VERSION ""

NS_ :

BS_:

BU_: BATSYS XRCC BMC

BO_ 3221225472 VECTOR__INDEPENDENT_SIG_MSG: 0 Vector__XXX
 SG_ VRLACFG_AvgPowerPerWHr m1 : 39|12@1+ (1,0) [0|0] "" Vector__XXX
 SG_ VRLAM_fileTransferCommand m7 : 48|16@1+ (1,0) [0|0] "" Vector__XXX
 SG_ FWSend_BlockStart_Command : 0|8@1+ (1,0) [0|0] ""  XRCC,BMC
 SG_ FWSend_BlockFragment_Command : 0|4@1+ (1,0) [0|0] ""  XRCC,BMC
 SG_ FWSend_BlockFragment_FragmentCou : 4|4@1+ (1,0) [0|15] ""  XRCC,BMC
 SG_ FWSend_BlockStart_BlockCounter : 8|16@1+ (1,0) [0|0] ""  XRCC,BMC
 SG_ FWSend_FileStart_FileSize : 4|20@1+ (1,0) [0|0] ""  XRCC,BMC
 SG_ FWSend_FileStart_BlockSize : 24|16@1+ (1,0) [0|0] ""  XRCC,BMC
 SG_ FWSend_BlockFragment_FragmentDat : 8|56@1+ (1,0) [0|0] ""  XRCC,BMC
 SG_ AUXREG_ChallengeTimeOut m0 : 24|8@1+ (1,0) [0|0] ""  XRCC,BMC
 SG_ CFGCMD_SN_3TO7BYTES m2 : 24|40@1+ (1,0) [0|0] ""  BMC
 SG_ CFGCMD_SN_8TO12BYTES m3 : 24|40@1+ (1,0) [0|0] ""  BMC
 SG_ CFGCMD_SN_LST4BYTES m4 : 24|32@1+ (1,0) [0|0] ""  BMC

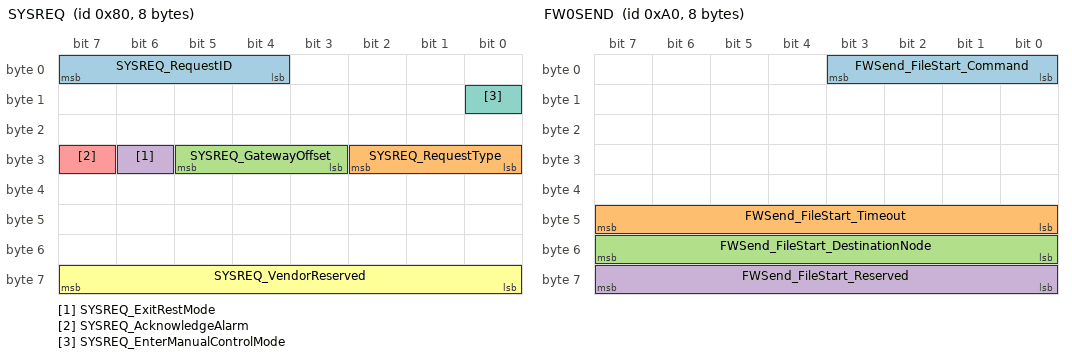
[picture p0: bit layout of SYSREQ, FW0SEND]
BO_ 128 SYSREQ: 8 BATSYS
 SG_ SYSREQ_RequestID : 4|4@1+ (1,0) [0|15] ""  BMC,XRCC
 SG_ SYSREQ_RequestType : 24|3@1+ (1,0) [0|0] ""  BMC,XRCC
 SG_ SYSREQ_GatewayOffset : 27|3@1+ (1,0) [0|0] ""  XRCC
 SG_ SYSREQ_ExitRestMode : 30|1@1+ (1,0) [0|1] ""  BMC
 SG_ SYSREQ_AcknowledgeAlarm : 31|1@1+ (1,0) [0|1] ""  BMC
 SG_ SYSREQ_VendorReserved : 56|8@1+ (1,0) [0|0] ""  BMC
 SG_ SYSREQ_EnterManualControlMode : 8|1@1+ (1,0) [0|1] ""  BMC

BO_ 256 VER: 8 BMC
 SG_ VER_Mux M : 0|4@1+ (1,0) [0|0] ""  BATSYS
 SG_ VER_ResponseID : 4|4@1+ (1,0) [0|15] ""  BATSYS
 SG_ VER_ProtocolVersion m1 : 8|8@1+ (1,0) [0|0] ""  BATSYS
 SG_ VER_SoftwareVersionMajor m1 : 16|8@1+ (1,0) [0|0] ""  BATSYS
 SG_ VER_SoftwareVersionMinor m1 : 24|8@1+ (1,0) [0|0] ""  BATSYS
 SG_ VER_SoftwareVersionBuild m1 : 32|8@1+ (1,0) [0|0] ""  BATSYS
 SG_ VER_InServiceDate m1 : 40|16@1+ (1,0) [0|0] ""  BATSYS
 SG_ VER_AttachedUPSSKU m1 : 56|8@1+ (1,0) [0|0] ""  BATSYS
 SG_ VER_ManufactureYear m2 : 8|7@1+ (1,2000) [0|0] ""  BATSYS
 SG_ VER_ManufactureDay m2 : 15|9@1+ (1,0) [0|366] "days"  BATSYS
 SG_ VER_ManufactureSerial m2 : 24|16@1+ (1,0) [0|0] ""  BATSYS
 SG_ VER_ManufactureDate m2 : 40|16@1+ (1,0) [0|65535] "days"  BATSYS
 SG_ VER_SerialNumber1 m3 : 16|48@1+ (1,0) [0|0] ""  BATSYS
 SG_ VER_SerialNumber2 m4 : 16|48@1+ (1,0) [0|0] ""  BATSYS
 SG_ VER_SerialNumber3 m5 : 16|32@1+ (1,0) [0|0] ""  BATSYS
 SG_ VER_PartNumber1 m6 : 16|48@1+ (1,0) [0|0] ""  BATSYS
 SG_ VER_PartNumber2 m7 : 16|48@1+ (1,0) [0|0] ""  BATSYS
 SG_ VER_PartNumber3 m8 : 16|32@1+ (1,0) [0|0] ""  BATSYS
 SG_ VER_SeriesConfiguration m9 : 8|8@1+ (1,0) [0|0] ""  BATSYS
 SG_ VER_ParallelConfiguration m9 : 16|8@1+ (1,0) [0|0] ""  BATSYS
 SG_ VER_DesignCapacity m9 : 24|12@1+ (1,0) [0|4094] "Whr"  BATSYS
 SG_ VER_DesignVoltage m9 : 36|9@1+ (1,0) [0|510] "volts"  BATSYS
 SG_ VER_DesignPower m9 : 48|16@1+ (1,0) [0|65534] "watts"  BATSYS
 SG_ VER_SoftwareAvailableMajor m10 : 8|8@1+ (1,0) [0|0] ""  BATSYS
 SG_ VER_SoftwareAvailableMinor m10 : 16|8@1+ (1,0) [0|0] ""  BATSYS
 SG_ VER_SoftwareAvailableBuild m10 : 24|8@1+ (1,0) [0|0] ""  BATSYS
 SG_ VER_BmFileTransferInIdle m10 : 32|1@1+ (1,0) [0|1] "flag"  BATSYS
 SG_ VER_BmFileTrsfrInPrgs m10 : 33|1@1+ (1,0) [0|1] "flag"  BATSYS
 SG_ VER_BmFileTransferInVerify m10 : 34|1@1+ (1,0) [0|1] "flag"  BATSYS
 SG_ VER_BmFileTrsfrReadyInstal m10 : 35|1@1+ (1,0) [0|1] "flag"  BATSYS
 SG_ VER_VendorCode m10 : 40|8@1+ (1,0) [0|0] ""  BATSYS
 SG_ VER_XrccFwVerString1 m11 : 8|56@1+ (1,0) [0|0] ""  BATSYS
 SG_ VER_XrccFwVerString2 m12 : 8|8@1+ (1,0) [0|0] ""  BATSYS
 SG_ VER_XrccAvlblFwVerString1 m12 : 16|48@1+ (1,0) [0|0] ""  BATSYS
 SG_ VER_XrccAvlblFwVerString2 m13 : 8|16@1+ (1,0) [0|0] ""  BATSYS

BO_ 512 MDAT: 8 BMC
 SG_ MDAT_Mux M : 0|4@1+ (1,0) [0|15] ""  BATSYS
 SG_ MDAT_ResponseID : 4|4@1+ (1,0) [0|15] ""  BATSYS
 SG_ MDAT_Reserved_01 m1 : 8|1@1+ (1,0) [0|1] "flag"  BATSYS
 SG_ MDAT_Reserved_02 m1 : 9|1@1+ (1,0) [0|1] "flag"  BATSYS
 SG_ MDAT_ShutdownImminent m1 : 10|1@1+ (1,0) [0|1] "flag"  BATSYS
 SG_ MDAT_NewFirmwareAvailable m1 : 11|1@1+ (1,0) [0|1] "flag"  BATSYS
 SG_ MDAT_RemainingCapacity m1 : 12|12@1+ (1,0) [0|4094] "Whr"  BATSYS
 SG_ MDAT_FullChargeCapacity m1 : 24|12@1+ (1,0) [0|4094] "Whr"  BATSYS
 SG_ MDAT_Voltage m1 : 36|12@1+ (0.1,0) [0|300] "volts"  BATSYS
 SG_ MDAT_Current m1 : 48|16@1+ (0.01,-325) [-325|325] "amps"  BATSYS
 SG_ MDAT_BatteryStatus m2 : 12|12@1+ (1,0) [0|1] ""  BATSYS
 SG_ MDAT_VCellMax m2 : 24|12@1+ (1,500) [500|4500] "mv"  BATSYS
 SG_ MDAT_VCellMin m2 : 36|12@1+ (1,500) [500|4500] "mv"  BATSYS
 SG_ MDAT_VCellAvg m2 : 48|12@1+ (1,500) [500|4500] "mv"  BATSYS
 SG_ MDAT_BatterySwitchOpen m2 : 60|1@1+ (1,0) [0|1] ""  BATSYS
 SG_ MDAT_TemperatureMax m3 : 16|8@1+ (1,-40) [-40|210] "deg C"  BATSYS
 SG_ MDAT_TemperatureMin m3 : 24|8@1+ (1,-40) [-40|210] "deg C"  BATSYS
 SG_ MDAT_TimeNow m3 : 32|32@1+ (0.5,0) [0|2147480000] "seconds"  BATSYS
 SG_ MDAT_VoltageBus m4 : 12|12@1+ (0.1,0) [0|300] "volts"  BATSYS
 SG_ MDAT_ChargeVoltageRequest m4 : 24|12@1+ (0.1,0) [0|300] "volts"  BATSYS
 SG_ MDAT_RunTimeCalRequired m4 : 36|1@1+ (1,0) [0|1] "flag"  BATSYS
 SG_ MDAT_RunTimeCalConditionMet m4 : 37|1@1+ (1,0) [0|1] "flag"  BATSYS
 SG_ MDAT_RTCalDischargeToLowSOC m4 : 38|1@1+ (1,0) [0|1] "flag"  BATSYS
 SG_ MDAT_RunTimeCalStayAtEmpty m4 : 39|1@1+ (1,0) [0|1] "flag"  BATSYS
 SG_ MDAT_RunTimeCalChargeToFull m4 : 40|1@1+ (1,0) [0|1] "flag"  BATSYS
 SG_ MDAT_RunTimeCalStayAtFull m4 : 41|1@1+ (1,0) [0|1] "flag"  BATSYS
 SG_ MDAT_RunTimeCalSuccess m4 : 42|1@1+ (1,0) [0|1] "flag"  BATSYS
 SG_ MDAT_RunTimeCalProcessing m4 : 43|1@1+ (1,0) [0|1] "flag"  BATSYS
 SG_ MDAT_RunTimeCalTimeout m4 : 44|1@1+ (1,0) [0|1] "flag"  BATSYS
 SG_ MDAT_ChargeCurrentMax m4 : 48|16@1+ (0.01,-325) [-325|325] "amps"  BATSYS
 SG_ MDAT_VolProtectionCov m5 : 16|1@1+ (1,0) [0|1] "flag"  BATSYS
 SG_ MDAT_VolProtectionPov m5 : 17|1@1+ (1,0) [0|1] "flag"  BATSYS
 SG_ MDAT_VolProtectionEocv m5 : 18|1@1+ (1,0) [0|1] "flag"  BATSYS
 SG_ MDAT_VolProtectionCuv m5 : 19|1@1+ (1,0) [0|1] "flag"  BATSYS
 SG_ MDAT_VolProtectionPuv m5 : 20|1@1+ (1,0) [0|1] "flag"  BATSYS
 SG_ MDAT_VolProtectionOimbv m5 : 21|1@1+ (1,0) [0|1] "flag"  BATSYS
 SG_ MDAT_CurProtectionOci m5 : 22|1@1+ (1,0) [0|1] "flag"  BATSYS
 SG_ MDAT_CurProtectionOdi_1 m5 : 23|1@1+ (1,0) [0|1] "flag"  BATSYS
 SG_ MDAT_CurProtectionOdi_2 m5 : 24|1@1+ (1,0) [0|1] "flag"  BATSYS
 SG_ MDAT_CurProtectionOdi_3 m5 : 25|1@1+ (1,0) [0|1] "flag"  BATSYS
 SG_ MDAT_CurProtectionOdi_4 m5 : 26|1@1+ (1,0) [0|1] "flag"  BATSYS
 SG_ MDAT_CurProtectionH_Odi m5 : 27|1@1+ (1,0) [0|1] "flag"  BATSYS
 SG_ MDAT_CurProtectionH_Sci m5 : 28|1@1+ (1,0) [0|1] "flag"  BATSYS
 SG_ MDAT_TemProtectionCot m5 : 29|1@1+ (1,0) [0|1] "flag"  BATSYS
 SG_ MDAT_TemProtectionDot m5 : 30|1@1+ (1,0) [0|1] "flag"  BATSYS
 SG_ MDAT_TemProtectionCut m5 : 31|1@1+ (1,0) [0|1] "flag"  BATSYS
 SG_ MDAT_TemProtectionDut m5 : 32|1@1+ (1,0) [0|1] "flag"  BATSYS
 SG_ MDAT_TemProtectionMot m5 : 33|1@1+ (1,0) [0|1] "flag"  BATSYS
 SG_ MDAT_FaultIndicateUvpf m5 : 34|1@1+ (1,0) [0|1] "flag"  BATSYS
 SG_ MDAT_FaultIndicateOvpf m5 : 35|1@1+ (1,0) [0|1] "flag"  BATSYS
 SG_ MDAT_FaultIndicateOtpf m5 : 36|1@1+ (1,0) [0|1] "flag"  BATSYS
 SG_ MDAT_FaultIndicateFusepf m5 : 37|1@1+ (1,0) [0|1] "flag"  BATSYS
 SG_ MDAT_FaultIndicateCimpf m5 : 38|1@1+ (1,0) [0|1] "flag"  BATSYS
 SG_ MDAT_FaultIndicateThopf m5 : 39|1@1+ (1,0) [0|1] "flag"  BATSYS
 SG_ MDAT_FaultIndicateThspf m5 : 40|1@1+ (1,0) [0|1] "flag"  BATSYS
 SG_ MDAT_FaultIndicateCfetpf m5 : 41|1@1+ (1,0) [0|1] "flag"  BATSYS
 SG_ MDAT_FaultIndicateDfetpf m5 : 42|1@1+ (1,0) [0|1] "flag"  BATSYS
 SG_ MDAT_UL60730_BQF m5 : 43|1@1+ (1,0) [0|1] "flag"  BATSYS
 SG_ MDAT_UL60730_MCU_IO_F m5 : 44|1@1+ (1,0) [0|1] "flag"  BATSYS
 SG_ MDAT_UL60730_MCU_CLK_F m5 : 45|1@1+ (1,0) [0|1] "flag"  BATSYS
 SG_ MDAT_UL60730_MCU_PC_F m5 : 46|1@1+ (1,0) [0|1] "flag"  BATSYS
 SG_ MDAT_UL60730_MCU_REG_F m5 : 47|1@1+ (1,0) [0|1] "flag"  BATSYS
 SG_ MDAT_UL60730_MCU_WDT_F m5 : 48|1@1+ (1,0) [0|1] "flag"  BATSYS
 SG_ MDAT_UL60730_MCU_RAM_F m5 : 49|1@1+ (1,0) [0|1] "flag"  BATSYS
 SG_ MDAT_UL60730_MCU_FLASH_F m5 : 50|1@1+ (1,0) [0|1] "flag"  BATSYS
 SG_ MDAT_UL60730_MCU_EE_F m5 : 51|1@1+ (1,0) [0|1] "flag"  BATSYS
 SG_ MDAT_GaugeCode m5 : 52|4@1+ (1,0) [0|16] ""  BATSYS
 SG_ MDAT_BmsState m5 : 56|8@1+ (1,0) [0|255] ""  BATSYS
 SG_ MDAT_TimeToFullCharge m6 : 16|16@1+ (1,0) [0|65535] ""  BATSYS
 SG_ MDAT_RemainingRunTime m6 : 32|16@1+ (1,0) [0|65535] ""  BATSYS
 SG_ MDAT_FanFault m6 : 48|1@1+ (1,0) [0|1] "flag"  BATSYS
 SG_ MDAT_TSensorDisconnected m6 : 49|1@1+ (1,0) [0|1] "flag"  BATSYS
 SG_ MDAT_ReplaceBatteryNow m6 : 50|1@1+ (1,0) [0|1] "flag"  BATSYS
 SG_ MDAT_ReplaceBPInNearFuture m6 : 51|1@1+ (1,0) [0|1] "flag"  BATSYS
 SG_ MDAT_A100xChipIssue m6 : 52|1@1+ (1,0) [0|1] "flag"  BATSYS
 SG_ MDAT_HardwareFault m6 : 53|1@1+ (1,0) [0|1] "flag"  BATSYS
 SG_ MDAT_VBus_Sense_Fault m6 : 54|1@1+ (1,0) [0|1] "flag"  BATSYS
 SG_ MDAT_VBAT_Sense_Fault m6 : 55|1@1+ (1,0) [0|1] "flag"  BATSYS
 SG_ MDAT_AFE_Fault m6 : 56|1@1+ (1,0) [0|1] "flag"  BATSYS
 SG_ MDAT_AFE_I2C_Fault m6 : 57|1@1+ (1,0) [0|1] "flag"  BATSYS
 SG_ MDAT_Trickle_Voltage_Fault m6 : 58|1@1+ (1,0) [0|1] "flag"  BATSYS
 SG_ MDAT_XrccPresent m6 : 59|1@1+ (1,0) [0|1] "flag"  BATSYS
 SG_ MDAT_BatteryModulePresent1 m6 : 60|1@1+ (1,0) [0|1] "flag"  BATSYS
 SG_ MDAT_BatteryModulePresent2 m6 : 61|1@1+ (1,0) [0|1] "flag"  BATSYS
 SG_ MDAT_BatteryModulePresent3 m6 : 62|1@1+ (1,0) [0|1] "flag"  BATSYS
 SG_ MDAT_BatteryModulePresent4 m6 : 63|1@1+ (1,0) [0|1] "flag"  BATSYS
 SG_ MDAT_ProjectBmCurrent m7 : 16|16@1+ (1,0) [0|0] "10mA"  BATSYS
 SG_ MDAT_FanPwmDutyCycly m7 : 32|8@1+ (1,0) [0|100] ""  BATSYS
 SG_ MDAT_DCIRDeltaInPercentage m8 : 16|8@1+ (1,0) [0|100] ""  BATSYS
 SG_ MDAT_FanProportionalTime m9 : 16|32@1+ (1,0) [-1|0] "second"  BATSYS
 SG_ MDAT_xrccFaultActive m8 : 8|1@1+ (1,0) [0|0] "" Vector__XXX
 SG_ MDAT_xrccFaultActiveExtended m8 : 9|7@1+ (1,0) [0|0] "" Vector__XXX
 SG_ MDAT_xrccFaultInternalComm m8 : 32|1@1+ (1,0) [0|0] "" Vector__XXX
 SG_ MDAT_xrccFaultUpStreamComm m8 : 33|1@1+ (1,0) [0|0] "" Vector__XXX

BO_ 768 CDAT0: 8 BMC
 SG_ CDAT0_Mux M : 0|4@1+ (1,0) [0|0] ""  BATSYS
 SG_ CDAT0_ResponseID : 4|4@1+ (1,0) [0|15] ""  BATSYS
 SG_ CDAT0_Temperature_01 m1 : 8|8@1+ (1,-40) [-40|210] "deg C"  BATSYS
 SG_ CDAT0_Temperature_02 m1 : 16|8@1+ (1,-40) [-40|210] "deg C"  BATSYS
 SG_ CDAT0_Temperature_03 m1 : 24|8@1+ (1,-40) [-40|210] "deg C"  BATSYS
 SG_ CDAT0_Temperature_04 m1 : 32|8@1+ (1,-40) [-40|210] "deg C"  BATSYS
 SG_ CDAT0_Temperature_05 m1 : 40|8@1+ (1,-40) [-40|210] "deg C"  BATSYS
 SG_ CDAT0_Temperature_06 m1 : 48|8@1+ (1,-40) [-40|210] "deg C"  BATSYS
 SG_ CDAT0_Temperature_07 m1 : 56|8@1+ (1,-40) [-40|210] "deg C"  BATSYS
 SG_ CDAT0_Temperature_08 m2 : 8|8@1+ (1,-40) [-40|210] "deg C"  BATSYS
 SG_ CDAT0_Temperature_09 m2 : 16|8@1+ (1,-40) [-40|210] "deg C"  BATSYS

BO_ 896 CDAT1: 8 BMC
 SG_ CDAT1_Mux M : 0|4@1+ (1,0) [0|0] ""  BATSYS
 SG_ CDAT1_ResponseID : 4|4@1+ (1,0) [0|15] ""  BATSYS
 SG_ CDAT1_CBActiveForCell_01 m1 : 8|1@1+ (1,0) [0|1] "flag"  BATSYS
 SG_ CDAT1_CBActiveForCell_02 m1 : 9|1@1+ (1,0) [0|1] "flag"  BATSYS
 SG_ CDAT1_CBActiveForCell_03 m1 : 10|1@1+ (1,0) [0|1] "flag"  BATSYS
 SG_ CDAT1_CBActiveForCell_04 m1 : 11|1@1+ (1,0) [0|1] "flag"  BATSYS
 SG_ CDAT1_CBActiveForCell_05 m1 : 12|1@1+ (1,0) [0|1] "flag"  BATSYS
 SG_ CDAT1_CBActiveForCell_06 m1 : 13|1@1+ (1,0) [0|1] "flag"  BATSYS
 SG_ CDAT1_CBActiveForCell_07 m1 : 14|1@1+ (1,0) [0|1] "flag"  BATSYS
 SG_ CDAT1_CBActiveForCell_08 m1 : 15|1@1+ (1,0) [0|1] "flag"  BATSYS
 SG_ CDAT1_CBActiveForCell_09 m1 : 16|1@1+ (1,0) [0|1] "flag"  BATSYS
 SG_ CDAT1_CBActiveForCell_10 m1 : 17|1@1+ (1,0) [0|1] "flag"  BATSYS
 SG_ CDAT1_CBActiveForCell_11 m1 : 18|1@1+ (1,0) [0|1] "flag"  BATSYS
 SG_ CDAT1_CBActiveForCell_12 m1 : 19|1@1+ (1,0) [0|1] "flag"  BATSYS
 SG_ CDAT1_CBActiveForCell_13 m1 : 20|1@1+ (1,0) [0|1] "flag"  BATSYS
 SG_ CDAT1_CBActiveForCell_14 m1 : 21|1@1+ (1,0) [0|1] "flag"  BATSYS
 SG_ CDAT1_CBActiveForCell_15 m1 : 22|1@1+ (1,0) [0|1] "flag"  BATSYS
 SG_ CDAT1_CBActiveForCell_16 m1 : 23|1@1+ (1,0) [0|1] "flag"  BATSYS
 SG_ CDAT1_CBActiveForCell_17 m1 : 24|1@1+ (1,0) [0|1] "flag"  BATSYS
 SG_ CDAT1_CBActiveForCell_18 m1 : 25|1@1+ (1,0) [0|1] "flag"  BATSYS
 SG_ CDAT1_CBActiveForCell_19 m1 : 26|1@1+ (1,0) [0|1] "flag"  BATSYS
 SG_ CDAT1_CBActiveForCell_20 m1 : 27|1@1+ (1,0) [0|1] "flag"  BATSYS
 SG_ CDAT1_CBActiveForCell_21 m1 : 28|1@1+ (1,0) [0|1] "flag"  BATSYS
 SG_ CDAT1_CBActiveForCell_22 m1 : 29|1@1+ (1,0) [0|1] "flag"  BATSYS
 SG_ CDAT1_CBActiveForCell_23 m1 : 30|1@1+ (1,0) [0|1] "flag"  BATSYS
 SG_ CDAT1_CBActiveForCell_24 m1 : 31|1@1+ (1,0) [0|1] "flag"  BATSYS
 SG_ CDAT1_CBActiveForCell_25 m1 : 32|1@1+ (1,0) [0|1] "flag"  BATSYS
 SG_ CDAT1_CBActiveForCell_26 m1 : 33|1@1+ (1,0) [0|1] "flag"  BATSYS
 SG_ CDAT1_CBActiveForCell_27 m1 : 34|1@1+ (1,0) [0|1] "flag"  BATSYS
 SG_ CDAT1_CBActiveForCell_28 m1 : 35|1@1+ (1,0) [0|1] "flag"  BATSYS
 SG_ CDAT1_CBActiveForCell_29 m1 : 36|1@1+ (1,0) [0|1] "flag"  BATSYS
 SG_ CDAT1_CBActiveForCell_30 m1 : 37|1@1+ (1,0) [0|1] "flag"  BATSYS
 SG_ CDAT1_CBActiveForCell_31 m1 : 38|1@1+ (1,0) [0|1] "flag"  BATSYS
 SG_ CDAT1_CBActiveForCell_32 m1 : 39|1@1+ (1,0) [0|1] "flag"  BATSYS
 SG_ CDAT1_CBActiveForCell_33 m1 : 40|1@1+ (1,0) [0|1] "flag"  BATSYS
 SG_ CDAT1_CBActiveForCell_34 m1 : 41|1@1+ (1,0) [0|1] "flag"  BATSYS
 SG_ CDAT1_CBActiveForCell_35 m1 : 42|1@1+ (1,0) [0|1] "flag"  BATSYS
 SG_ CDAT1_CBActiveForCell_36 m1 : 43|1@1+ (1,0) [0|1] "flag"  BATSYS
 SG_ CDAT1_CBActiveForCell_37 m1 : 44|1@1+ (1,0) [0|1] "flag"  BATSYS
 SG_ CDAT1_CBActiveForCell_38 m1 : 45|1@1+ (1,0) [0|1] "flag"  BATSYS
 SG_ CDAT1_CBActiveForCell_39 m1 : 46|1@1+ (1,0) [0|1] "flag"  BATSYS
 SG_ CDAT1_CBActiveForCell_40 m1 : 47|1@1+ (1,0) [0|1] "flag"  BATSYS
 SG_ CDAT1_CBActiveForCell_41 m1 : 48|1@1+ (1,0) [0|1] "flag"  BATSYS
 SG_ CDAT1_CBActiveForCell_42 m1 : 49|1@1+ (1,0) [0|1] "flag"  BATSYS
 SG_ CDAT1_CBActiveForCell_43 m1 : 50|1@1+ (1,0) [0|1] "flag"  BATSYS
 SG_ CDAT1_CBActiveForCell_44 m1 : 51|1@1+ (1,0) [0|1] "flag"  BATSYS
 SG_ CDAT1_CBActiveForCell_45 m1 : 52|1@1+ (1,0) [0|1] "flag"  BATSYS
 SG_ CDAT1_CBActiveForCell_46 m1 : 53|1@1+ (1,0) [0|1] "flag"  BATSYS
 SG_ CDAT1_CBActiveForCell_47 m1 : 54|1@1+ (1,0) [0|1] "flag"  BATSYS
 SG_ CDAT1_CBActiveForCell_48 m1 : 55|1@1+ (1,0) [0|1] "flag"  BATSYS
 SG_ CDAT1_CBActiveForCell_49 m1 : 56|1@1+ (1,0) [0|1] "flag"  BATSYS
 SG_ CDAT1_CBActiveForCell_50 m1 : 57|3@1+ (1,0) [0|1] "flag"  BATSYS
 SG_ CDAT1_OverVoltageAtCell_01 m2 : 8|1@1+ (1,0) [0|1] "flag"  BATSYS
 SG_ CDAT1_OverVoltageAtCell_02 m2 : 9|1@1+ (1,0) [0|1] "flag"  BATSYS
 SG_ CDAT1_OverVoltageAtCell_03 m2 : 10|1@1+ (1,0) [0|1] "flag"  BATSYS
 SG_ CDAT1_OverVoltageAtCell_04 m2 : 11|1@1+ (1,0) [0|1] "flag"  BATSYS
 SG_ CDAT1_OverVoltageAtCell_05 m2 : 12|1@1+ (1,0) [0|1] "flag"  BATSYS
 SG_ CDAT1_OverVoltageAtCell_06 m2 : 13|1@1+ (1,0) [0|1] "flag"  BATSYS
 SG_ CDAT1_OverVoltageAtCell_07 m2 : 14|1@1+ (1,0) [0|1] "flag"  BATSYS
 SG_ CDAT1_OverVoltageAtCell_08 m2 : 15|1@1+ (1,0) [0|1] "flag"  BATSYS
 SG_ CDAT1_OverVoltageAtCell_09 m2 : 16|1@1+ (1,0) [0|1] "flag"  BATSYS
 SG_ CDAT1_OverVoltageAtCell_10 m2 : 17|1@1+ (1,0) [0|1] "flag"  BATSYS
 SG_ CDAT1_OverVoltageAtCell_11 m2 : 18|1@1+ (1,0) [0|1] "flag"  BATSYS
 SG_ CDAT1_OverVoltageAtCell_12 m2 : 19|1@1+ (1,0) [0|1] "flag"  BATSYS
 SG_ CDAT1_OverVoltageAtCell_13 m2 : 20|1@1+ (1,0) [0|1] "flag"  BATSYS
 SG_ CDAT1_OverVoltageAtCell_14 m2 : 21|1@1+ (1,0) [0|1] "flag"  BATSYS
 SG_ CDAT1_OverVoltageAtCell_15 m2 : 22|1@1+ (1,0) [0|1] "flag"  BATSYS
 SG_ CDAT1_OverVoltageAtCell_16 m2 : 23|1@1+ (1,0) [0|1] "flag"  BATSYS
 SG_ CDAT1_OverVoltageAtCell_17 m2 : 24|1@1+ (1,0) [0|1] "flag"  BATSYS
 SG_ CDAT1_OverVoltageAtCell_18 m2 : 25|1@1+ (1,0) [0|1] "flag"  BATSYS
 SG_ CDAT1_OverVoltageAtCell_19 m2 : 26|1@1+ (1,0) [0|1] "flag"  BATSYS
 SG_ CDAT1_OverVoltageAtCell_20 m2 : 27|1@1+ (1,0) [0|1] "flag"  BATSYS
 SG_ CDAT1_OverVoltageAtCell_21 m2 : 28|1@1+ (1,0) [0|1] "flag"  BATSYS
 SG_ CDAT1_OverVoltageAtCell_22 m2 : 29|1@1+ (1,0) [0|1] "flag"  BATSYS
 SG_ CDAT1_OverVoltageAtCell_23 m2 : 30|1@1+ (1,0) [0|1] "flag"  BATSYS
 SG_ CDAT1_OverVoltageAtCell_24 m2 : 31|1@1+ (1,0) [0|1] "flag"  BATSYS
 SG_ CDAT1_OverVoltageAtCell_25 m2 : 32|1@1+ (1,0) [0|1] "flag"  BATSYS
 SG_ CDAT1_OverVoltageAtCell_26 m2 : 33|1@1+ (1,0) [0|1] "flag"  BATSYS
 SG_ CDAT1_OverVoltageAtCell_27 m2 : 34|1@1+ (1,0) [0|1] "flag"  BATSYS
 SG_ CDAT1_OverVoltageAtCell_28 m2 : 35|1@1+ (1,0) [0|1] "flag"  BATSYS
 SG_ CDAT1_OverVoltageAtCell_29 m2 : 36|1@1+ (1,0) [0|1] "flag"  BATSYS
 SG_ CDAT1_OverVoltageAtCell_30 m2 : 37|1@1+ (1,0) [0|1] "flag"  BATSYS
 SG_ CDAT1_OverVoltageAtCell_31 m2 : 38|1@1+ (1,0) [0|1] "flag"  BATSYS
 SG_ CDAT1_OverVoltageAtCell_32 m2 : 39|1@1+ (1,0) [0|1] "flag"  BATSYS
 SG_ CDAT1_OverVoltageAtCell_33 m2 : 40|1@1+ (1,0) [0|1] "flag"  BATSYS
 SG_ CDAT1_OverVoltageAtCell_34 m2 : 41|1@1+ (1,0) [0|1] "flag"  BATSYS
 SG_ CDAT1_OverVoltageAtCell_35 m2 : 42|1@1+ (1,0) [0|1] "flag"  BATSYS
 SG_ CDAT1_OverVoltageAtCell_36 m2 : 43|1@1+ (1,0) [0|1] "flag"  BATSYS
 SG_ CDAT1_OverVoltageAtCell_37 m2 : 44|1@1+ (1,0) [0|1] "flag"  BATSYS
 SG_ CDAT1_OverVoltageAtCell_38 m2 : 45|1@1+ (1,0) [0|1] "flag"  BATSYS
 SG_ CDAT1_OverVoltageAtCell_39 m2 : 46|1@1+ (1,0) [0|1] "flag"  BATSYS
 SG_ CDAT1_OverVoltageAtCell_40 m2 : 47|1@1+ (1,0) [0|1] "flag"  BATSYS
 SG_ CDAT1_OverVoltageAtCell_41 m2 : 48|1@1+ (1,0) [0|1] "flag"  BATSYS
 SG_ CDAT1_OverVoltageAtCell_42 m2 : 49|1@1+ (1,0) [0|1] "flag"  BATSYS
 SG_ CDAT1_OverVoltageAtCell_43 m2 : 50|1@1+ (1,0) [0|1] "flag"  BATSYS
 SG_ CDAT1_OverVoltageAtCell_44 m2 : 51|1@1+ (1,0) [0|1] "flag"  BATSYS
 SG_ CDAT1_OverVoltageAtCell_45 m2 : 52|1@1+ (1,0) [0|1] "flag"  BATSYS
 SG_ CDAT1_OverVoltageAtCell_46 m2 : 53|1@1+ (1,0) [0|1] "flag"  BATSYS
 SG_ CDAT1_OverVoltageAtCell_47 m2 : 54|1@1+ (1,0) [0|1] "flag"  BATSYS
 SG_ CDAT1_OverVoltageAtCell_48 m2 : 55|1@1+ (1,0) [0|1] "flag"  BATSYS
 SG_ CDAT1_OverVoltageAtCell_49 m2 : 56|1@1+ (1,0) [0|1] "flag"  BATSYS
 SG_ CDAT1_OverVoltageAtCell_50 m2 : 57|1@1+ (1,0) [0|1] "flag"  BATSYS
 SG_ CDAT1_UnderVoltageAtCell_01 m3 : 8|1@1+ (1,0) [0|1] "flag"  BATSYS
 SG_ CDAT1_UnderVoltageAtCell_02 m3 : 9|1@1+ (1,0) [0|1] "flag"  BATSYS
 SG_ CDAT1_UnderVoltageAtCell_03 m3 : 10|1@1+ (1,0) [0|1] "flag"  BATSYS
 SG_ CDAT1_UnderVoltageAtCell_04 m3 : 11|1@1+ (1,0) [0|1] "flag"  BATSYS
 SG_ CDAT1_UnderVoltageAtCell_05 m3 : 12|1@1+ (1,0) [0|1] "flag"  BATSYS
 SG_ CDAT1_UnderVoltageAtCell_06 m3 : 13|1@1+ (1,0) [0|1] "flag"  BATSYS
 SG_ CDAT1_UnderVoltageAtCell_07 m3 : 14|1@1+ (1,0) [0|1] "flag"  BATSYS
 SG_ CDAT1_UnderVoltageAtCell_08 m3 : 15|1@1+ (1,0) [0|1] "flag"  BATSYS
 SG_ CDAT1_UnderVoltageAtCell_09 m3 : 16|1@1+ (1,0) [0|1] "flag"  BATSYS
 SG_ CDAT1_UnderVoltageAtCell_10 m3 : 17|1@1+ (1,0) [0|1] "flag"  BATSYS
 SG_ CDAT1_UnderVoltageAtCell_11 m3 : 18|1@1+ (1,0) [0|1] "flag"  BATSYS
 SG_ CDAT1_UnderVoltageAtCell_12 m3 : 19|1@1+ (1,0) [0|1] "flag"  BATSYS
 SG_ CDAT1_UnderVoltageAtCell_13 m3 : 20|1@1+ (1,0) [0|1] "flag"  BATSYS
 SG_ CDAT1_UnderVoltageAtCell_14 m3 : 21|1@1+ (1,0) [0|1] "flag"  BATSYS
 SG_ CDAT1_UnderVoltageAtCell_15 m3 : 22|1@1+ (1,0) [0|1] "flag"  BATSYS
 SG_ CDAT1_UnderVoltageAtCell_16 m3 : 23|1@1+ (1,0) [0|1] "flag"  BATSYS
 SG_ CDAT1_UnderVoltageAtCell_17 m3 : 24|1@1+ (1,0) [0|1] "flag"  BATSYS
 SG_ CDAT1_UnderVoltageAtCell_18 m3 : 25|1@1+ (1,0) [0|1] "flag"  BATSYS
 SG_ CDAT1_UnderVoltageAtCell_19 m3 : 26|1@1+ (1,0) [0|1] "flag"  BATSYS
 SG_ CDAT1_UnderVoltageAtCell_20 m3 : 27|1@1+ (1,0) [0|1] "flag"  BATSYS
 SG_ CDAT1_UnderVoltageAtCell_21 m3 : 28|1@1+ (1,0) [0|1] "flag"  BATSYS
 SG_ CDAT1_UnderVoltageAtCell_22 m3 : 29|1@1+ (1,0) [0|1] "flag"  BATSYS
 SG_ CDAT1_UnderVoltageAtCell_23 m3 : 30|1@1+ (1,0) [0|1] "flag"  BATSYS
 SG_ CDAT1_UnderVoltageAtCell_24 m3 : 31|1@1+ (1,0) [0|1] "flag"  BATSYS
 SG_ CDAT1_UnderVoltageAtCell_25 m3 : 32|1@1+ (1,0) [0|1] "flag"  BATSYS
 SG_ CDAT1_UnderVoltageAtCell_26 m3 : 33|1@1+ (1,0) [0|1] "flag"  BATSYS
 SG_ CDAT1_UnderVoltageAtCell_27 m3 : 34|1@1+ (1,0) [0|1] "flag"  BATSYS
 SG_ CDAT1_UnderVoltageAtCell_28 m3 : 35|1@1+ (1,0) [0|1] "flag"  BATSYS
 SG_ CDAT1_UnderVoltageAtCell_29 m3 : 36|1@1+ (1,0) [0|1] "flag"  BATSYS
 SG_ CDAT1_UnderVoltageAtCell_30 m3 : 37|1@1+ (1,0) [0|1] "flag"  BATSYS
 SG_ CDAT1_UnderVoltageAtCell_31 m3 : 38|1@1+ (1,0) [0|1] "flag"  BATSYS
 SG_ CDAT1_UnderVoltageAtCell_32 m3 : 39|1@1+ (1,0) [0|1] "flag"  BATSYS
 SG_ CDAT1_UnderVoltageAtCell_33 m3 : 40|1@1+ (1,0) [0|1] "flag"  BATSYS
 SG_ CDAT1_UnderVoltageAtCell_34 m3 : 41|1@1+ (1,0) [0|1] "flag"  BATSYS
 SG_ CDAT1_UnderVoltageAtCell_35 m3 : 42|1@1+ (1,0) [0|1] "flag"  BATSYS
 SG_ CDAT1_UnderVoltageAtCell_36 m3 : 43|1@1+ (1,0) [0|1] "flag"  BATSYS
 SG_ CDAT1_UnderVoltageAtCell_37 m3 : 44|1@1+ (1,0) [0|1] "flag"  BATSYS
 SG_ CDAT1_UnderVoltageAtCell_38 m3 : 45|1@1+ (1,0) [0|1] "flag"  BATSYS
 SG_ CDAT1_UnderVoltageAtCell_39 m3 : 46|1@1+ (1,0) [0|1] "flag"  BATSYS
 SG_ CDAT1_UnderVoltageAtCell_40 m3 : 47|1@1+ (1,0) [0|1] "flag"  BATSYS
 SG_ CDAT1_UnderVoltageAtCell_41 m3 : 48|1@1+ (1,0) [0|1] "flag"  BATSYS
 SG_ CDAT1_UnderVoltageAtCell_42 m3 : 49|1@1+ (1,0) [0|1] "flag"  BATSYS
 SG_ CDAT1_UnderVoltageAtCell_43 m3 : 50|1@1+ (1,0) [0|1] "flag"  BATSYS
 SG_ CDAT1_UnderVoltageAtCell_44 m3 : 51|1@1+ (1,0) [0|1] "flag"  BATSYS
 SG_ CDAT1_UnderVoltageAtCell_45 m3 : 52|1@1+ (1,0) [0|1] "flag"  BATSYS
 SG_ CDAT1_UnderVoltageAtCell_46 m3 : 53|1@1+ (1,0) [0|1] "flag"  BATSYS
 SG_ CDAT1_UnderVoltageAtCell_47 m3 : 54|1@1+ (1,0) [0|1] "flag"  BATSYS
 SG_ CDAT1_UnderVoltageAtCell_48 m3 : 55|1@1+ (1,0) [0|1] "flag"  BATSYS
 SG_ CDAT1_UnderVoltageAtCell_49 m3 : 56|1@1+ (1,0) [0|1] "flag"  BATSYS
 SG_ CDAT1_UnderVoltageAtCell_50 m3 : 57|1@1+ (1,0) [0|1] "flag"  BATSYS
 SG_ CDAT1_EndOfLifeAtCell_01 m5 : 8|1@1+ (1,0) [0|1] "flag"  BATSYS
 SG_ CDAT1_EndOfLifeAtCell_02 m5 : 9|1@1+ (1,0) [0|1] "flag"  BATSYS
 SG_ CDAT1_EndOfLifeAtCell_03 m5 : 10|1@1+ (1,0) [0|1] "flag"  BATSYS
 SG_ CDAT1_EndOfLifeAtCell_04 m5 : 11|1@1+ (1,0) [0|1] "flag"  BATSYS
 SG_ CDAT1_EndOfLifeAtCell_05 m5 : 12|1@1+ (1,0) [0|1] "flag"  BATSYS
 SG_ CDAT1_EndOfLifeAtCell_06 m5 : 13|1@1+ (1,0) [0|1] "flag"  BATSYS
 SG_ CDAT1_EndOfLifeAtCell_07 m5 : 14|1@1+ (1,0) [0|1] "flag"  BATSYS
 SG_ CDAT1_EndOfLifeAtCell_08 m5 : 15|1@1+ (1,0) [0|1] "flag"  BATSYS
 SG_ CDAT1_EndOfLifeAtCell_09 m5 : 16|1@1+ (1,0) [0|1] "flag"  BATSYS
 SG_ CDAT1_EndOfLifeAtCell_10 m5 : 17|1@1+ (1,0) [0|1] "flag"  BATSYS
 SG_ CDAT1_EndOfLifeAtCell_11 m5 : 18|1@1+ (1,0) [0|1] "flag"  BATSYS
 SG_ CDAT1_EndOfLifeAtCell_12 m5 : 19|1@1+ (1,0) [0|1] "flag"  BATSYS
 SG_ CDAT1_EndOfLifeAtCell_13 m5 : 20|1@1+ (1,0) [0|1] "flag"  BATSYS
 SG_ CDAT1_EndOfLifeAtCell_14 m5 : 21|1@1+ (1,0) [0|1] "flag"  BATSYS
 SG_ CDAT1_EndOfLifeAtCell_15 m5 : 22|1@1+ (1,0) [0|1] "flag"  BATSYS
 SG_ CDAT1_EndOfLifeAtCell_16 m5 : 23|1@1+ (1,0) [0|1] "flag"  BATSYS
 SG_ CDAT1_EndOfLifeAtCell_17 m5 : 24|1@1+ (1,0) [0|1] "flag"  BATSYS
 SG_ CDAT1_EndOfLifeAtCell_18 m5 : 25|1@1+ (1,0) [0|1] "flag"  BATSYS
 SG_ CDAT1_EndOfLifeAtCell_19 m5 : 26|1@1+ (1,0) [0|1] "flag"  BATSYS
 SG_ CDAT1_EndOfLifeAtCell_20 m5 : 27|1@1+ (1,0) [0|1] "flag"  BATSYS
 SG_ CDAT1_EndOfLifeAtCell_21 m5 : 28|1@1+ (1,0) [0|1] "flag"  BATSYS
 SG_ CDAT1_EndOfLifeAtCell_22 m5 : 29|1@1+ (1,0) [0|1] "flag"  BATSYS
 SG_ CDAT1_EndOfLifeAtCell_23 m5 : 30|1@1+ (1,0) [0|1] "flag"  BATSYS
 SG_ CDAT1_EndOfLifeAtCell_24 m5 : 31|1@1+ (1,0) [0|1] "flag"  BATSYS
 SG_ CDAT1_EndOfLifeAtCell_25 m5 : 32|1@1+ (1,0) [0|1] "flag"  BATSYS
 SG_ CDAT1_EndOfLifeAtCell_26 m5 : 33|1@1+ (1,0) [0|1] "flag"  BATSYS
 SG_ CDAT1_EndOfLifeAtCell_27 m5 : 34|1@1+ (1,0) [0|1] "flag"  BATSYS
 SG_ CDAT1_EndOfLifeAtCell_28 m5 : 35|1@1+ (1,0) [0|1] "flag"  BATSYS
 SG_ CDAT1_EndOfLifeAtCell_29 m5 : 36|1@1+ (1,0) [0|1] "flag"  BATSYS
 SG_ CDAT1_EndOfLifeAtCell_30 m5 : 37|1@1+ (1,0) [0|1] "flag"  BATSYS
 SG_ CDAT1_EndOfLifeAtCell_31 m5 : 38|1@1+ (1,0) [0|1] "flag"  BATSYS
 SG_ CDAT1_EndOfLifeAtCell_32 m5 : 39|1@1+ (1,0) [0|1] "flag"  BATSYS
 SG_ CDAT1_EndOfLifeAtCell_33 m5 : 40|1@1+ (1,0) [0|1] "flag"  BATSYS
 SG_ CDAT1_EndOfLifeAtCell_34 m5 : 41|1@1+ (1,0) [0|1] "flag"  BATSYS
 SG_ CDAT1_EndOfLifeAtCell_35 m5 : 42|1@1+ (1,0) [0|1] "flag"  BATSYS
 SG_ CDAT1_EndOfLifeAtCell_36 m5 : 43|1@1+ (1,0) [0|1] "flag"  BATSYS
 SG_ CDAT1_EndOfLifeAtCell_37 m5 : 44|1@1+ (1,0) [0|1] "flag"  BATSYS
 SG_ CDAT1_EndOfLifeAtCell_38 m5 : 45|1@1+ (1,0) [0|1] "flag"  BATSYS
 SG_ CDAT1_EndOfLifeAtCell_39 m5 : 46|1@1+ (1,0) [0|1] "flag"  BATSYS
 SG_ CDAT1_EndOfLifeAtCell_40 m5 : 47|1@1+ (1,0) [0|1] "flag"  BATSYS
 SG_ CDAT1_EndOfLifeAtCell_41 m5 : 48|1@1+ (1,0) [0|1] "flag"  BATSYS
 SG_ CDAT1_EndOfLifeAtCell_42 m5 : 49|1@1+ (1,0) [0|1] "flag"  BATSYS
 SG_ CDAT1_EndOfLifeAtCell_43 m5 : 50|1@1+ (1,0) [0|1] "flag"  BATSYS
 SG_ CDAT1_EndOfLifeAtCell_44 m5 : 51|1@1+ (1,0) [0|1] "flag"  BATSYS
 SG_ CDAT1_EndOfLifeAtCell_45 m5 : 52|1@1+ (1,0) [0|1] "flag"  BATSYS
 SG_ CDAT1_EndOfLifeAtCell_46 m5 : 53|1@1+ (1,0) [0|1] "flag"  BATSYS
 SG_ CDAT1_EndOfLifeAtCell_47 m5 : 54|1@1+ (1,0) [0|1] "flag"  BATSYS
 SG_ CDAT1_EndOfLifeAtCell_48 m5 : 55|1@1+ (1,0) [0|1] "flag"  BATSYS
 SG_ CDAT1_EndOfLifeAtCell_49 m5 : 56|1@1+ (1,0) [0|1] "flag"  BATSYS
 SG_ CDAT1_EndOfLifeAtCell_50 m5 : 57|1@1+ (1,0) [0|1] "flag"  BATSYS

BO_ 1024 CDAT2: 8 BMC
 SG_ CDAT2_Mux M : 0|4@1+ (1,0) [0|0] ""  BATSYS
 SG_ CDAT2_ResponseID : 4|4@1+ (1,0) [0|15] ""  BATSYS
 SG_ CDAT2_VCell_1 m1 : 16|12@1+ (1,500) [500|4500] "mv"  BATSYS
 SG_ CDAT2_VCell_2 m1 : 28|12@1+ (1,500) [500|4500] "mv"  BATSYS
 SG_ CDAT2_VCell_3 m1 : 40|12@1+ (1,500) [500|4500] "mv"  BATSYS
 SG_ CDAT2_VCell_4 m1 : 52|12@1+ (1,500) [500|4500] "mv"  BATSYS
 SG_ CDAT2_VCell_5 m2 : 16|12@1+ (1,500) [500|4500] "mv"  BATSYS
 SG_ CDAT2_VCell_6 m2 : 28|12@1+ (1,500) [500|4500] "mv"  BATSYS
 SG_ CDAT2_VCell_7 m2 : 40|12@1+ (1,500) [500|4500] "mv"  BATSYS
 SG_ CDAT2_VCell_8 m2 : 52|12@1+ (1,500) [500|4500] "mv"  BATSYS
 SG_ CDAT2_VCell_9 m3 : 16|12@1+ (1,500) [500|4500] "mv"  BATSYS
 SG_ CDAT2_VCell_10 m3 : 28|12@1+ (1,500) [500|4500] "mv"  BATSYS
 SG_ CDAT2_VCell_11 m3 : 40|12@1+ (1,500) [500|4500] "mv"  BATSYS
 SG_ CDAT2_VCell_12 m3 : 52|12@1+ (1,500) [500|4500] "mv"  BATSYS
 SG_ CDAT2_VCell_13 m4 : 16|12@1+ (1,500) [500|4500] "mv"  BATSYS
 SG_ CDAT2_VCell_14 m4 : 28|12@1+ (1,500) [500|4500] "mv"  BATSYS
 SG_ CDAT2_VCell_15 m4 : 40|12@1+ (1,500) [500|4500] "mv"  BATSYS
 SG_ CDAT2_VCell_16 m4 : 52|12@1+ (1,500) [500|4500] "mv"  BATSYS
 SG_ CDAT2_VCell_17 m5 : 16|12@1+ (1,500) [500|4500] "mv"  BATSYS
 SG_ CDAT2_VCell_18 m5 : 28|12@1+ (1,500) [500|4500] "mv"  BATSYS
 SG_ CDAT2_VCell_19 m5 : 40|12@1+ (1,500) [500|4500] "mv"  BATSYS
 SG_ CDAT2_VCell_20 m5 : 52|12@1+ (1,500) [500|4500] "mv"  BATSYS
 SG_ CDAT2_VCell_21 m6 : 16|12@1+ (1,500) [500|4500] "mv"  BATSYS
 SG_ CDAT2_VCell_22 m6 : 28|12@1+ (1,500) [500|4500] "mv"  BATSYS
 SG_ CDAT2_VCell_23 m6 : 40|12@1+ (1,500) [500|4500] "mv"  BATSYS
 SG_ CDAT2_VCell_24 m6 : 52|12@1+ (1,500) [500|4500] "mv"  BATSYS
 SG_ CDAT2_VCell_25 m7 : 16|12@1+ (1,500) [500|4500] "mv"  BATSYS
 SG_ CDAT2_VCell_26 m7 : 28|12@1+ (1,500) [500|4500] "mv"  BATSYS
 SG_ CDAT2_VCell_27 m7 : 40|12@1+ (1,500) [500|4500] "mv"  BATSYS
 SG_ CDAT2_VCell_28 m7 : 52|12@1+ (1,500) [500|4500] "mv"  BATSYS
 SG_ CDAT2_VCell_29 m8 : 16|12@1+ (1,500) [500|4500] "mv"  BATSYS
 SG_ CDAT2_VCell_30 m8 : 28|12@1+ (1,500) [500|4500] "mv"  BATSYS
 SG_ CDAT2_VCell_31 m8 : 40|12@1+ (1,500) [500|4500] "mv"  BATSYS
 SG_ CDAT2_VCell_32 m8 : 52|12@1+ (1,500) [500|4500] "mv"  BATSYS
 SG_ CDAT2_VCell_33 m9 : 16|12@1+ (1,500) [500|4500] "mv"  BATSYS
 SG_ CDAT2_VCell_34 m9 : 28|12@1+ (1,500) [500|4500] "mv"  BATSYS
 SG_ CDAT2_VCell_35 m9 : 40|12@1+ (1,500) [500|4500] "mv"  BATSYS
 SG_ CDAT2_VCell_36 m9 : 52|12@1+ (1,500) [500|4500] "mv"  BATSYS
 SG_ CDAT2_VCell_37 m10 : 16|12@1+ (1,500) [500|4500] "mv"  BATSYS
 SG_ CDAT2_VCell_38 m10 : 28|12@1+ (1,500) [500|4500] "mv"  BATSYS
 SG_ CDAT2_VCell_39 m10 : 40|12@1+ (1,500) [500|4500] "mv"  BATSYS
 SG_ CDAT2_VCell_40 m10 : 52|12@1+ (1,500) [500|4500] "mv"  BATSYS
 SG_ CDAT2_VCell_41 m11 : 16|12@1+ (1,500) [500|4500] "mv"  BATSYS
 SG_ CDAT2_VCell_42 m11 : 28|12@1+ (1,500) [500|4500] "mv"  BATSYS
 SG_ CDAT2_VCell_43 m11 : 40|12@1+ (1,500) [500|4500] "mv"  BATSYS
 SG_ CDAT2_VCell_44 m11 : 52|12@1+ (1,500) [500|4500] "mv"  BATSYS
 SG_ CDAT2_VCell_45 m12 : 16|12@1+ (1,500) [500|4500] "mv"  BATSYS
 SG_ CDAT2_VCell_46 m12 : 28|12@1+ (1,500) [500|4500] "mv"  BATSYS
 SG_ CDAT2_VCell_47 m12 : 40|12@1+ (1,500) [500|4500] "mv"  BATSYS
 SG_ CDAT2_VCell_48 m12 : 52|12@1+ (1,500) [500|4500] "mv"  BATSYS
 SG_ CDAT2_VCell_49 m13 : 16|12@1+ (1,500) [500|4500] "mv"  BATSYS
 SG_ CDAT2_VCell_50 m13 : 28|12@1+ (1,500) [500|4500] "mv"  BATSYS

BO_ 1920 VDAT: 8 BMC
 SG_ VDAT_Mux M : 0|4@1+ (1,0) [0|15] ""  BATSYS
 SG_ VDAT_ResponseID : 4|4@1+ (1,0) [0|0] ""  BATSYS
 SG_ VDAT_Factor m1 : 8|8@1+ (0.01,0) [100|200] ""  BATSYS
 SG_ VDAT_LowerSoc m1 : 16|10@1+ (0.1,0) [0|1000] ""  BATSYS
 SG_ VDAT_OneAbsoluteCycleRange m1 : 36|1@1+ (1,0) [0|1] ""  BATSYS
 SG_ VDAT_SoC_EKF_YUser_SoCRange m1 : 26|10@1+ (0.1,0) [0|1000] ""  BATSYS
 SG_ VDAT_LastEKFSoCRange m1 : 37|10@1+ (0.1,0) [0|1000] ""  BATSYS
 SG_ VDAT_BLVersion_Major m2 : 8|8@1+ (1,0) [0|255] ""  BATSYS
 SG_ VDAT_BLVersion_Minor m2 : 16|8@1+ (1,0) [0|255] ""  BATSYS
 SG_ VDAT_BLVersion_Build m2 : 24|8@1+ (1,0) [0|255] ""  BATSYS
 SG_ VDAT_RTCTS_YEAR m2 : 32|6@1+ (1,2000) [0|64] "Year"  BATSYS
 SG_ VDAT_RTCTS_MON m2 : 38|4@1+ (1,0) [1|12] "Month"  BATSYS
 SG_ VDAT_RTCTS_DAY m2 : 42|5@1+ (1,0) [1|366] "Days"  BATSYS
 SG_ VDAT_RTCTS_HOUR m2 : 47|5@1+ (1,0) [0|24] "Hour"  BATSYS
 SG_ VDAT_RTCTS_MIN m2 : 52|6@1+ (1,0) [0|60] "Minute"  BATSYS
 SG_ VDAT_RTCTS_SEC m2 : 58|6@1+ (1,0) [0|60] "Sec"  BATSYS
 SG_ VDAT_SoC m3 : 8|10@1+ (0.1,0) [0|1000] "Percentage"  BATSYS
 SG_ VDAT_EOC m3 : 18|1@1+ (1,0) [0|1] "" Vector__XXX

BO_ 1792 LDAT: 8 BMC
 SG_ LDAT_Mux M : 0|4@1+ (1,0) [0|0] ""  BATSYS
 SG_ LDAT_ResponseID : 4|4@1+ (1,0) [0|15] ""  BATSYS
 SG_ LDAT_DischargeEnergy_Total m1 : 8|32@1+ (1,0) [0|0] "Whr"  BATSYS
 SG_ LDAT_CellVoltage_Min m1 : 40|12@1+ (1,500) [500|4500] "mv"  BATSYS
 SG_ LDAT_CellVoltage_Max m1 : 52|12@1+ (1,500) [500|4500] "mv"  BATSYS
 SG_ LDAT_ChargeEnergy_Total m2 : 8|32@1+ (1,0) [0|0] "Whr"  BATSYS
 SG_ LDAT_InternalVoltage_Min m2 : 40|12@1+ (0.1,0) [0|300] "volts"  BATSYS
 SG_ LDAT_InternalVoltage_Max m2 : 52|12@1+ (0.1,0) [0|300] "volts"  BATSYS
 SG_ LDAT_TimeDischarging_Total m3 : 8|32@1+ (0.5,0) [0|2147480000] "seconds"  BATSYS
 SG_ LDAT_DischargeCurrent_Max m3 : 40|16@1+ (0.01,-325) [-325|325] "amps"  BATSYS
 SG_ LDAT_Temperature_Max m3 : 56|8@1+ (1,-40) [-40|210] "deg C"  BATSYS
 SG_ LDAT_TimeCharging_Total m4 : 8|32@1+ (0.5,0) [0|2147480000] "seconds"  BATSYS
 SG_ LDAT_ChargeCurrent_Max m4 : 40|16@1+ (0.01,-325) [-325|325] "amps"  BATSYS
 SG_ LDAT_Temperature_Min m4 : 56|8@1+ (1,-40) [-40|210] "deg C"  BATSYS
 SG_ LDAT_TimeResting_Total m5 : 8|32@1+ (0.5,0) [0|2147480000] "seconds"  BATSYS
 SG_ LDAT_ChargePower_Max m5 : 40|16@1+ (1,0) [0|65534] "watts"  BATSYS
 SG_ LDAT_Temperature_Avg m5 : 56|8@1+ (1,-40) [-40|210] "deg C"  BATSYS
 SG_ LDAT_TimeBrainsUp_Total m6 : 8|32@1+ (0.5,0) [0|2147480000] "seconds"  BATSYS
 SG_ LDAT_DischargePower_Max m6 : 40|16@1+ (1,0) [0|65534] "watts"  BATSYS
 SG_ LDAT_NDischargeEvents m7 : 8|16@1+ (1,0) [0|65534] ""  BATSYS
 SG_ LDAT_NDeepDischargeEvents m7 : 24|16@1+ (1,0) [0|65534] ""  BATSYS
 SG_ LDAT_DaysReamingLifeExpired m7 : 40|16@1+ (1,0) [0|65535] "day"  BATSYS
 SG_ LDAT_DCIRCell_Min m8 : 8|16@1+ (1,0) [0|65535] "mohm"  BATSYS
 SG_ LDAT_DCIRString m8 : 24|16@1+ (1,0) [0|65535] "mohm"  BATSYS
 SG_ LDAT_TimeShipMode_Total m8 : 40|16@1+ (0.5,0) [0|2147480000] "hours"  BATSYS
 SG_ LDAT_SOHInternal m8 : 56|8@1+ (1,0) [0|100] "percent"  BATSYS
 SG_ LDAT_DischargeLT20PerCntr m9 : 8|16@1+ (1,0) [0|65535] ""  BATSYS
 SG_ LDAT_DischgG20LT40PerCntr m9 : 24|16@1+ (1,0) [0|65535] ""  BATSYS
 SG_ LDAT_DischgG40LT60PerCntr m9 : 40|16@1+ (1,0) [0|65535] ""  BATSYS
 SG_ LDAT_DischgG60LT80PerCntr m10 : 8|16@1+ (1,0) [0|65535] ""  BATSYS
 SG_ LDAT_DischgG80PerCntr m10 : 24|16@1+ (1,0) [0|65535] ""  BATSYS

BO_ 160 FW0SEND: 8 BATSYS
 SG_ FWSend_FileStart_Command : 0|4@1+ (1,0) [0|0] ""  XRCC,BMC
 SG_ FWSend_FileStart_Timeout : 40|8@1+ (0.1,0) [0|255] "second"  XRCC,BMC
 SG_ FWSend_FileStart_DestinationNode : 48|8@1+ (1,0) [0|0] ""  XRCC,BMC
 SG_ FWSend_FileStart_Reserved : 56|8@1+ (1,0) [0|0] ""  XRCC,BMC

BO_ 161 FW1SEND: 8 BATSYS

BO_ 176 FWINSTALL: 8 BATSYS
 SG_ NodeAddress : 0|8@1+ (1,0) [0|255] ""  BMC,XRCC

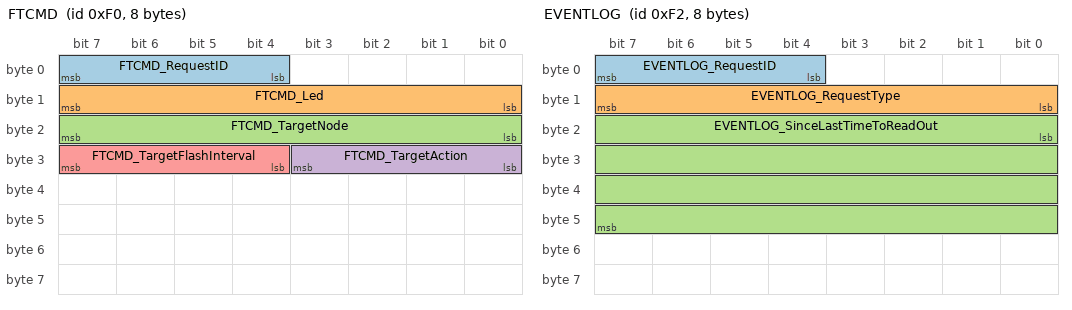
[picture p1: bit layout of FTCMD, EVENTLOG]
BO_ 240 FTCMD: 8 BATSYS
 SG_ FTCMD_RequestID : 4|4@1+ (1,0) [0|15] ""  BMC,XRCC
 SG_ FTCMD_Led : 8|8@1+ (1,0) [0|255] ""  BMC,XRCC
 SG_ FTCMD_TargetNode : 16|8@1+ (1,0) [0|0] ""  BMC,XRCC
 SG_ FTCMD_TargetAction : 24|4@1+ (1,0) [0|0] ""  BMC,XRCC
 SG_ FTCMD_TargetFlashInterval : 28|4@1+ (1,0) [0|15] "100ms"  BMC,XRCC

BO_ 144 AUXREQ: 8 BATSYS
 SG_ AUXREQ_RequestType : 4|4@1+ (1,0) [0|0] ""  BMC,XRCC
 SG_ AUXREQ_Mux M : 0|4@1+ (1,0) [0|0] ""  BMC,XRCC
 SG_ AUXREQ_RequestID m0 : 8|4@1+ (1,0) [0|15] ""  BMC,XRCC
 SG_ AUXREQ_RequestNParameters m0 : 12|4@1+ (1,0) [0|0] ""  BMC,XRCC
 SG_ AUXREQ_RequestTargetNodeAddress m0 : 16|8@1+ (1,0) [0|0] ""  BMC,XRCC
 SG_ AUXREQ_RequestParameter0 m0 : 24|40@1+ (1,0) [0|0] ""  BMC,XRCC
 SG_ AUXREQ_RequestParameter1 m1 : 8|56@1+ (1,0) [0|0] ""  BMC,XRCC
 SG_ AUXREQ_RequestParameter2 m2 : 8|56@1+ (1,0) [0|0] ""  BMC,XRCC
 SG_ AUXREQ_RequestParameter3 m3 : 8|56@1+ (1,0) [0|0] ""  BMC,XRCC
 SG_ AUXREQ_RequestParameter4 m4 : 8|56@1+ (1,0) [0|0] ""  BMC,XRCC
 SG_ AUXREQ_RequestParameter5 m5 : 8|56@1+ (1,0) [0|0] ""  BMC,XRCC
 SG_ AUXREQ_RequestParameter6 m6 : 8|56@1+ (1,0) [0|0] ""  BMC,XRCC
 SG_ AUXREQ_RequestParameter7 m7 : 8|56@1+ (1,0) [0|0] ""  BMC,XRCC
 SG_ AUXREQ_RequestParameter8 m8 : 8|56@1+ (1,0) [0|0] ""  BMC,XRCC
 SG_ AUXREQ_RequestParameter9 m9 : 8|56@1+ (1,0) [0|0] ""  BMC,XRCC
 SG_ AUXREQ_RequestParameter10 m10 : 8|56@1+ (1,0) [0|0] ""  BMC,XRCC
 SG_ AUXREQ_RequestParameter11 m11 : 8|56@1+ (1,0) [0|0] ""  BMC,XRCC
 SG_ AUXREQ_RequestParameter12 m12 : 8|56@1+ (1,0) [0|0] ""  BMC,XRCC
 SG_ AUXREQ_RequestParameter13 m13 : 8|56@1+ (1,0) [0|0] ""  BMC,XRCC
 SG_ AUXREQ_RequestParameter14 m14 : 8|56@1+ (1,0) [0|0] ""  BMC,XRCC
 SG_ AUXREQ_RequestParameter15 m15 : 8|56@1+ (1,0) [0|0] ""  BMC,XRCC

BO_ 1664 AUXRESP: 8 BMC
 SG_ AUXRESP_ResponseType : 4|4@1+ (1,0) [0|0] ""  BATSYS
 SG_ AUXRESP_Mux M : 0|4@1+ (1,0) [0|0] ""  BATSYS
 SG_ AUXRESP_ResponseID m0 : 8|4@1+ (1,0) [0|15] ""  BATSYS
 SG_ AUXRESP_ResponseNParameters m0 : 12|4@1+ (1,0) [0|0] ""  BATSYS
 SG_ AUXRESP_ResponseErrorType m0 : 16|8@1+ (1,0) [0|0] ""  BATSYS
 SG_ AUXRESP_ResponseParameter0 m0 : 24|40@1+ (1,0) [0|0] ""  BATSYS
 SG_ AUXRESP_ResponseParameter1 m1 : 8|56@1+ (1,0) [0|0] ""  BATSYS
 SG_ AUXRESP_ResponseParameter2 m2 : 8|56@1+ (1,0) [0|0] ""  BATSYS
 SG_ AUXRESP_ResponseParameter3 m3 : 8|56@1+ (1,0) [0|0] ""  BATSYS
 SG_ AUXRESP_ResponseParameter4 m4 : 8|56@1+ (1,0) [0|0] ""  BATSYS
 SG_ AUXRESP_ResponseParameter5 m5 : 8|56@1+ (1,0) [0|0] ""  BATSYS
 SG_ AUXRESP_ResponseParameter6 m6 : 8|56@1+ (1,0) [0|0] ""  BATSYS
 SG_ AUXRESP_ResponseParameter7 m7 : 8|56@1+ (1,0) [0|0] ""  BATSYS
 SG_ AUXRESP_ResponseParameter8 m8 : 8|56@1+ (1,0) [0|0] ""  BATSYS
 SG_ AUXRESP_ResponseParameter9 m9 : 8|56@1+ (1,0) [0|0] ""  BATSYS
 SG_ AUXRESP_ResponseParameter10 m10 : 8|56@1+ (1,0) [0|0] ""  BATSYS
 SG_ AUXRESP_ResponseParameter11 m11 : 8|56@1+ (1,0) [0|0] ""  BATSYS
 SG_ AUXRESP_ResponseParameter12 m12 : 8|56@1+ (1,0) [0|0] ""  BATSYS
 SG_ AUXRESP_ResponseParameter13 m13 : 8|56@1+ (1,0) [0|0] ""  BATSYS
 SG_ AUXRESP_ResponseParameter14 m14 : 8|56@1+ (1,0) [0|0] ""  BATSYS
 SG_ AUXRESP_ResponseParameter15 m15 : 8|56@1+ (1,0) [0|0] ""  BATSYS

BO_ 241 CFGCMD: 8 BATSYS
 SG_ CFGCMD_RequestID : 4|4@1+ (1,0) [0|15] ""  BMC
 SG_ CFGCMD_ReauestType m1 : 8|8@1+ (1,0) [0|0] ""  BMC
 SG_ CFGCMD_TargetNode m1 : 16|8@1+ (1,0) [0|0] ""  BMC
 SG_ CFGCMD_Parameters m1 : 48|16@1+ (1,0) [0|0] ""  BMC
 SG_ CFGCMD_SN_1ST2BYTES m1 : 24|16@1+ (1,0) [0|0] ""  BMC

BO_ 242 EVENTLOG: 8 BATSYS
 SG_ EVENTLOG_RequestID : 4|4@1+ (1,0) [0|15] ""  BMC
 SG_ EVENTLOG_RequestType : 8|8@1+ (1,0) [0|0] ""  BMC
 SG_ EVENTLOG_SinceLastTimeToReadOut : 16|32@1+ (1,0) [0|0] "sec"  BMC

BO_ 1536 ELRESP: 8 BMC
 SG_ ELRESP_ResponseID : 4|4@1+ (1,0) [0|15] ""  BATSYS
 SG_ ELRESP_Mux M : 0|4@1+ (1,0) [0|0] ""  BATSYS
 SG_ ELRESP_LogContinue : 8|1@1+ (1,0) [0|0] ""  BATSYS
 SG_ ELRESP_LogEmpty : 9|1@1+ (1,0) [0|0] ""  BATSYS
 SG_ ELRESP_LogContinue_ID m1 : 12|20@1+ (1,0) [0|100] ""  BATSYS
 SG_ ELRESP_Log0 m1 : 32|32@1+ (1,0) [0|0] ""  BATSYS
 SG_ ELRESP_Log1 m2 : 16|48@1+ (1,0) [0|0] ""  BATSYS
 SG_ ELRESP_Log2 m3 : 16|48@1+ (1,0) [0|0] ""  BATSYS
 SG_ ELRESP_Log3 m4 : 16|48@1+ (1,0) [0|0] ""  BATSYS
 SG_ ELRESP_Log4 m5 : 16|48@1+ (1,0) [0|0] ""  BATSYS
 SG_ ELRESP_Log5 m6 : 16|32@1+ (1,0) [0|0] ""  BATSYS

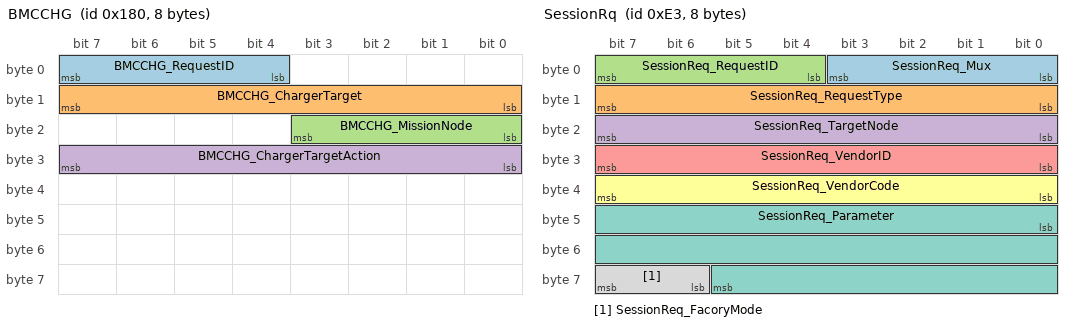
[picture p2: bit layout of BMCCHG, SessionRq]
BO_ 384 BMCCHG: 8 BATSYS
 SG_ BMCCHG_RequestID : 4|4@1+ (1,0) [0|15] ""  BMC
 SG_ BMCCHG_ChargerTarget : 8|8@1+ (1,0) [0|0] ""  BMC
 SG_ BMCCHG_MissionNode : 16|4@1+ (1,0) [0|0] ""  BMC
 SG_ BMCCHG_ChargerTargetAction : 24|8@1+ (1,0) [0|0] ""  BMC

BO_ 224 CFGCMD2: 8 BATSYS
 SG_ CFGCMD2_Mux M : 0|4@1+ (1,0) [0|15] ""  BATSYS
 SG_ CFGCMD2_RequestID : 4|4@1+ (1,0) [0|0] ""  BATSYS
 SG_ CFGCMD2_RequestType m1 : 8|8@1+ (1,0) [0|0] ""  BATSYS
 SG_ CFGCMD2RequestNparameter m1 : 16|4@1+ (1,0) [0|15] ""  BATSYS
 SG_ CFGCMD2_Parameter1 m1 : 20|44@1+ (1,0) [0|0] ""  BATSYS
 SG_ CFGCMD2_Parameter2 m2 : 8|56@1+ (1,0) [0|0] ""  BATSYS
 SG_ CFGCMD2_Parameter3 m3 : 8|56@1+ (1,0) [0|0] ""  BATSYS
 SG_ CFGCMD2_Parameter4 m4 : 8|56@1+ (1,0) [0|0] ""  BATSYS
 SG_ CFGCMD2_Parameter5 m5 : 8|56@1+ (1,0) [0|0] ""  BATSYS
 SG_ CFGCMD2_Parameter6 m6 : 8|56@1+ (1,0) [0|0] ""  BATSYS
 SG_ CFGCMD2_Parameter7 m7 : 8|56@1+ (1,0) [0|0] ""  BATSYS
 SG_ CFGCMD2_Parameter8 m8 : 8|56@1+ (1,0) [0|0] ""  BATSYS
 SG_ CFGCMD2_Parameter9 m9 : 8|56@1+ (1,0) [0|0] ""  BATSYS
 SG_ CFGCMD2_Parameter10 m10 : 8|56@1+ (1,0) [0|0] ""  BATSYS
 SG_ CFGCMD2_Parameter11 m11 : 8|56@1+ (1,0) [0|0] ""  BATSYS
 SG_ CFGCMD2_Parameter12 m12 : 8|56@1+ (1,0) [0|0] ""  BATSYS
 SG_ CFGCMD2_Parameter13 m13 : 8|56@1+ (1,0) [0|0] ""  BATSYS
 SG_ CFGCMD2_Parameter14 m14 : 8|56@1+ (1,0) [0|0] ""  BATSYS
 SG_ CFGCMD2_Parameter15 m15 : 8|56@1+ (1,0) [0|0] ""  BATSYS

BO_ 225 DIAGREQ: 8 BATSYS
 SG_ DIAGREQ_RequestID : 4|4@1+ (1,0) [0|15] ""  BMC
 SG_ DIAGREQ_RequestType : 8|8@1+ (1,0) [0|255] "" Vector__XXX

BO_ 1280 DIAGSTS: 8 BMC
 SG_ DIAGSTS_MUX M : 0|4@1+ (1,0) [0|15] ""  BATSYS
 SG_ DIAGSTS_ResponseID : 4|4@1+ (1,0) [0|0] ""  BATSYS
 SG_ DIAGSTS_ServiceDisconnect : 8|1@1+ (1,0) [0|1] "Flag"  BATSYS
 SG_ DIAGSTS_LPSON : 9|1@1+ (1,0) [0|1] "Flag"  BATSYS
 SG_ DIAGSTS_BM_PWR_RDY : 10|1@1+ (1,0) [0|1] "Flag"  BATSYS
 SG_ DIAGSTS_Addr0 : 11|1@1+ (1,0) [0|1] "Flag"  BATSYS
 SG_ DIAGSTS_Addr1 : 12|1@1+ (1,0) [0|1] "Flag"  BATSYS
 SG_ DIAGSTS_Addr2 : 13|1@1+ (1,0) [0|1] "Flag"  BATSYS
 SG_ DIAGSTS_BM_LPS_ON_CMD : 14|1@1+ (1,0) [0|1] "Flag"  BATSYS
 SG_ DIAGSTS_ChargeDisconnect : 15|1@1+ (1,0) [0|1] "Flag"  BATSYS
 SG_ DIAGSTS_DischargeDisconnect : 16|1@1+ (1,0) [0|1] "Flag"  BATSYS
 SG_ DIAGSTS_TrickleDisconnect : 17|1@1+ (1,0) [0|1] "Flag"  BATSYS
 SG_ DIAGSTS_Led1 : 18|1@1+ (1,0) [0|1] "Flag"  BATSYS
 SG_ DIAGSTS_Led2 : 19|1@1+ (1,0) [0|1] "Flag"  BATSYS
 SG_ DIAGSTS_ThermalSensorDisconnecte : 20|1@1+ (1,0) [0|1] "Flag"  BATSYS
 SG_ DIAGSTS_Thermisteropf : 21|1@1+ (1,0) [0|1] "Flag"  BATSYS
 SG_ DIAGSTS_FaultIndicateThspf : 22|1@1+ (1,0) [0|1] "Flag"  BATSYS
 SG_ DIAGSTS_FaultIndicateCfetpf : 23|1@1+ (1,0) [0|1] "Flag"  BATSYS
 SG_ DIAGSTS_FaultIndicateDfetpf : 24|1@1+ (1,0) [0|1] "Flag"  BATSYS
 SG_ DIAGSTS_FanFault : 25|1@1+ (1,0) [0|1] "Flag"  BATSYS
 SG_ DIAGSTS_HardwareFault : 26|1@1+ (1,0) [0|1] "Flag"  BATSYS
 SG_ DIAGSTS_VBus_Sense_Fault : 27|1@1+ (1,0) [0|1] "Flag"  BATSYS
 SG_ DIAGSTS_VBAT_Sense_Fault : 28|1@1+ (1,0) [0|1] "Flag"  BATSYS
 SG_ DIAGSTS_AFE_Fault : 29|1@1+ (1,0) [0|1] "Flag"  BATSYS
 SG_ DIAGSTS_FaultIndicateOtpf : 30|1@1+ (1,0) [0|1] "Flag"  BATSYS
 SG_ DIAGSTS_FaultIndicateFusepf : 31|1@1+ (1,0) [0|1] "Flag"  BATSYS
 SG_ DIAGSTS_TemProtectionMot : 32|1@1+ (1,0) [0|1] "Flag"  BATSYS
 SG_ DIAGSTS_DIAGSTS_SOH_Low : 33|1@1+ (1,0) [0|1] "Flag"  BATSYS
 SG_ DIAGSTS_VolProtectionOimbv : 34|1@1+ (1,0) [0|1] "Flag"  BATSYS
 SG_ DIAGSTS_FaultIndicateCimpf : 35|1@1+ (1,0) [0|1] "Flag"  BATSYS
 SG_ DIAGSTS_VolProtectionCov : 36|1@1+ (1,0) [0|1] "Flag"  BATSYS
 SG_ DIAGSTS_VolProtectionCuv : 37|1@1+ (1,0) [0|1] "Flag"  BATSYS
 SG_ DIAGSTS_VolProtectionPov : 38|1@1+ (1,0) [0|1] "Flag"  BATSYS
 SG_ DIAGSTS_VolProtectionPuv : 39|1@1+ (1,0) [0|1] "Flag"  BATSYS
 SG_ DIAGSTS_FaultIndicateUvpf : 40|1@1+ (1,0) [0|1] "Flag"  BATSYS
 SG_ DIAGSTS_FaultIndicateOvpf : 41|1@1+ (1,0) [0|1] "Flag"  BATSYS
 SG_ DIAGSTS_HW_BatteryUV : 42|1@1+ (1,0) [0|1] "Flag"  BATSYS
 SG_ DIAGSTS_HW_BatteryOV : 43|1@1+ (1,0) [0|1] "Flag"  BATSYS
 SG_ DIAGSTS_TemProtectionCot : 44|1@1+ (1,0) [0|1] "Flag"  BATSYS
 SG_ DIAGSTS_TemProtectionCut : 45|1@1+ (1,0) [0|1] "Flag"  BATSYS
 SG_ DIAGSTS_TemProtectionDot : 46|1@1+ (1,0) [0|1] "Flag"  BATSYS
 SG_ DIAGSTS_TemPotectionDut : 47|1@1+ (1,0) [0|1] "Flag"  BATSYS
 SG_ DIAGSTS_CurProtectionOci : 48|1@1+ (1,0) [0|1] "Flag"  BATSYS
 SG_ DIAGSTS_CurProtectionOdi_1 : 49|1@1+ (1,0) [0|1] "Flag"  BATSYS
 SG_ DIAGSTS_CurProtectionOdi_2 : 50|1@1+ (1,0) [0|1] "Flag"  BATSYS
 SG_ DIAGSTS_CurProtectionOdi_3 : 51|1@1+ (1,0) [0|1] "Flag"  BATSYS
 SG_ DIAGSTS_CurProtectionOdi_4 : 52|1@1+ (1,0) [0|1] "Flag"  BATSYS
 SG_ DIAGSTS_CurProtectionH_Odi : 53|1@1+ (1,0) [0|1] "Flag"  BATSYS
 SG_ DIAGSTS_CurProtectionH_Sci : 54|1@1+ (1,0) [0|1] "Flag"  BATSYS
 SG_ DIAGSTS_DFET_EN : 55|1@1+ (1,0) [0|1] "Flag"  BATSYS
 SG_ DIAGSTS_C1FET_EN : 56|1@1+ (1,0) [0|1] "Flag"  BATSYS
 SG_ DIAGSTS_C2FET_EN : 57|1@1+ (1,0) [0|1] "Flag"  BATSYS
 SG_ DIAGSTS_C1FET : 58|1@1+ (1,0) [0|1] "Flag"  BATSYS
 SG_ DIAGSTS_C2FET : 59|1@1+ (1,0) [0|1] "Flag"  BATSYS
 SG_ DIAGSTS_DFET : 60|1@1+ (1,0) [0|1] "Flag"  BATSYS
 SG_ DIAGSTS_TFET : 61|1@1+ (1,0) [0|1] "Flag"  BATSYS
 SG_ DIAGSTS_SoftStart : 62|1@1+ (1,0) [0|1] "Flag"  BATSYS
 SG_ DIAGSTS_TrickleCharge_ON : 63|1@1+ (1,0) [0|1] "Flag"  BATSYS

BO_ 1288 DIAGAFE: 8 BMC
 SG_ DIAGAFE_MUX M : 0|4@1+ (1,0) [0|15] ""  BATSYS
 SG_ DIAGAFE_ResponseID : 4|4@1+ (1,0) [0|15] ""  BATSYS
 SG_ DIAGAFE1_AFE1_Stackvoltage m1 : 8|8@1+ (1,0) [0|70] "Volts"  BATSYS
 SG_ DIAGAFE_AFE1_CSM_Temperature0 m1 : 16|8@1+ (1,-40) [-40|210] "degC"  BATSYS
 SG_ DIAGAFE_AFE1_CSM_Temperature1 m1 : 24|8@1+ (1,-40) [-40|210] "degC"  BATSYS
 SG_ DIAGAFE_AFE1_Cell_Temperature0 m1 : 32|8@1+ (1,-40) [-40|210] "degC"  BATSYS
 SG_ DIAGAFE_AFE1_Cell_Temperature1 m1 : 40|8@1+ (1,-40) [-40|210] "degC"  BATSYS
 SG_ DIAGAFE_AFE1_Cell_Temperature2 m1 : 48|8@1+ (1,-40) [-40|210] "degC"  BATSYS
 SG_ DIAGAFE_AFE1_Cell_Temperature3 m1 : 56|8@1+ (1,-40) [-40|210] "degC"  BATSYS
 SG_ DIAGAFE_AFE2_Stackvoltage m2 : 8|8@1+ (1,0) [0|70] "Volts"  BATSYS
 SG_ DIAGAFE_AFE2_CSM_Temperature0 m2 : 16|8@1+ (1,-40) [-40|210] "degC"  BATSYS
 SG_ DIAGAFE_AFE2_CSM_Temperature1 m2 : 24|8@1+ (1,-40) [-40|210] "degC"  BATSYS
 SG_ DIAGAFE_AFE2_Cell_Temperature0 m2 : 32|8@1+ (1,-40) [-40|210] "degC"  BATSYS
 SG_ DIAGAFE_AFE2_Cell_Temperature1 m2 : 40|8@1+ (1,-40) [-40|210] "degC"  BATSYS
 SG_ DIAGAFE_AFE2_Cell_Temperature2 m2 : 48|8@1+ (1,-40) [-40|210] "degC"  BATSYS
 SG_ DIAGAFE_AFE2_Cell_Temperature3 m2 : 56|8@1+ (1,-40) [-40|210] "degC"  BATSYS
 SG_ DIAGAFE_AFE3_Stackvoltage m3 : 8|8@1+ (1,0) [0|70] "Volts"  BATSYS
 SG_ DIAGAFE_AFE3_CSM_Temperature0 m3 : 16|8@1+ (1,-40) [-40|210] "degC"  BATSYS
 SG_ DIAGAFE_AFE3_CSM_Temperature1 m3 : 24|8@1+ (1,-40) [-40|210] "degc"  BATSYS
 SG_ DIAGAFE_AFE3_Cell_Temperature0 m3 : 32|8@1+ (1,-40) [-40|210] "degC"  BATSYS
 SG_ DIAGAFE_AFE3_Cell_Temperature1 m3 : 40|8@1+ (1,-40) [-40|210] "degC"  BATSYS
 SG_ DIAGAFE_AFE3_Cell_Temperature2 m3 : 48|8@1+ (1,-40) [-40|210] "degC"  BATSYS
 SG_ DIAGAFE_AFE3_Cell_Temperature3 m3 : 56|8@1+ (1,-40) [-40|210] "degC"  BATSYS
 SG_ DIAGAFE_AFE4_Stackvoltage m4 : 8|8@1+ (1,0) [0|70] "Volts"  BATSYS
 SG_ DIAGAFE_AFE4_CSM_Temperature0 m4 : 16|8@1+ (1,-40) [-40|210] "degC"  BATSYS
 SG_ DIAGAFE_AFE4_CSM_Temperature1 m4 : 24|8@1+ (1,-40) [-40|210] "degC"  BATSYS
 SG_ DIAGAFE_AFE4_Cell_Temperature0 m4 : 32|8@1+ (1,-40) [-40|210] "degC"  BATSYS
 SG_ DIAGAFE_AFE4_Cell_Temperature1 m4 : 40|8@1+ (1,-40) [-40|210] "degC"  BATSYS
 SG_ DIAGAFE_AFE4_Cell_Temperature2 m4 : 48|8@1+ (1,-40) [-40|210] "degC"  BATSYS
 SG_ DIAGAFE_AFE4_Cell_Temperature3 m4 : 56|8@1+ (1,-40) [-40|210] "degC"  BATSYS
 SG_ DIAGAFE_AFE1_Fault m5 : 8|1@1+ (1,0) [0|1] "Flag"  BATSYS
 SG_ DIAGAFE_AFE2_Fault m5 : 9|1@1+ (1,0) [0|1] "Flag"  BATSYS
 SG_ DIAGAFE_AFE3_Fault m5 : 10|1@1+ (1,0) [0|1] "Flag"  BATSYS
 SG_ DIAGAFE_AFE4_Fault m5 : 11|1@1+ (1,0) [0|1] "Flag"  BATSYS
 SG_ DIAGAFE_AFE1_Communication m5 : 12|1@1+ (1,0) [0|1] "Flag"  BATSYS
 SG_ DIAGAFE_AFE2_Communication m5 : 13|1@1+ (1,0) [0|1] "Flag"  BATSYS
 SG_ DIAGAFE_AFE3_Communication m5 : 14|1@1+ (1,0) [0|1] "Flag"  BATSYS
 SG_ DIAGAFE_AFE4_Communication m5 : 15|1@1+ (1,0) [0|1] "Flag"  BATSYS

BO_ 1304 DIAGRESP: 8 BMC
 SG_ DIAGRESP_MUX M : 0|4@1+ (1,0) [0|15] ""  BATSYS
 SG_ DIAGRESP_ResponseID : 4|4@1+ (1,0) [0|0] ""  BATSYS
 SG_ DIAGRESP_DischargeEnergy m1 : 8|8@1+ (1,0) [0|255] "Ah"  BATSYS
 SG_ DIAGRESP_ChargeEnergy m1 : 16|8@1+ (1,0) [0|255] "Ah"  BATSYS
 SG_ DIAGRESP_RemainingCapacity m1 : 24|12@1+ (1,0) [0|4095] "Whr"  BATSYS
 SG_ DIAGRESP_Full_Chargecapacity m1 : 36|12@1+ (1,0) [0|4095] "Whr"  BATSYS
 SG_ DIAGRESP_CumulativeEnergy m1 : 48|12@1+ (1,0) [0|4095] "Whr"  BATSYS
 SG_ DIAGRESP_Batterystatus m1 : 60|4@1+ (1,0) [0|0] ""  BATSYS
 SG_ DIAGRESP_SOC m2 : 8|8@1+ (1,0) [0|100] "Percentage"  BATSYS
 SG_ DIAGRESP_SOH m2 : 16|8@1+ (1,0) [0|100] "Percentage"  BATSYS
 SG_ DIAGRESP_DOD m2 : 24|8@1+ (1,0) [0|100] "Percentage"  BATSYS
 SG_ DIAGRESP_CycleCount m2 : 32|8@1+ (1,0) [0|100] "Percentage"  BATSYS
 SG_ DIAGRESP_DCIR m2 : 40|16@1+ (1,0) [0|65535] "mohms"  BATSYS
 SG_ DIAGRESP_DCIRDeltaInPercentage m2 : 56|8@1+ (1,0) [0|100] "Percentage"  BATSYS
 SG_ DIAGRESP_CellMaxVtg m3 : 8|12@1+ (1,500) [500|4500] "mv"  BATSYS
 SG_ DIAGRESP_CellMinVtg m3 : 20|12@1+ (1,500) [500|4500] "mv"  BATSYS
 SG_ DIAGRESP_CellAvgVtg m3 : 32|12@1+ (1,500) [500|4500] "mv"  BATSYS
 SG_ DIAGRESP_NCellUV m3 : 44|8@1+ (1,0) [0|50] ""  BATSYS
 SG_ DIAGRESP_NCellOV m3 : 52|8@1+ (1,0) [0|50] ""  BATSYS
 SG_ DIAGRESP_BMSStatus m3 : 60|4@1+ (1,0) [0|15] ""  BATSYS
 SG_ DIAGRESP_CellMax_T m4 : 8|8@1+ (1,-40) [-40|210] "degC"  BATSYS
 SG_ DIAGRESP_CellMin_T m4 : 16|8@1+ (1,-40) [-40|210] "degC"  BATSYS
 SG_ DIAGRESP_CellAvg_T m4 : 24|8@1+ (1,-40) [-40|210] "degC"  BATSYS
 SG_ DIAGRESP_CSMMax_T m4 : 32|8@1+ (1,-40) [-40|210] "degC"  BATSYS
 SG_ DIAGRESP_CSMMin_T m4 : 40|8@1+ (1,-40) [-40|210] "degC"  BATSYS
 SG_ DIAGRESP_CSMAvg_T m4 : 48|8@1+ (1,-40) [-40|210] "degC"  BATSYS
 SG_ DIAGRESP_FanDutyCycle m4 : 56|8@1+ (1,0) [0|100] ""  BATSYS
 SG_ DIAGRESP_ModuleVtg m5 : 8|12@1+ (0.1,0) [0|300] "Volts"  BATSYS
 SG_ DIAGRESP_ModuleRedundentVtg m5 : 20|12@1+ (0.1,0) [0|300] "Volts"  BATSYS
 SG_ DIAGRESP_BusVtg m5 : 32|12@1+ (0.1,0) [0|300] "Volts"  BATSYS
 SG_ DIAGRESP_BusRedundentVtg m5 : 44|12@1+ (0.1,0) [0|300] "Volts"  BATSYS
 SG_ DIAGRESP_ChargerVtg m6 : 8|12@1+ (0.1,0) [0|300] "Volts"  BATSYS
 SG_ DIAGRESP_NDischargeEvents m6 : 20|12@1+ (1,0) [0|4095] ""  BATSYS
 SG_ DIAGRESP_NDeepDischargeEvents m6 : 32|12@1+ (1,0) [0|4095] ""  BATSYS
 SG_ DIAGRESP_NFullChargeEvents m6 : 44|12@1+ (1,0) [0|4095] ""  BATSYS
 SG_ DIAGRESP_FanProportionalTimeOnSe m7 : 8|32@1+ (1,0) [-4967296|0] ""  BATSYS
 SG_ DIAGRESP_Current m7 : 40|16@1+ (0.01,-325) [-325|325] "amps"  BATSYS

BO_ 1312 DIAGCSTS: 8 BMC
 SG_ DIAGCSTS_MUX M : 0|4@1+ (1,0) [0|0] ""  BATSYS
 SG_ DIAGCSTS_ResponseID : 4|4@1+ (1,0) [0|0] ""  BATSYS
 SG_ DIAGCSTS_Cell1 m0 : 8|8@1+ (1,0) [0|0] "flag"  BATSYS
 SG_ DIAGCSTS_Cell2 m0 : 16|8@1+ (1,0) [0|0] "flag"  BATSYS
 SG_ DIAGCSTS_Cell3 m0 : 24|8@1+ (1,0) [0|0] "flag"  BATSYS
 SG_ DIAGCSTS_Cell4 m0 : 32|8@1+ (1,0) [0|0] "flag"  BATSYS
 SG_ DIAGCSTS_Cell5 m0 : 40|8@1+ (1,0) [0|0] "flag"  BATSYS
 SG_ DIAGCSTS_Cell6 m0 : 48|8@1+ (1,0) [0|0] "flag"  BATSYS
 SG_ DIAGCSTS_Cell7 m0 : 56|8@1+ (1,0) [0|0] "flag"  BATSYS
 SG_ DIAGCSTS_Cell8 m1 : 8|8@1+ (1,0) [0|0] "flag"  BATSYS
 SG_ DIAGCSTS_Cell9 m1 : 16|8@1+ (1,0) [0|0] "flag"  BATSYS
 SG_ DIAGCSTS_Cell10 m1 : 24|8@1+ (1,0) [0|0] "flag"  BATSYS
 SG_ DIAGCSTS_Cell11 m1 : 32|8@1+ (1,0) [0|0] "flag"  BATSYS
 SG_ DIAGCSTS_Cell12 m1 : 40|8@1+ (1,0) [0|0] "flag"  BATSYS
 SG_ DIAGCSTS_Cell13 m1 : 48|8@1+ (1,0) [0|0] "flag"  BATSYS
 SG_ DIAGCSTS_Cell14 m1 : 56|8@1+ (1,0) [0|0] "flag"  BATSYS
 SG_ DIAGCSTS_Cell15 m2 : 8|8@1+ (1,0) [0|0] "flag"  BATSYS
 SG_ DIAGCSTS_Cell16 m2 : 16|8@1+ (1,0) [0|0] "flag"  BATSYS
 SG_ DIAGCSTS_Cell17 m2 : 24|8@1+ (1,0) [0|0] "flag"  BATSYS
 SG_ DIAGCSTS_Cell18 m2 : 32|8@1+ (1,0) [0|0] "flag"  BATSYS
 SG_ DIAGCSTS_Cell19 m2 : 40|8@1+ (1,0) [0|0] "flag"  BATSYS
 SG_ DIAGCSTS_Cell20 m2 : 48|8@1+ (1,0) [0|0] "flag"  BATSYS
 SG_ DIAGCSTS_Cell21 m2 : 56|8@1+ (1,0) [0|0] "flag"  BATSYS
 SG_ DIAGCSTS_Cell22 m3 : 8|8@1+ (1,0) [0|0] "flag"  BATSYS
 SG_ DIAGCSTS_Cell23 m3 : 16|8@1+ (1,0) [0|0] "flag"  BATSYS
 SG_ DIAGCSTS_Cell24 m3 : 24|8@1+ (1,0) [0|0] "flag"  BATSYS
 SG_ DIAGCSTS_Cell25 m3 : 32|8@1+ (1,0) [0|0] "flag"  BATSYS
 SG_ DIAGCSTS_Cell26 m3 : 40|8@1+ (1,0) [0|0] "flag"  BATSYS
 SG_ DIAGCSTS_Cell27 m3 : 48|8@1+ (1,0) [0|0] "flag"  BATSYS
 SG_ DIAGCSTS_Cell28 m3 : 56|8@1+ (1,0) [0|0] "flag"  BATSYS
 SG_ DIAGCSTS_Cell29 m4 : 8|8@1+ (1,0) [0|0] "flag"  BATSYS
 SG_ DIAGCSTS_Cell30 m4 : 16|8@1+ (1,0) [0|0] "flag"  BATSYS
 SG_ DIAGCSTS_Cell31 m4 : 24|8@1+ (1,0) [0|0] "flag"  BATSYS
 SG_ DIAGCSTS_Cell32 m4 : 32|8@1+ (1,0) [0|0] "flag"  BATSYS
 SG_ DIAGCSTS_Cell33 m4 : 40|8@1+ (1,0) [0|0] "flag"  BATSYS
 SG_ DIAGCSTS_Cell34 m4 : 48|8@1+ (1,0) [0|0] "flag"  BATSYS
 SG_ DIAGCSTS_Cell35 m4 : 56|8@1+ (1,0) [0|0] "flag"  BATSYS
 SG_ DIAGCSTS_Cell36 m5 : 8|8@1+ (1,0) [0|0] "flag"  BATSYS
 SG_ DIAGCSTS_Cell37 m5 : 16|8@1+ (1,0) [0|0] "flag"  BATSYS
 SG_ DIAGCSTS_Cell38 m5 : 24|8@1+ (1,0) [0|0] "flag"  BATSYS
 SG_ DIAGCSTS_Cell39 m5 : 32|8@1+ (1,0) [0|0] "flag"  BATSYS
 SG_ DIAGCSTS_Cell40 m5 : 40|8@1+ (1,0) [0|0] "flag"  BATSYS
 SG_ DIAGCSTS_Cell41 m5 : 48|8@1+ (1,0) [0|0] "flag"  BATSYS
 SG_ DIAGCSTS_Cell42 m5 : 56|8@1+ (1,0) [0|0] "flag"  BATSYS
 SG_ DIAGCSTS_Cell43 m6 : 8|8@1+ (1,0) [0|0] "flag"  BATSYS
 SG_ DIAGCSTS_Cell44 m6 : 16|8@1+ (1,0) [0|0] "flag"  BATSYS
 SG_ DIAGCSTS_Cell45 m6 : 24|8@1+ (1,0) [0|0] "flag"  BATSYS
 SG_ DIAGCSTS_Cell46 m6 : 32|8@1+ (1,0) [0|0] "flag"  BATSYS
 SG_ DIAGCSTS_Cell47 m6 : 40|8@1+ (1,0) [0|0] "flag"  BATSYS
 SG_ DIAGCSTS_Cell48 m6 : 48|8@1+ (1,0) [0|0] "flag"  BATSYS
 SG_ DIAGCSTS_Cell49 m6 : 56|8@1+ (1,0) [0|0] "flag"  BATSYS
 SG_ DIAGCSTS_Cell50 m7 : 8|8@1+ (1,0) [0|0] "flag"  BATSYS

BO_ 1320 DIAGVERINFO: 8 BMC
 SG_ DIAGVERINFO_Mux M : 0|4@1+ (1,0) [0|0] ""  BMC
 SG_ DIAGVERINFO_ResponseID : 4|4@1+ (1,0) [0|0] ""  BMC
 SG_ DIAGVERINFO_ProtocolVersion m1 : 8|8@1+ (1,0) [0|0] ""  BMC
 SG_ DIAGVERINFO_SoftwareVersionMajor m1 : 16|8@1+ (1,0) [0|255] ""  BMC
 SG_ DIAGVERINFO_SoftwareVersionMinor m1 : 24|8@1+ (1,0) [0|255] ""  BMC
 SG_ DIAGVERINFO_SoftwareVersionBuild m1 : 32|8@1+ (1,0) [0|255] ""  BMC
 SG_ DIAGVERINFO_InServiceDate m1 : 40|16@1+ (1,0) [0|65535] "Days"  BMC
 SG_ DIAGVERINFO_AttachedUPSSKU m1 : 56|8@1+ (1,0) [0|255] ""  BMC
 SG_ DIAGVERINFO_ManufactureYear m2 : 8|7@1+ (1,2000) [0|37] "Year"  BMC
 SG_ DIAGVERINFO_ManufactureDay m2 : 15|9@1+ (1,0) [0|366] "Days"  BMC
 SG_ DIAGVERINFO_ManufactureSerial m2 : 24|16@1+ (1,0) [0|255] ""  BMC
 SG_ DIAGVERINFO_ManufactureDate m2 : 40|16@1+ (1,0) [0|65535] "Days"  BMC
 SG_ DIAGVERINFO_SerialNumber1 m3 : 16|48@1+ (1,0) [0|0] "ASCII"  BMC
 SG_ DIAGVERINFO_SerialNumber2 m4 : 16|48@1+ (1,0) [0|0] "ASCII"  BMC
 SG_ DIAGVERINFO_SerialNumber3 m5 : 16|32@1+ (1,0) [0|0] "ASCII"  BMC
 SG_ DIAGVERINFO_PartNumber1 m6 : 16|48@1+ (1,0) [0|0] "ASCII"  BMC
 SG_ DIAGVERINFO_PartNumber2 m7 : 16|48@1+ (1,0) [0|0] "ASCII"  BMC
 SG_ DIAGVERINFO_PartNumber3 m8 : 16|32@1+ (1,0) [0|0] "ASCII"  BMC
 SG_ DIAGVERINFO_SeriesConfiguration m9 : 8|8@1+ (1,0) [0|0] "# Cells series"  BMC
 SG_ DIAGVERINFO_ParallelConfiguratio m9 : 16|8@1+ (1,0) [0|0] "# Cells parallel"  BMC
 SG_ DIAGVERINFO_DesignCapacity m9 : 24|12@1+ (1,0) [0|4094] "Whr"  BMC
 SG_ DIAGVERINFO_DesignVoltage m9 : 36|9@1+ (1,0) [0|510] "Volts"  BMC
 SG_ DIAGVERINFO_DesignPower m9 : 45|16@1+ (1,0) [0|65534] "Watts"  BMC
 SG_ DIAGVERINFO_SoftwareAvailableMaj m10 : 8|8@1+ (1,0) [0|255] ""  BMC
 SG_ DIAGVERINFO_SoftwareAvailableMin m10 : 16|8@1+ (1,0) [0|255] ""  BMC
 SG_ DIAGVERINFO_SoftwareAvailableBui m10 : 24|8@1+ (1,0) [0|255] ""  BMC
 SG_ DIAGVERINFO_BmFileTransferInIdle m10 : 32|1@1+ (1,0) [0|0] "Flag"  BMC
 SG_ DIAGVERINFO_BmFileTransferInProg m10 : 33|1@1+ (1,0) [0|0] "Flag"  BMC
 SG_ DIAGVERINFO_BmFileTransferInveri m10 : 34|1@1+ (1,0) [0|0] "Flag"  BMC
 SG_ DIAGVERINFO_BmFileTraReadyInstal m10 : 35|1@1+ (1,0) [0|0] "Flag"  BMC
 SG_ DIAGVERINFO_VendorCode m10 : 36|8@1+ (1,0) [0|0] ""  BMC
 SG_ DIAGVERINFO_BLVersionMajor m11 : 8|8@1+ (1,0) [0|255] "" Vector__XXX
 SG_ DIAGVERINFO_BLVersionMinor m11 : 16|8@1+ (1,0) [0|255] "" Vector__XXX
 SG_ DIAGVERINFO_BLVersionBuild m11 : 24|8@1+ (1,0) [0|255] "" Vector__XXX

BO_ 227 SessionRq: 8 BATSYS
 SG_ SessionReq_Mux M : 0|4@1+ (1,0) [0|0] ""  BATSYS
 SG_ SessionReq_RequestType : 8|8@1+ (1,0) [0|0] ""  BATSYS
 SG_ SessionReq_RequestID : 4|4@1+ (1,0) [0|0] ""  BATSYS
 SG_ SessionReq_TargetNode : 16|8@1+ (1,0) [0|15] ""  BATSYS
 SG_ SessionReq_VendorID : 24|8@1+ (1,0) [0|0] ""  BATSYS
 SG_ SessionReq_VendorCode : 32|8@1+ (1,0) [0|0] ""  BATSYS
 SG_ SessionReq_Parameter : 40|22@1+ (2,1) [0|0] ""  BATSYS
 SG_ SessionReq_FacoryMode : 62|2@1+ (2,0) [0|0] ""  BATSYS

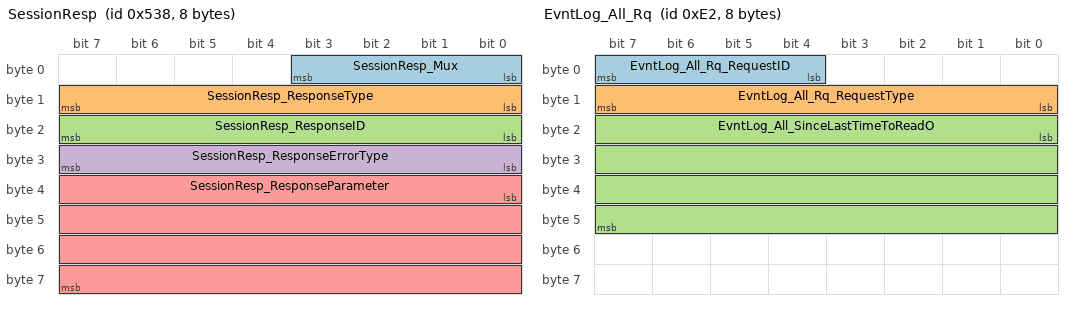
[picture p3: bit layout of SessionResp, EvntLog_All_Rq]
BO_ 1336 SessionResp: 8 BMC
 SG_ SessionResp_Mux M : 0|4@1+ (1,0) [0|0] ""  BMC
 SG_ SessionResp_ResponseType : 8|8@1+ (1,0) [0|0] ""  BMC
 SG_ SessionResp_ResponseID : 16|8@1+ (1,0) [0|0] ""  BMC
 SG_ SessionResp_ResponseErrorType : 24|8@1+ (1,0) [0|15] ""  BMC
 SG_ SessionResp_ResponseParameter : 32|32@1+ (1,0) [0|0] ""  BMC

BO_ 1296 DIAGAFECELL: 8 BMC
 SG_ DIAGAFECELL_MUX M : 0|4@1+ (1,0) [0|15] ""  BMC
 SG_ DIAGAFE_ResponseID : 4|4@1+ (1,0) [0|15] ""  BMC
 SG_ DIAGAFE_AFE1_Cell0 m1 : 8|12@1+ (1,500) [500|4500] "mv"  BMC
 SG_ DIAGAFE_AFE1_Cell1 m1 : 20|12@1+ (1,500) [500|4500] "mv"  BMC
 SG_ DIAGAFE_AFE1_Cell2 m1 : 32|12@1+ (1,500) [500|4500] "mv"  BMC
 SG_ DIAGAFE_AFE1_Cell3 m1 : 44|12@1+ (1,500) [500|4500] "mv"  BMC
 SG_ DIAGAFE_AFE1_Cell4 m2 : 8|12@1+ (1,500) [500|4500] "mv"  BMC
 SG_ DIAGAFE_AFE1_Cell5 m2 : 20|12@1+ (1,500) [500|4500] "mv"  BMC
 SG_ DIAGAFE_AFE1_Cell6 m2 : 32|12@1+ (1,500) [500|4500] "mv"  BMC
 SG_ DIAGAFE_AFE1_Cell7 m2 : 44|12@1+ (1,500) [500|4500] "mv"  BMC
 SG_ DIAGAFE_AFE1_Cell8 m3 : 8|12@1+ (1,500) [500|4500] "mv"  BMC
 SG_ DIAGAFE_AFE1_Cell9 m3 : 20|12@1+ (1,500) [500|4500] "mv"  BMC
 SG_ DIAGAFE_AFE1_Cell10 m3 : 32|12@1+ (1,500) [500|4500] "mv"  BMC
 SG_ DIAGAFE_AFE1_Cell11 m3 : 44|12@1+ (1,500) [500|4500] "mv"  BMC
 SG_ DIAGAFE_AFE1_Cell12 m4 : 8|12@1+ (1,500) [500|4500] "mv"  BMC
 SG_ DIAGAFE_AFE1_Cell13 m4 : 20|12@1+ (1,500) [500|4500] "mv"  BMC
 SG_ DIAGAFE_AFE2_Cell0 m4 : 32|12@1+ (1,500) [500|4500] "mv"  BMC
 SG_ DIAGAFE_AFE2_Cell1 m4 : 44|12@1+ (1,500) [500|4500] "mv"  BMC
 SG_ DIAGAFE_AFE2_Cell2 m5 : 8|12@1+ (1,500) [500|4500] "mv"  BMC
 SG_ DIAGAFE_AFE2_Cell3 m5 : 20|12@1+ (1,500) [500|4500] "mv"  BMC
 SG_ DIAGAFE_AFE2_Cell4 m5 : 32|12@1+ (1,500) [500|4500] "mv"  BMC
 SG_ DIAGAFE_AFE2_Cell5 m5 : 44|12@1+ (1,500) [500|4500] "mv"  BMC
 SG_ DIAGAFE_AFE2_Cell6 m6 : 8|12@1+ (1,500) [500|4500] "mv"  BMC
 SG_ DIAGAFE_AFE2_Cell7 m6 : 20|12@1+ (1,500) [500|4500] "mv"  BMC
 SG_ DIAGAFE_AFE2_Cell8 m6 : 32|12@1+ (1,500) [500|4500] "mv"  BMC
 SG_ DIAGAFE_AFE2_Cell9 m6 : 44|12@1+ (1,500) [500|4500] "mv"  BMC
 SG_ DIAGAFE_AFE2_Cell10 m7 : 8|12@1+ (1,500) [500|4500] "mv"  BMC
 SG_ DIAGAFE_AFE2_Cell11 m7 : 20|12@1+ (1,500) [500|4500] "mv"  BMC
 SG_ DIAGAFE_AFE2_Cell12 m7 : 32|12@1+ (1,500) [500|4500] "mv"  BMC
 SG_ DIAGAFE_AFE2_Cell13 m7 : 44|12@1+ (1,500) [500|4500] "mv"  BMC
 SG_ DIAGAFE_AFE3_Cell0 m8 : 8|12@1+ (1,500) [500|4500] "mv"  BMC
 SG_ DIAGAFE_AFE3_Cell1 m8 : 20|12@1+ (1,500) [500|4500] "mv"  BMC
 SG_ DIAGAFE_AFE3_Cell2 m8 : 32|12@1+ (1,500) [500|4500] "mv"  BMC
 SG_ DIAGAFE_AFE3_Cell3 m8 : 44|12@1+ (1,500) [500|4500] "mv"  BMC
 SG_ DIAGAFE_AFE3_Cell4 m9 : 8|12@1+ (1,500) [500|4500] "mv"  BMC
 SG_ DIAGAFE_AFE3_Cell5 m9 : 20|12@1+ (1,500) [500|4500] "mv"  BMC
 SG_ DIAGAFE_AFE3_Cell6 m9 : 32|12@1+ (1,500) [500|4500] "mv"  BMC
 SG_ DIAGAFE_AFE3_Cell7 m9 : 44|12@1+ (1,500) [500|4500] "mv"  BMC
 SG_ DIAGAFE_AFE3_Cell8 m10 : 8|12@1+ (1,500) [500|4500] "mv"  BMC
 SG_ DIAGAFE_AFE3_Cell9 m10 : 20|12@1+ (1,500) [500|4500] "mv"  BMC
 SG_ DIAGAFE_AFE3_Cell10 m10 : 32|12@1+ (1,500) [500|4500] "mv"  BMC
 SG_ DIAGAFE_AFE3_Cell11 m10 : 44|12@1+ (1,500) [500|4500] "mv"  BMC
 SG_ DIAGAFE_AFE3_Cell12 m11 : 8|12@1+ (1,500) [500|4500] "mv"  BMC
 SG_ DIAGAFE_AFE3_Cell13 m11 : 20|12@1+ (1,500) [500|4500] "mv"  BMC
 SG_ DIAGAFE_AFE4_Cell0 m11 : 32|12@1+ (1,500) [500|4500] "mv"  BMC
 SG_ DIAGAFE_AFE4_Cell1 m11 : 44|12@1+ (1,500) [500|4500] "mv"  BMC
 SG_ DIAGAFE_AFE4_Cell2 m12 : 8|12@1+ (1,500) [500|4500] "mv"  BMC
 SG_ DIAGAFE_AFE4_Cell3 m12 : 20|12@1+ (1,500) [500|4500] "mv"  BMC
 SG_ DIAGAFE_AFE4_Cell4 m12 : 32|12@1+ (1,500) [500|4500] "mv"  BMC
 SG_ DIAGAFE_AFE4_Cell5 m12 : 44|12@1+ (1,500) [500|4500] "mv"  BMC
 SG_ DIAGAFE_AFE4_Cell6 m13 : 8|12@1+ (1,500) [500|4500] "mv"  BMC
 SG_ DIAGAFE_AFE4_Cell7 m13 : 20|12@1+ (1,500) [500|4500] "mv"  BMC
 SG_ DIAGAFE_AFE4_Cell8 m13 : 32|12@1+ (1,500) [500|4500] "mv"  BMC
 SG_ DIAGAFE_AFE4_Cell9 m13 : 44|12@1+ (1,500) [500|4500] "mv"  BMC
 SG_ DIAGAFE_AFE4_Cell10 m14 : 8|12@1+ (1,500) [500|4500] "mv"  BMC
 SG_ DIAGAFE_AFE4_Cell11 m14 : 20|12@1+ (1,500) [500|4500] "mv"  BMC
 SG_ DIAGAFE_AFE4_Cell12 m14 : 32|12@1+ (1,500) [500|4500] "mv"  BMC
 SG_ DIAGAFE_AFE4_Cell13 m14 : 44|12@1+ (1,500) [500|4500] "mv"  BMC

BO_ 226 EvntLog_All_Rq: 8 BATSYS
 SG_ EvntLog_All_Rq_RequestID : 4|4@1+ (1,0) [0|15] "" Vector__XXX
 SG_ EvntLog_All_Rq_RequestType : 8|8@1+ (1,0) [0|0] "" Vector__XXX
 SG_ EvntLog_All_SinceLastTimeToReadO : 16|32@1+ (1,0) [0|0] "sec" Vector__XXX

BO_ 1352 BattInf_StsInfo_Resp: 8 BMC
 SG_ Mux M : 0|4@1+ (1,0) [0|15] "flag" Vector__XXX
 SG_ Response_ID : 4|4@1+ (1,0) [0|15] "flag" Vector__XXX
 SG_ SVCDISC : 8|1@1+ (1,0) [0|1] "flag" Vector__XXX
 SG_ LPSONCMD : 9|1@1+ (1,0) [0|1] "flag" Vector__XXX
 SG_ ONBUTPRS : 10|1@1+ (1,0) [0|1] "flag" Vector__XXX
 SG_ PC1_MCU_Wakeup : 11|1@1+ (1,0) [0|1] "flag" Vector__XXX
 SG_ MECHILSW : 12|1@1+ (1,0) [0|1] "flag" Vector__XXX
 SG_ RTC_CONFIG_NOTDONE : 13|1@1+ (1,0) [0|1] "flag" Vector__XXX
 SG_ NVM_WRRETRYF : 14|1@1+ (1,0) [0|1] "flag" Vector__XXX
 SG_ Permanent_Failure_Present : 15|1@1+ (1,0) [0|1] "flag" Vector__XXX
 SG_ SOFTSTART_STS : 16|1@1+ (1,0) [0|1] "flag" Vector__XXX
 SG_ GPIO_PF1_OCCFLT : 17|1@1+ (1,0) [0|1] "flag" Vector__XXX
 SG_ GPIO_PF0_ODCFLT : 18|1@1+ (1,0) [0|1] "flag" Vector__XXX
 SG_ GPIO_PG0_CELLOTAFLT : 19|1@1+ (1,0) [0|1] "flag" Vector__XXX
 SG_ VBAT_UV_ALERTFLT : 20|1@1+ (1,0) [0|1] "flag" Vector__XXX
 SG_ VBAT_OV_ALERT : 21|1@1+ (1,0) [0|1] "flag" Vector__XXX
 SG_ HTO_LN_STS : 22|1@1+ (1,0) [0|1] "flag" Vector__XXX
 SG_ AFEFLTPIN_STS : 23|1@1+ (1,0) [0|1] "flag" Vector__XXX
 SG_ AFE_DSALE_STS : 24|1@1+ (1,0) [0|1] "flag" Vector__XXX
 SG_ CELL_OT_ALERT : 25|1@1+ (1,0) [0|1] "flag" Vector__XXX
 SG_ SFlash_Integrity_STS : 26|1@1+ (1,0) [0|1] "flag" Vector__XXX

BO_ 228 BattInf_Rq: 8 BATSYS
 SG_ BattInf_Rq_RequestID : 4|4@1+ (1,0) [0|15] "" Vector__XXX
 SG_ BattInf_Rq_RequestType : 8|8@1+ (1,0) [0|255] "" Vector__XXX

BO_ 1360 Batt_AddnlInfo_Resp: 8 BMC
 SG_ Batt_AddnlInfo_Resp_Mux M : 0|4@1+ (1,0) [0|0] "" Vector__XXX
 SG_ Batt_AddnlInfo_Resp_ResponseID : 4|4@1+ (1,0) [0|15] "" Vector__XXX
 SG_ Batt_AddnlInfo_Resp_CFETTemp m1 : 8|8@1+ (1,-40) [-40|210] "deg C" Vector__XXX
 SG_ Batt_AddnlInfo_Resp_DFETTemp m1 : 16|8@1+ (1,-40) [-40|210] "deg C" Vector__XXX
 SG_ Batt_AddnlInfo_Resp_TFETTemp m1 : 24|8@1+ (1,-40) [-40|210] "deg C" Vector__XXX
 SG_ Batt_AddnlInfo_Resp_SHTTemp m1 : 32|8@1+ (1,-40) [-40|210] "deg C" Vector__XXX
 SG_ Batt_AddnlInfo_Rsp_RedCellTempMC m1 : 40|8@1+ (1,-40) [-40|210] "deg C" Vector__XXX
 SG_ Batt_AddnlInfo_Resp_CELLTemp_1 m1 : 48|8@1+ (1,-40) [-40|210] "deg C" Vector__XXX
 SG_ Batt_AddnlInfo_Resp_CELLTemp_2 m1 : 56|8@1+ (1,-40) [-40|210] "deg C" Vector__XXX
 SG_ Batt_AddnlInfo_Resp_CELLTemp_3 m2 : 8|8@1+ (1,-40) [-40|210] "deg C" Vector__XXX
 SG_ Batt_AddnlInfo_Resp_CELLTemp_4 m2 : 16|8@1+ (1,-40) [-40|210] "deg C" Vector__XXX
 SG_ Batt_AddnlInfo_Resp_CELLTemp_5 m2 : 24|8@1+ (1,-40) [-40|210] "deg C" Vector__XXX
 SG_ Batt_AddnlInfo_Resp_CELLTemp_6 m2 : 32|8@1+ (1,-40) [-40|210] "deg C" Vector__XXX
 SG_ Batt_AddnlInfo_Resp_CELLTemp_7 m2 : 40|8@1+ (1,-40) [-40|210] "deg C" Vector__XXX
 SG_ Batt_AddnlInfo_Resp_CELLTemp_8 m2 : 48|8@1+ (1,-40) [-40|210] "deg C" Vector__XXX
 SG_ Batt_AddnlInfo_Resp_CELLTemp_9 m2 : 56|8@1+ (1,-40) [-40|210] "deg C" Vector__XXX
 SG_ Batt_AddnlInfo_Resp_CELLTemp_10 m3 : 8|8@1+ (1,-40) [-40|210] "deg C" Vector__XXX
 SG_ Batt_AddnlInfo_Resp_CELLTemp_11 m3 : 16|8@1+ (1,-40) [-40|210] "deg C" Vector__XXX
 SG_ Batt_AddnlInfo_Resp_CELLTemp_12 m3 : 24|8@1+ (1,-40) [-40|210] "deg C" Vector__XXX
 SG_ Batt_AddnlInfo_Resp_CELLTemp_13 m3 : 32|8@1+ (1,-40) [-40|210] "deg C" Vector__XXX
 SG_ Batt_AddnlInfo_Resp_CELLTemp_14 m3 : 40|8@1+ (1,-40) [-40|210] "deg C" Vector__XXX
 SG_ Batt_AddnlInfo_Resp_CELLTemp_15 m3 : 48|8@1+ (1,-40) [-40|210] "deg C" Vector__XXX
 SG_ Batt_AddnlInfo_Resp_CELLTemp_16 m3 : 56|8@1+ (1,-40) [-40|210] "deg C" Vector__XXX
 SG_ Batt_AddnlInfo_Resp_CELLTemp_17 m4 : 8|8@1+ (1,-40) [-40|210] "deg C" Vector__XXX
 SG_ Batt_AddnlInfo_Resp_CELLTemp_18 m4 : 16|8@1+ (1,-40) [-40|210] "deg C" Vector__XXX
 SG_ Batt_AddnlInfo_Resp_CSM_AFE1S1 m4 : 24|8@1+ (1,-40) [-40|210] "deg C" Vector__XXX
 SG_ Batt_AddnlInfo_Resp_CSM_AFE1S2 m4 : 32|8@1+ (1,-40) [-40|210] "deg C" Vector__XXX
 SG_ Batt_AddnlInfo_Resp_CSM_AFE2S1 m4 : 40|8@1+ (1,-40) [-40|210] "deg C" Vector__XXX
 SG_ Batt_AddnlInfo_Resp_CSM_AFE2S2 m4 : 48|8@1+ (1,-40) [-40|210] "deg C" Vector__XXX
 SG_ Batt_AddnlInfo_Resp_CSM_AFE3S1 m4 : 56|8@1+ (1,-40) [-40|210] "deg C" Vector__XXX
 SG_ Batt_AddnlInfo_Resp_CSM_AFE3S2 m5 : 8|8@1+ (1,-40) [-40|210] "deg C" Vector__XXX
 SG_ Batt_AddnlInfo_Resp_CSM_AFE4S1 m5 : 16|8@1+ (1,-40) [-40|210] "deg C" Vector__XXX
 SG_ Batt_AddnlInfo_Resp_CSM_AFE4S2 m5 : 24|8@1+ (1,-40) [-40|210] "deg C" Vector__XXX

BO_ 1344 BattInf_Fault_Resp: 8 BMC
 SG_ CELL_OV_L1 m1 : 8|1@1+ (1,0) [0|1] "flag" Vector__XXX
 SG_ BattInf_Fault_Resp_Mux M : 0|4@1+ (1,0) [0|0] "" Vector__XXX
 SG_ BattInf_Fault_Resp_ResponseID : 4|4@1+ (1,0) [0|0] "" Vector__XXX
 SG_ CELL_OV_L2 m1 : 9|1@1+ (1,0) [0|1] "flag" Vector__XXX
 SG_ CELL_OV_L3 m1 : 10|1@1+ (1,0) [0|1] "flag" Vector__XXX
 SG_ CELL_UV_L1 m1 : 11|1@1+ (1,0) [0|1] "flag" Vector__XXX
 SG_ CELL_UV_L2 m1 : 12|1@1+ (1,0) [0|1] "flag" Vector__XXX
 SG_ CELL_UV_L3 m1 : 13|1@1+ (1,0) [0|1] "flag" Vector__XXX
 SG_ PACK_OV_L1 m1 : 14|1@1+ (1,0) [0|1] "flag" Vector__XXX
 SG_ PACK_OV_L2 m1 : 15|1@1+ (1,0) [0|1] "flag" Vector__XXX
 SG_ PACK_OV_L4 m1 : 16|1@1+ (1,0) [0|1] "flag" Vector__XXX
 SG_ PACK_UV_L1 m1 : 17|1@1+ (1,0) [0|1] "flag" Vector__XXX
 SG_ PACK_UV_L2 m1 : 18|1@1+ (1,0) [0|1] "flag" Vector__XXX
 SG_ PACK_UV_L4 m1 : 19|1@1+ (1,0) [0|1] "flag" Vector__XXX
 SG_ ODCP_L1 m1 : 20|1@1+ (1,0) [0|1] "flag" Vector__XXX
 SG_ ODCP_L2 m1 : 21|1@1+ (1,0) [0|1] "flag" Vector__XXX
 SG_ ODCP_L4 m1 : 22|1@1+ (1,0) [0|1] "flag" Vector__XXX
 SG_ OCCP_L1 m1 : 23|1@1+ (1,0) [0|1] "flag" Vector__XXX
 SG_ OCCP_L2 m1 : 24|1@1+ (1,0) [0|1] "flag" Vector__XXX
 SG_ OCCP_L4 m1 : 25|1@1+ (1,0) [0|1] "flag" Vector__XXX
 SG_ CHG_OT_L1 m1 : 26|1@1+ (1,0) [0|1] "flag" Vector__XXX
 SG_ CHG_OT_L2 m1 : 27|1@1+ (1,0) [0|1] "flag" Vector__XXX
 SG_ CHG_OT_L3 m1 : 28|1@1+ (1,0) [0|1] "flag" Vector__XXX
 SG_ CHG_OT_L4 m1 : 29|1@1+ (1,0) [0|1] "flag" Vector__XXX
 SG_ CHG_OT_TC_L1 m1 : 30|1@1+ (1,0) [0|1] "flag" Vector__XXX
 SG_ DCHG_OT_L1 m1 : 31|1@1+ (1,0) [0|1] "flag" Vector__XXX
 SG_ DCHG_OT_L2 m1 : 32|1@1+ (1,0) [0|1] "flag" Vector__XXX
 SG_ DCHG_OT_L3 m1 : 33|1@1+ (1,0) [0|1] "flag" Vector__XXX
 SG_ DCHG_OT_L4 m1 : 34|1@1+ (1,0) [0|1] "flag" Vector__XXX
 SG_ CHG_UT_L1 m1 : 35|1@1+ (1,0) [0|1] "flag" Vector__XXX
 SG_ CHG_UT_L2 m1 : 36|1@1+ (1,0) [0|1] "flag" Vector__XXX
 SG_ DCHG_UT_L2 m1 : 40|1@1+ (1,0) [0|1] "flag" Vector__XXX
 SG_ CHG_UT_TC_L1 m1 : 38|1@1+ (1,0) [0|1] "flag" Vector__XXX
 SG_ CHG_UT_L3 m1 : 37|1@1+ (1,0) [0|1] "flag" Vector__XXX
 SG_ DCHG_UT_L3 m1 : 41|1@1+ (1,0) [0|1] "flag" Vector__XXX
 SG_ MOSFET_OT_L1 m1 : 42|1@1+ (1,0) [0|1] "flag" Vector__XXX
 SG_ MOSFET_OT_L2 m1 : 43|1@1+ (1,0) [0|1] "flag" Vector__XXX
 SG_ SHUNT_OT_L1 m1 : 44|1@1+ (1,0) [0|1] "flag" Vector__XXX
 SG_ SHUNT_OT_L2 m1 : 45|1@1+ (1,0) [0|1] "flag" Vector__XXX
 SG_ CSM_OT_L1 m1 : 46|1@1+ (1,0) [0|1] "flag" Vector__XXX
 SG_ CSM_OT_L2 m1 : 47|1@1+ (1,0) [0|1] "flag" Vector__XXX
 SG_ CSM_OT_L3 m1 : 48|1@1+ (1,0) [0|1] "flag" Vector__XXX
 SG_ TC_OT_L1 m1 : 49|1@1+ (1,0) [0|1] "flag" Vector__XXX
 SG_ DCHG_UT_L1 m1 : 39|1@1+ (1,0) [0|1] "flag" Vector__XXX
 SG_ CELL_UNBAL_L1 m1 : 50|1@1+ (1,0) [0|1] "flag" Vector__XXX
 SG_ CELL_UNBAL_L2 m1 : 51|1@1+ (1,0) [0|1] "flag" Vector__XXX
 SG_ SFTYAPP_FLT_L2 m1 : 52|1@1+ (1,0) [0|1] "flag" Vector__XXX
 SG_ SM_MCU_INIT_FAIL_L2 m1 : 53|1@1+ (1,0) [0|1] "flag" Vector__XXX
 SG_ SM_MCU_RUN_FAIL_L2 m1 : 54|1@1+ (1,0) [0|1] "flag" Vector__XXX
 SG_ SM_AFE_INIT_FAIL_L2 m1 : 55|1@1+ (1,0) [0|1] "flag" Vector__XXX
 SG_ SM_AFE_RUN_FAIL_L2 m1 : 56|1@1+ (1,0) [0|1] "flag" Vector__XXX
 SG_ NTC_OPEN_FLT_L1 m1 : 57|1@1+ (1,0) [0|1] "flag" Vector__XXX
 SG_ NTC_SHORT_FLT_L1 m1 : 58|1@1+ (1,0) [0|1] "flag" Vector__XXX
 SG_ FUSE_OPEN_FLT_L1 m1 : 59|1@1+ (1,0) [0|1] "flag" Vector__XXX
 SG_ CFET_SHORT_FLT_L1 m1 : 60|1@1+ (1,0) [0|1] "flag" Vector__XXX
 SG_ MCU_INIT_FAIL_L1 m1 : 63|1@1+ (1,0) [0|1] "flag" Vector__XXX
 SG_ DFET_SHORT_FLT_L1 m1 : 61|1@1+ (1,0) [0|1] "flag" Vector__XXX
 SG_ OCCP_TC_FLT_L1 m1 : 62|1@1+ (1,0) [0|1] "flag" Vector__XXX
 SG_ CAN_COMM_LOSS_L1 m2 : 8|1@1+ (1,0) [0|1] "flag" Vector__XXX
 SG_ FAN_FLT_L1 m2 : 9|1@1+ (1,0) [0|1] "flag" Vector__XXX
 SG_ CELL_DD_L1 m2 : 10|1@1+ (1,0) [0|1] "flag" Vector__XXX
 SG_ PACK_EOC_L1 m2 : 11|1@1+ (1,0) [0|1] "flag" Vector__XXX
 SG_ ENERGY_CHG_L1 m2 : 12|1@1+ (1,0) [0|1] "flag" Vector__XXX
 SG_ ENERGY_DCHG_L1 m2 : 13|1@1+ (1,0) [0|1] "flag" Vector__XXX

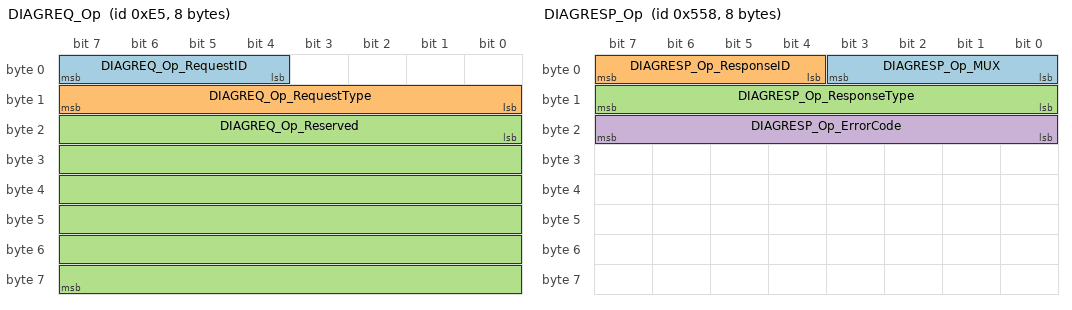
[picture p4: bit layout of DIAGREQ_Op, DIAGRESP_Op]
BO_ 229 DIAGREQ_Op: 8 BATSYS
 SG_ DIAGREQ_Op_RequestID : 4|4@1+ (1,0) [0|15] "" Vector__XXX
 SG_ DIAGREQ_Op_RequestType : 8|8@1+ (1,0) [0|255] "" Vector__XXX
 SG_ DIAGREQ_Op_Reserved : 16|48@1+ (1,0) [0|0] "" Vector__XXX

BO_ 1328 EvntLog_All_Resp: 8 BMC
 SG_ EvntLog_Timestamp_YEAR m1 : 32|6@1+ (1,2000) [0|64] "Year" Vector__XXX
 SG_ EvntLog_MUX M : 0|4@1+ (1,0) [0|0] "" Vector__XXX
 SG_ EvntLog_Response_ID : 4|4@1+ (1,0) [0|15] "" Vector__XXX
 SG_ EvntLog_LogContiunue : 8|1@1+ (1,0) [0|0] "" Vector__XXX
 SG_ EvntLog_LogContiunueID m1 : 12|20@1+ (1,0) [0|100] "" Vector__XXX
 SG_ EvntLog_LogEmpty : 9|1@1+ (1,0) [0|0] "" Vector__XXX
 SG_ EvntLog_Timestamp_MON m1 : 38|4@1+ (1,0) [1|12] "Month" Vector__XXX
 SG_ EvntLog_Timestamp_DAY m1 : 42|5@1+ (1,0) [1|366] "Day" Vector__XXX
 SG_ EvntLog_Timestamp_HOUR m1 : 47|5@1+ (1,0) [0|24] "Hour" Vector__XXX
 SG_ EvntLog_Timestamp_MIN m1 : 52|6@1+ (1,0) [0|60] "Minute" Vector__XXX
 SG_ EvntLog_Timestamp_SEC m1 : 58|6@1+ (1,0) [0|60] "Second" Vector__XXX
 SG_ EvntLog_ID m2 : 16|16@1+ (1,0) [0|65535] "" Vector__XXX
 SG_ EvntLog_Before_state m2 : 32|8@1+ (1,0) [0|255] "" Vector__XXX
 SG_ EvntLog_After_state m2 : 40|8@1+ (1,0) [0|255] "" Vector__XXX
 SG_ EvntLog_FET_state_Reserved m2 : 48|4@1+ (1,0) [0|255] "" Vector__XXX
 SG_ EvntLog_CMD m3 : 16|16@1+ (1,0) [0|65535] "" Vector__XXX
 SG_ EvntLog_Vbat m3 : 32|16@1+ (0.1,0) [0|65535] "Volts " Vector__XXX
 SG_ EvntLog_Vbus m3 : 48|16@1+ (0.1,0) [0|65535] "Volts" Vector__XXX
 SG_ EvntLog_Vmax_cell m4 : 16|16@1+ (1,0) [0|65535] "mv" Vector__XXX
 SG_ EvntLog_Vavg_cell m4 : 32|16@1+ (1,0) [0|65535] "mv" Vector__XXX
 SG_ EvntLog_Vmin_cell m4 : 48|16@1+ (1,0) [0|65535] "mv" Vector__XXX
 SG_ EvntLog_Ibatt_Before m5 : 16|16@1+ (0.01,-327.68) [-327.68|327.68] "10 mA" Vector__XXX
 SG_ EvntLog_Ibatt_After m5 : 32|16@1+ (0.01,-327.68) [-327.68|327.68] "10mA" Vector__XXX
 SG_ EvntLog_SOH m5 : 48|8@1+ (1,0) [0|255] "Percentage" Vector__XXX
 SG_ EvntLog_RSOC m5 : 56|8@1+ (1,0) [0|255] "Percentage" Vector__XXX
 SG_ EvntLog_Full_Charge_Capacity m6 : 16|16@1+ (1,0) [0|65535] "whr" Vector__XXX
 SG_ EvntLog_Avg_Temp m6 : 32|8@1+ (1,-40) [-40|210] "deg C" Vector__XXX
 SG_ EvntLog_FET_Temp m6 : 40|8@1+ (1,-40) [-40|210] "deg C" Vector__XXX
 SG_ EvntLog_Cell_Max_Temp m6 : 48|8@1+ (1,-40) [-40|210] "deg C" Vector__XXX
 SG_ EvntLog_Cell_Min_Temp m6 : 56|8@1+ (1,-40) [-40|210] "deg C" Vector__XXX
 SG_ EvntLog_Max_Cell_Temp_Index m7 : 16|5@1+ (1,0) [0|31] "" Vector__XXX
 SG_ EvntLog_Min_Cell_Temp_Index m7 : 21|5@1+ (1,0) [0|31] "" Vector__XXX
 SG_ EvntLog_Max_Cell_Volt_Index m7 : 26|6@1+ (1,0) [0|63] "" Vector__XXX
 SG_ EvntLog_Min_Cell_Volt_Index m7 : 32|6@1+ (1,0) [0|63] "" Vector__XXX
 SG_ EvntLog_BMS_Opmode m7 : 38|2@1+ (1,0) [0|3] "" Vector__XXX
 SG_ EvntLog_Energy m7 : 40|10@1+ (1,0) [0|1023] "whr" Vector__XXX
 SG_ EvntLog_BMS_Fan_Sts m7 : 51|1@1+ (1,0) [0|1] "" Vector__XXX
 SG_ EvntLog_BMS_PermFault_Sts m7 : 52|1@1+ (1,0) [0|1] "" Vector__XXX
 SG_ EvntLog_BMS_STS_Reserved m7 : 57|7@1+ (1,0) [0|0] "" Vector__XXX
 SG_ EvntLog_GPIO_OCCFaultSts m8 : 16|1@1+ (1,0) [0|1] "" Vector__XXX
 SG_ EvntLog_GPIO_ODCFaultSts m8 : 17|1@1+ (1,0) [0|1] "" Vector__XXX
 SG_ EvntLog_GPIO_UVFaultSts m8 : 18|1@1+ (1,0) [0|1] "" Vector__XXX
 SG_ EvntLog_GPIO_OVFaultSts m8 : 19|1@1+ (1,0) [0|1] "" Vector__XXX
 SG_ EvntLog_GPIO_OTFaultSts m8 : 20|1@1+ (1,0) [0|1] "" Vector__XXX
 SG_ EnvntLog_GPIO_TCOCP_Sts m8 : 21|1@1+ (1,0) [0|1] "" Vector__XXX
 SG_ EvntLog_GPIO_STS_Reserved m8 : 22|10@1+ (1,0) [0|255] "" Vector__XXX
 SG_ EvntLog_SequenceNumber m8 : 32|32@1+ (1,0) [0|0] "" Vector__XXX
 SG_ EvntLog_FaultCounter m9 : 16|16@1+ (1,0) [0|65535] "" Vector__XXX
 SG_ EvntLog_ResetReason_PWR_POR_RST m9 : 32|1@1+ (1,0) [0|1] "" Vector__XXX
 SG_ EvntLog_ResetReason_NRST m9 : 33|1@1+ (1,0) [0|1] "" Vector__XXX
 SG_ EvntLog_ResetReason_PWR_BOR_RST m9 : 34|1@1+ (1,0) [0|1] "" Vector__XXX
 SG_ EvntLog_Reset_Reason_Reserved m9 : 42|22@1+ (1,0) [0|0] "" Vector__XXX
 SG_ EvntLog_Reset_Counter m10 : 16|32@1+ (1,0) [0|0] "" Vector__XXX
 SG_ EvntLog_FW_Version_SW_Major m11 : 16|8@1+ (1,0) [0|255] "" Vector__XXX
 SG_ EvntLog_FW_Version_SW_Minor m11 : 24|8@1+ (1,0) [0|255] "" Vector__XXX
 SG_ EvntLog_FW_Version_SW_Build m11 : 32|8@1+ (1,0) [0|255] "" Vector__XXX
 SG_ EvntLog_STS_EI_MCU_LPSONCMD m10 : 48|1@1+ (1,0) [0|1] "" Vector__XXX
 SG_ EvntLog_STS_EI_MCU_MechInterlock m10 : 49|1@1+ (1,0) [0|1] "" Vector__XXX
 SG_ EvntLog_STS_EI_MCU_SRV_Dis m10 : 50|1@1+ (1,0) [0|1] "" Vector__XXX
 SG_ EvntLog_STS_EI_MCU_ON_BUTTONPRS m10 : 51|1@1+ (1,0) [0|1] "" Vector__XXX
 SG_ EvntLog_STS_EI_MCU_Reserved m10 : 52|12@1+ (1,0) [0|4095] "" Vector__XXX
 SG_ EvntLog_DFET_state m2 : 52|1@1+ (1,0) [0|1] "" Vector__XXX
 SG_ EvntLog_CFET_state m2 : 53|1@1+ (1,0) [0|1] "" Vector__XXX
 SG_ EvntLog_TFET_state m2 : 54|1@1+ (1,0) [0|1] "" Vector__XXX
 SG_ EvntLog_ResetReason_SFTRESET m9 : 35|1@1+ (1,0) [0|1] "" Vector__XXX
 SG_ EvntLog_ResetReason_CPURST m9 : 36|1@1+ (1,0) [0|1] "" Vector__XXX
 SG_ EvntLog_ResetReason_WWDG1_OutRST m9 : 37|1@1+ (1,0) [0|1] "" Vector__XXX
 SG_ EvntLog_ResetReason_IWDG1_OutRST m9 : 38|1@1+ (1,0) [0|1] "" Vector__XXX
 SG_ EvntLog_ResetReason_D1_Exit m9 : 39|1@1+ (1,0) [0|1] "" Vector__XXX
 SG_ EvntLog_ResetReason_D2_Exit m9 : 40|1@1+ (1,0) [0|1] "" Vector__XXX
 SG_ EvntLog_ResetReason_CSTOPMODE m9 : 41|1@1+ (1,0) [0|1] "" Vector__XXX
 SG_ EvntLog_FET_state_Reserved1 m2 : 55|9@1+ (1,0) [0|512] "" Vector__XXX
 SG_ Evntlog_CRC m11 : 40|16@1+ (1,0) [0|65535] "" Vector__XXX
 SG_ EvntLog_EraseResp : 10|2@1+ (1,0) [0|0] "" Vector__XXX
 SG_ EvntLog_BMS_Balancing_STS m7 : 50|1@1+ (1,0) [0|1] "" Vector__XXX
 SG_ EvntLog_BMS_AFE1Fault_Sts m7 : 53|1@1+ (1,0) [0|1] "" Vector__XXX
 SG_ EvntLog_BMS_AFE2Fault_Sts m7 : 54|1@1+ (1,0) [0|1] "" Vector__XXX
 SG_ EvntLog_BMS_AFE3Fault_Sts m7 : 55|1@1+ (1,0) [0|1] "" Vector__XXX
 SG_ EvntLog_BMS_AFE4Fault_Sts m7 : 56|1@1+ (1,0) [0|1] "" Vector__XXX

BO_ 1368 DIAGRESP_Op: 8 BMC
 SG_ DIAGRESP_Op_MUX M : 0|4@1+ (1,0) [0|0] "" Vector__XXX
 SG_ DIAGRESP_Op_ResponseID : 4|4@1+ (1,0) [0|15] "" Vector__XXX
 SG_ DIAGRESP_Op_ResponseType : 8|8@1+ (1,0) [0|0] "" Vector__XXX
 SG_ DIAGRESP_Op_ErrorCode : 16|8@1+ (1,0) [0|0] "" Vector__XXX

BO_ 640 VRLACFG: 8 BMC
 SG_ VRLACFG_Mux M : 0|4@1+ (1,0) [0|15] "" Vector__XXX
 SG_ VRLACFG_ResponseID : 4|4@1+ (1,0) [0|15] "" Vector__XXX
 SG_ VRLACFG_TimeSetting m7 : 32|32@1+ (1,0) [0|0] "" Vector__XXX
 SG_ VRLACFG_AvgPowerPerWHr m1 : 32|32@1+ (1,0) [0|0] "WHr" Vector__XXX
 SG_ VRLACFG_ChargerRefVoltage m0 : 48|16@1+ (1,0) [0|0] "volts" Vector__XXX
 SG_ VRLACFG_CutoffVoltage m0 : 16|16@1+ (1,0) [0|0] "volts" Vector__XXX
 SG_ VRLACFG_BatteryCurrent m3 : 32|32@1+ (1,0) [0|0] "amps" Vector__XXX
 SG_ VRLACFG_AvgCurrentPerWHr m2 : 32|32@1+ (1,0) [0|0] "WHr" Vector__XXX
 SG_ VRLACFG_LoadRealPower m2 : 16|12@1+ (1,0) [0|0] "watts" Vector__XXX
 SG_ VRLACFG_UPSState m1 : 8|16@1+ (1,0) [0|0] "flag" Vector__XXX
 SG_ VRLACFG_BattControl m4 : 16|16@1+ (1,0) [0|0] "" Vector__XXX
 SG_ VRLACFG_BattControl3 m4 : 48|16@1+ (1,0) [0|0] "" Vector__XXX
 SG_ VRLACFG_BattControl2 m4 : 32|16@1+ (1,0) [0|0] "" Vector__XXX
 SG_ VRLACFG_BattCalState m4 : 8|4@1+ (1,0) [0|0] "" Vector__XXX
 SG_ VRLACFG_VoltageDC m5 : 16|16@1+ (1,0) [0|0] "" Vector__XXX
 SG_ VRLACFG_LifeTimeSetting m3 : 16|16@1+ (1,0) [0|0] "enum" Vector__XXX
 SG_ VRLACFG_AlarmNotificationSetting m0 : 32|16@1+ (1,0) [0|0] "enum" Vector__XXX
 SG_ VRLACFG_Date m5 : 32|16@1+ (1,0) [0|0] "" Vector__XXX
 SG_ VRLACFG_DateSetting m5 : 48|16@1+ (1,0) [0|0] "" Vector__XXX
 SG_ VRLACFG_IndicatorSetting m6 : 16|16@1+ (1,0) [0|0] "" Vector__XXX
 SG_ VRLACFG_LifeTimeStatus m6 : 32|16@1+ (1,0) [0|0] "" Vector__XXX
 SG_ VRLACFG_ModulePresent m6 : 48|16@1+ (1,0) [0|0] "" Vector__XXX

BO_ 1152 VRLAM: 8 XRCC
 SG_ VRLAM_Mux M : 0|4@1+ (1,0) [0|0] "" Vector__XXX
 SG_ VRLAM_ResponseID : 4|4@1+ (1,0) [0|15] "" Vector__XXX
 SG_ VRLAM_TemperatureLifetimeCounter m1 : 32|32@1+ (1,0) [0|0] "" Vector__XXX
 SG_ VRLAM_BattVoltageDC m1 : 8|16@1+ (1,0) [0|0] "volts" Vector__XXX
 SG_ VRLAM_BattCurrentDC m2 : 8|16@1+ (1,0) [0|0] "amps" Vector__XXX
 SG_ VRLAM_StateOfHealth m2 : 32|16@1+ (1,0) [0|0] "" Vector__XXX
 SG_ VRLAM_BattLifeTimeStatus m2 : 48|16@1+ (1,0) [0|0] "" Vector__XXX
 SG_ VRLAM_BatterySystemError m3 : 8|16@1+ (1,0) [0|0] "" Vector__XXX
 SG_ VRLAM_BattDate m3 : 32|16@1+ (1,0) [0|0] "" Vector__XXX
 SG_ VRLAM_BattDateSetting m3 : 48|16@1+ (1,0) [0|0] "" Vector__XXX
 SG_ VRLAM_AuthenticationVersion m3 : 24|8@1+ (1,0) [0|0] "" Vector__XXX
 SG_ VRLAM_FuelWHr m4 : 32|32@1+ (1,0) [0|0] "WHr" Vector__XXX
 SG_ VRLAM_MaxFuelWHr m4 : 8|16@1+ (1,0) [0|0] "WHr" Vector__XXX
 SG_ VRLAM_MaxFuelPwr m5 : 32|16@1+ (1,0) [0|0] "" Vector__XXX
 SG_ VRLAM_UseableFuelWHr m5 : 48|16@1+ (1,0) [0|0] "" Vector__XXX
 SG_ VRLAM_CurrentDC m6 : 32|32@1+ (1,0) [0|0] "" Vector__XXX
 SG_ VRLAM_FrameType m5 : 8|16@1+ (1,0) [0|0] "" Vector__XXX
 SG_ VRLAM_FrameStatus m6 : 8|16@1+ (1,0) [0|0] "" Vector__XXX
 SG_ VRLAM_FrameCommand m7 : 8|16@1+ (1,0) [0|0] "" Vector__XXX
 SG_ VRLAM_PhysicalAddress m7 : 24|8@1+ (1,0) [0|0] "" Vector__XXX
 SG_ VRLAM_FrameNInstalled m7 : 32|8@1+ (1,0) [0|0] "" Vector__XXX
 SG_ VRLAM_FrameNBad m7 : 40|8@1+ (1,0) [0|0] "" Vector__XXX
 SG_ VRLAM_ConditionalDescriptorMask m8 : 8|32@1+ (1,0) [0|0] "" Vector__XXX
 SG_ VRLAM_FactoryCommand m8 : 40|8@1+ (1,0) [0|0] "" Vector__XXX
 SG_ VRLAM_testCommand m8 : 48|8@1+ (1,0) [0|0] "" Vector__XXX
 SG_ VRLAM_testNodeHistory m9 : 8|16@1+ (1,0) [0|0] "" Vector__XXX
 SG_ VRLAM_FrameResID m9 : 24|8@1+ (1,0) [0|0] "" Vector__XXX
 SG_ VRLAM_BattFrameDebugPtr m9 : 32|8@1+ (1,0) [0|0] "" Vector__XXX
 SG_ VRLAM_BattFrameDebugSTR m10 : 8|46@1+ (1,0) [0|0] "" Vector__XXX

CM_ BU_ BATSYS "Battery System Controller";
CM_ BU_ XRCC "Extended Runtime Frame Controllers";
CM_ BU_ BMC "Battery Module Controller";
CM_ SG_ 3221225472 FWSend_BlockStart_Command "It is fixed to 0x35.";
CM_ SG_ 3221225472 FWSend_BlockFragment_Command "It is fixed to 0x2.";
CM_ SG_ 3221225472 FWSend_BlockFragment_FragmentCou "It is a cyclic number from 0 ~ 15.";
CM_ SG_ 3221225472 FWSend_FileStart_FileSize "FIle size of firmware image.";
CM_ SG_ 3221225472 FWSend_BlockFragment_FragmentDat "The image file is split into multiple blocks, each block is split into multiple fragments.";
CM_ SG_ 3221225472 AUXREG_ChallengeTimeOut "This setting is only applied to parameter type = 10 TimeOut setting.";
CM_ SG_ 3221225472 CFGCMD_SN_3TO7BYTES "SN:Byte 2~6 (5 bytes)";
CM_ SG_ 3221225472 CFGCMD_SN_8TO12BYTES "SN:Byte 7~11 (5 bytes)";
CM_ SG_ 3221225472 CFGCMD_SN_LST4BYTES "SN:Byte 12~15 (4 bytes)";
CM_ BO_ 128 "System request consumed by all the nodes on the bus";
CM_ SG_ 128 SYSREQ_RequestID "Rolling counter used to correlate responses with requests (see *_ResponseID)";
CM_ SG_ 128 SYSREQ_RequestType "Specify which type of response message should be sent back";
CM_ SG_ 128 SYSREQ_GatewayOffset "XRCC uses this value to set its own CAN address by offsetting its physical addresss";
CM_ SG_ 128 SYSREQ_ExitRestMode "Command battery modules to exit rest mode and top up charge";
CM_ SG_ 128 SYSREQ_AcknowledgeAlarm "System acknowledges alarm raised by modules";
CM_ SG_ 128 SYSREQ_EnterManualControlMode "Definition:
1 : Enable BMS to accept extra command that asks the operation of D-FET,C-FET and trickle. This bit has to refresh every 30 seconds; otherwise, the BMS reverts back automatic mode.
0 : Disable/Exit manual control mode.";
CM_ BO_ 256 "Version and static information. CAN ID range: 0x100-0x17F where last 7 bits indicate node address";
CM_ SG_ 256 VER_ResponseID "Request id that this message is in response to (see SYSREQ_RequestID)";
CM_ SG_ 256 VER_ProtocolVersion "The version of this communication protocol";
CM_ SG_ 256 VER_SoftwareVersionMajor "Software major version # (major.minor.build)";
CM_ SG_ 256 VER_SoftwareVersionMinor "Software minor version # (major.minor.build)";
CM_ SG_ 256 VER_SoftwareVersionBuild "Software build version # (major.minor.build)";
CM_ SG_ 256 VER_InServiceDate "
";
CM_ SG_ 256 VER_ManufactureYear "Year of manufacture date";
CM_ SG_ 256 VER_ManufactureDay "Day of the year of manufacture date (1-366)";
CM_ SG_ 256 VER_ManufactureSerial "Serial number within the specific dat of manufacture";
CM_ SG_ 256 VER_ManufactureDate "Manufactur Date in SE format since 2000/01/01.";
CM_ SG_ 256 VER_SerialNumber1 "Block 1/3 of serial number encoded in ASCII. Entire serial number is limited to 16 ASCII bytes.";
CM_ SG_ 256 VER_SerialNumber2 "Block 2/3 of serial number encoded in ASCII. Entire serial number is limited to 16 ASCII bytes.";
CM_ SG_ 256 VER_SerialNumber3 "Block 3/3 of serial number encoded in ASCII. Entire serial number is limited to 16 ASCII bytes.";
CM_ SG_ 256 VER_PartNumber1 "Block 1/3 of part number encoded in ASCII. Entire part number is limited to 16 ASCII bytes.";
CM_ SG_ 256 VER_PartNumber2 "Block 2/3 of part number encoded in ASCII. Entire part number is limited to 16 ASCII bytes.";
CM_ SG_ 256 VER_PartNumber3 "Block 3/3 of part number encoded in ASCII. Entire part number is limited to 16 ASCII bytes.";
CM_ SG_ 256 VER_SeriesConfiguration "Series configuration of the battery, for example 56S2P = 56";
CM_ SG_ 256 VER_ParallelConfiguration "Parallel configuration of the battery, for example 56S2P = 2";
CM_ SG_ 256 VER_DesignCapacity "Theoretical capacity of the battery";
CM_ SG_ 256 VER_DesignVoltage "Theoretical voltage of the battery";
CM_ SG_ 256 VER_DesignPower "Nominal Power capability of the battery";
CM_ SG_ 256 VER_SoftwareAvailableMajor "Availabe firmware major version in serial flash # (major.minor.build)";
CM_ SG_ 256 VER_SoftwareAvailableMinor "Availabe firmware minor version in serial flash # (major.minor.build)";
CM_ SG_ 256 VER_SoftwareAvailableBuild "Availabe firmware build version in serial flash # (major.minor.build)";
CM_ SG_ 256 VER_XrccFwVerString1 "SE only. ";
CM_ SG_ 256 VER_XrccFwVerString2 "SE only. ";
CM_ SG_ 256 VER_XrccAvlblFwVerString1 "SE only. ";
CM_ SG_ 256 VER_XrccAvlblFwVerString2 "SE only. ";
CM_ BO_ 512 "Measurement and status summary. CAN ID range: 0x200-0x27F where last 7 bits indicate node address";
CM_ SG_ 512 MDAT_ResponseID "Request id that this message is in response to (see SYSREQ_RequestID)";
CM_ SG_ 512 MDAT_ShutdownImminent "The battery would suhtdown after 90 seconds. It was 30 secs.";
CM_ SG_ 512 MDAT_NewFirmwareAvailable "Set when the firmware in the serial flash is valid.";
CM_ SG_ 512 MDAT_Voltage "The voltage measured at the cell side of the battery module i.e. before CFET and DFET.";
CM_ SG_ 512 MDAT_BatteryStatus "1:Enabled(close), 0:Disabled(open)
Bit0 : D-FET
Bit1 : C-FET 
Bit2 : Trickle
Bit3~11 : Reserved(TBD)";
CM_ SG_ 512 MDAT_BatterySwitchOpen "(This is optional for project dependncy)
1: open, not engaged.
0: close, engaged.";
CM_ SG_ 512 MDAT_TimeNow "Time since battery controller power up";
CM_ SG_ 512 MDAT_VoltageBus "The voltage measured at the bus side of the battery module i.e. after CFET and DFET.";
CM_ SG_ 512 MDAT_ChargeVoltageRequest "The voltage that the battery ideally wants from charger (the system may not be able to provide it).";
CM_ SG_ 512 MDAT_RunTimeCalRequired "Battery needs a learning cycle.";
CM_ SG_ 512 MDAT_RunTimeCalConditionMet "Battery laerning cycle condition is met.";
CM_ SG_ 512 MDAT_RTCalDischargeToLowSOC "Battery needs a discharging during learning cycle until SOC< 10%(depends).";
CM_ SG_ 512 MDAT_RunTimeCalStayAtEmpty "Keep battery without discharging and charging. The UPS system provides 135 VDC to survive batery control power. ";
CM_ SG_ 512 MDAT_RunTimeCalChargeToFull "Battery needs charging.";
CM_ SG_ 512 MDAT_RunTimeCalStayAtFull "Keep battery without discharging and charging. No need to provide battery bus voltage.";
CM_ SG_ 512 MDAT_RunTimeCalSuccess "Battery learning cycle succeeds.";
CM_ SG_ 512 MDAT_RunTimeCalProcessing "Battery learning cycle is in progress.";
CM_ SG_ 512 MDAT_RunTimeCalTimeout "battery learning cycle was failed due to staying time less than 2 hours.";
CM_ SG_ 512 MDAT_ChargeCurrentMax "The maximum charger current that the module can take (the module may want to derate charger current from 1C due to thermal reasons)";
CM_ SG_ 512 MDAT_VolProtectionCov "COV (Cell Over Voltage Protection)";
CM_ SG_ 512 MDAT_VolProtectionPov "POV (Pack Over Voltage Protection)";
CM_ SG_ 512 MDAT_VolProtectionEocv "EOCV (End-of-Charge Voltage Protection)";
CM_ SG_ 512 MDAT_VolProtectionCuv "CUV (Cell Under Voltage Protection)";
CM_ SG_ 512 MDAT_VolProtectionPuv "PUV (Pack Under Voltage Protection)";
CM_ SG_ 512 MDAT_VolProtectionOimbv "OIMBV (Over Imbalance Voltage Protection)";
CM_ SG_ 512 MDAT_CurProtectionOci "OCI (Over Charge Current Protection)";
CM_ SG_ 512 MDAT_CurProtectionOdi_1 "ODI_1 (Over Discharge Current Protection 1)";
CM_ SG_ 512 MDAT_CurProtectionOdi_2 "ODI_2 (Over Discharge Current Protection 2)";
CM_ SG_ 512 MDAT_CurProtectionOdi_3 "ODI_3 (Over Discharge Current Protection 3)";
CM_ SG_ 512 MDAT_CurProtectionOdi_4 "ODI_4 (Over Discharge Current Protection 4)";
CM_ SG_ 512 MDAT_CurProtectionH_Odi "H_ODI (Hardware Over Discharge Current Protection)";
CM_ SG_ 512 MDAT_CurProtectionH_Sci "H_SCI (Hardware Short-Circuit Current Protection)";
CM_ SG_ 512 MDAT_TemProtectionCot "COT (Charge Over Temperature Protection)";
CM_ SG_ 512 MDAT_TemProtectionDot "DOT (Discharge Over Temperature Protection)";
CM_ SG_ 512 MDAT_TemProtectionCut "CUT (Charge Under Temperature Protection)";
CM_ SG_ 512 MDAT_TemProtectionDut "DUT (Discharge Under Temperature Protection)";
CM_ SG_ 512 MDAT_TemProtectionMot "MOT (MOSFET Over Temperature Protection)";
CM_ SG_ 512 MDAT_FaultIndicateUvpf "UVPF (Under Voltage Permanent Failure)";
CM_ SG_ 512 MDAT_FaultIndicateOvpf "OVPF (Over Voltage Permanent Failure)";
CM_ SG_ 512 MDAT_FaultIndicateOtpf "OTPF (Over Temperature Permanent Failure)";
CM_ SG_ 512 MDAT_FaultIndicateFusepf "FUSEPF (FUSE Permanent Failure)";
CM_ SG_ 512 MDAT_FaultIndicateCimpf "CIMPF (Cell Imbalance Permanent Failure)";
CM_ SG_ 512 MDAT_FaultIndicateThopf "THOPF (Thermister Open Permanent Failure)";
CM_ SG_ 512 MDAT_FaultIndicateThspf "THSPF (Thermister Short Permanent Failure)";
CM_ SG_ 512 MDAT_FaultIndicateCfetpf "CFETPF (Charge FET Permanent Failure)";
CM_ SG_ 512 MDAT_FaultIndicateDfetpf "DFETPF (Discharge FET Permanent Failure)";
CM_ SG_ 512 MDAT_UL60730_BQF "BQ_F (BQ I2C Failure)";
CM_ SG_ 512 MDAT_UL60730_MCU_IO_F "MCU-IO_F (MCU IO Failure)";
CM_ SG_ 512 MDAT_UL60730_MCU_CLK_F "MCU-CLK_F (MCU Clock Failure)";
CM_ SG_ 512 MDAT_UL60730_MCU_PC_F "MCU-PC_F (MCU Program Counter Failure)";
CM_ SG_ 512 MDAT_UL60730_MCU_REG_F "MCU-REG_F (MCU Register Failure)";
CM_ SG_ 512 MDAT_UL60730_MCU_WDT_F "MCU-WDT_F (MCU Watching Dog Failure)";
CM_ SG_ 512 MDAT_UL60730_MCU_RAM_F "MCU-RAM_F (MCU RAM Failure)";
CM_ SG_ 512 MDAT_UL60730_MCU_FLASH_F "MCU-FLASH_F (MCU Flash Failure)";
CM_ SG_ 512 MDAT_UL60730_MCU_EE_F "MCU-EE_F (MCU EEPROM Failure)";
CM_ SG_ 512 MDAT_GaugeCode "Gauge IC status code. (optional)";
CM_ SG_ 512 MDAT_BmsState "State of Battery Module";
CM_ SG_ 512 MDAT_TimeToFullCharge "unit in 1 second.";
CM_ SG_ 512 MDAT_RemainingRunTime "unit in 1 second.";
CM_ SG_ 512 MDAT_TSensorDisconnected "Thermal Sensor Disconnected or bad.";
CM_ SG_ 512 MDAT_ReplaceBatteryNow "Set when SOH <60%, clear when SOH > 65%";
CM_ SG_ 512 MDAT_ReplaceBPInNearFuture "Set when SOH <70%, clear when SOH > 75%";
CM_ SG_ 512 MDAT_A100xChipIssue "A1006 failes to read or write, etc.";
CM_ SG_ 512 MDAT_AFE_Fault "Analog front end fault.";
CM_ SG_ 512 MDAT_XrccPresent "SE Only.";
CM_ SG_ 512 MDAT_BatteryModulePresent1 "SE Only .";
CM_ SG_ 512 MDAT_BatteryModulePresent2 "SE Only.";
CM_ SG_ 512 MDAT_BatteryModulePresent3 "SE Only.";
CM_ SG_ 512 MDAT_BatteryModulePresent4 "SE Only.";
CM_ SG_ 512 MDAT_ProjectBmCurrent "0 = 0mA, 100 = 1A.";
CM_ SG_ 512 MDAT_FanPwmDutyCycly "Percentage";
CM_ SG_ 512 MDAT_FanProportionalTime "Increment the counter by 1 every  100%/FAN_SPEED% Second.
For example:
At 100% speed the copunter gets incremented every 1 second.
At 50% speed the copunter gets incremented every 2 seconds.
At 25% speed the copunter gets incremented every 4 seconds.";
CM_ BO_ 768 "Cell Temperature measurements. CAN ID range: 0x300-0x37F where last 7 bits indicate node address";
CM_ SG_ 768 CDAT0_ResponseID "Request id that this message is in response to (see SYSREQ_RequestID)";
CM_ SG_ 768 CDAT0_Temperature_01 "Temperature sensor";
CM_ SG_ 768 CDAT0_Temperature_02 "Temperature sensor";
CM_ SG_ 768 CDAT0_Temperature_03 "Temperature sensor";
CM_ SG_ 768 CDAT0_Temperature_04 "Temperature sensor";
CM_ SG_ 768 CDAT0_Temperature_05 "Temperature sensor";
CM_ SG_ 768 CDAT0_Temperature_06 "Temperature sensor";
CM_ SG_ 768 CDAT0_Temperature_07 "Temperature sensor";
CM_ SG_ 768 CDAT0_Temperature_08 "Temperature sensor";
CM_ SG_ 768 CDAT0_Temperature_09 "Temperature sensor";
CM_ BO_ 896 "Cell balancing status. CAN ID range: 0x380-0x3FF where last 7 bits indicate node address";
CM_ SG_ 896 CDAT1_ResponseID "Request id that this message is in response to (see SYSREQ_RequestID)";
CM_ BO_ 1024 "Cell1-50 voltage measurements. CAN ID range: 0x400-0x47F where last 7 bits indicate node address";
CM_ SG_ 1024 CDAT2_ResponseID "Request id that this message is in response to (see SYSREQ_RequestID)";
CM_ BO_ 1920 "Vendor specific data - Details TBD. CAN ID range: 0x780-0x7FF where last 7 bits indicate node address";
CM_ SG_ 1920 VDAT_ResponseID "Request id that this message is in response to (see SYSREQ_RequestID)";
CM_ SG_ 1920 VDAT_BLVersion_Major "Availabe bootloader major version in serial flash # (major.minor.build)
";
CM_ SG_ 1920 VDAT_BLVersion_Minor "Availabe bootloader minor version in serial flash # (major.minor.build)";
CM_ SG_ 1920 VDAT_BLVersion_Build "Availabe bootloader build version in serial flash # (major.minor.build)";
CM_ SG_ 1920 VDAT_RTCTS_YEAR "RTC Time corresponding to year
";
CM_ SG_ 1920 VDAT_RTCTS_MON "RTC time corresponds to months in a year
";
CM_ SG_ 1920 VDAT_RTCTS_DAY "RTC time corresponds to number of days in a year";
CM_ SG_ 1920 VDAT_RTCTS_HOUR "RTC time corresponds to hours in a day
";
CM_ SG_ 1920 VDAT_RTCTS_MIN "RTC time corresponds to minutes in a hour";
CM_ SG_ 1920 VDAT_RTCTS_SEC "RTC time corresponds to seconds in a minute";
CM_ SG_ 1920 VDAT_SoC "State of Charge in Percentage( 0 to 100%) based on 2.9v to 4.0v";
CM_ BO_ 1792 "Lifetime Status. CAN ID range: 0x700-0x77F where last 7 bits indicate node address";
CM_ SG_ 1792 LDAT_ResponseID "Request id that this message is in response to (see SYSREQ_RequestID)";
CM_ SG_ 1792 LDAT_DischargeEnergy_Total "The cumulative energy (WHr) delivered by the module while discharging";
CM_ SG_ 1792 LDAT_CellVoltage_Min "The lowest recorded cell voltage";
CM_ SG_ 1792 LDAT_CellVoltage_Max "The highest recorded cell voltage";
CM_ SG_ 1792 LDAT_ChargeEnergy_Total "The cumulative energy (WHr) received by the module while charging";
CM_ SG_ 1792 LDAT_InternalVoltage_Min "The lowest recorded module internal voltage (measured before the disconnect switch)";
CM_ SG_ 1792 LDAT_InternalVoltage_Max "The highest recorded module internal voltage  (measured before the disconnect switch)";
CM_ SG_ 1792 LDAT_TimeDischarging_Total "The total time that the module is supplying current to the bus";
CM_ SG_ 1792 LDAT_DischargeCurrent_Max "The highest recorded discharging current (sum of all internal strings, if more than one)";
CM_ SG_ 1792 LDAT_Temperature_Max "The highest recorded module temperature";
CM_ SG_ 1792 LDAT_TimeCharging_Total "The total time that the module is charging at any rate";
CM_ SG_ 1792 LDAT_ChargeCurrent_Max "The highest recorded charing current (sum of all internal strings if more than one)";
CM_ SG_ 1792 LDAT_Temperature_Min "The lowest recorded module temperature";
CM_ SG_ 1792 LDAT_TimeResting_Total "The total time where the module is at 100% SOC and is not charging";
CM_ SG_ 1792 LDAT_ChargePower_Max "The highest recorded charging power";
CM_ SG_ 1792 LDAT_Temperature_Avg "The time weighted average of all temperature sensors in the module over the service life (for example - calculated every second and stored to non-volatile memory hourly)";
CM_ SG_ 1792 LDAT_TimeBrainsUp_Total "The total time that the module's microcontroller is active";
CM_ SG_ 1792 LDAT_DischargePower_Max "The highest recorded discharging power";
CM_ SG_ 1792 LDAT_NDischargeEvents "The number of discharges that last longer than 30 seconds.";
CM_ SG_ 1792 LDAT_NDeepDischargeEvents "The number of discharges to 20% of SOC or below";
CM_ SG_ 1792 LDAT_DaysReamingLifeExpired "Battery life would be expired after the number of days.";
CM_ SG_ 1792 LDAT_DCIRCell_Min "The DCIR measurement for the weakest cell";
CM_ SG_ 1792 LDAT_DCIRString "The DCIR measurement for the module (sum of all the cell DCIR)";
CM_ SG_ 1792 LDAT_TimeShipMode_Total "The total time that the module spent in shipping mode";
CM_ SG_ 1792 LDAT_SOHInternal "State of Health based on weighted average of capacity degradation and DCIR increase (This SOH value should not vary based on current temperature value)";
CM_ SG_ 1792 LDAT_DischargeLT20PerCntr "Number of discharge < 20%
Increment by 1, if at the end of discharge SOC is in this bucket, this is regardless of the SOC at beginning of dischare.";
CM_ SG_ 1792 LDAT_DischgG20LT40PerCntr "Number of discharge between 20% and 39%";
CM_ SG_ 1792 LDAT_DischgG40LT60PerCntr "Number of discharge between 40% and 59%";
CM_ SG_ 1792 LDAT_DischgG60LT80PerCntr "Number of discharge between 60% and 79%";
CM_ SG_ 1792 LDAT_DischgG80PerCntr "Number of discharge >= 80% ";
CM_ BO_ 160 "Used to send BMC's firmware binary file to the battery modules. Refer to BMFTP protocol description for details for the definitions of the payload data.";
CM_ SG_ 160 FWSend_FileStart_Command "It is fixed to 0x1.";
CM_ SG_ 160 FWSend_FileStart_Reserved "It should be set to be 0x00 now.";
CM_ BO_ 161 "Used to send XRCC's firmware binary file to the XRCC. Refer to BMFTP protocol description for details for the definitions of the payload data.";
CM_ BO_ 176 "If new firmware is available, then install it. This is command is obeyed by the node it matches the node address or broadcast address. This command is not obeyed if the battery is discharging.";
CM_ BO_ 240 "Optional Command: command LED to light indivisually based on the bit set.";
CM_ SG_ 240 FTCMD_RequestID "Rolling counter used to correlate responses with requests (see *_ResponseID)";
CM_ SG_ 240 FTCMD_Led "Bit0 =  LED0(GRN), Bit1 =  LED1(YEL), Bit2(RED), Bit3 = LED3. Automatically exit after 10 seconds.";
CM_ SG_ 240 FTCMD_TargetNode "Command target address to respond. When command is 0xFF, it means all nodes; otherwise, only one single node to respond. The max available node is 7 bits; therefore, 0xFF is out of available node and for all nodes.  

0xFF means all nodes(addresses)
0x1 represents address 1.
0x6 represents address 6.";
CM_ SG_ 240 FTCMD_TargetAction "0: Exit LED command mode immediately.
1: Light up LED
2: Light off LED
3. Flash LED";
CM_ BO_ 144 "Auxillary system request consumend by all nodes on the bus";
CM_ SG_ 144 AUXREQ_RequestType "Specify which type of auxilary response message should be sent back. This is a multi fragment message with different interpretation of parameters based on the type of the request.";
CM_ SG_ 144 AUXREQ_RequestID "Rolling counter used to correlate responses with auxilary requests (see AUXRESP_ResponseID)";
CM_ SG_ 144 AUXREQ_RequestNParameters "The number of parameter to expect for this request.";
CM_ SG_ 144 AUXREQ_RequestTargetNodeAddress "The response for this request should come from the node with this address.

Command target address to respond.   

0xFF means all nodes(addresses)
0x1 represents address 1.
0x6 represents address 6.";
CM_ SG_ 144 AUXREQ_RequestParameter0 "Parameter to the AUXREQ_RequestType. The meaning depends on the type of request.";
CM_ SG_ 144 AUXREQ_RequestParameter1 "Parameter to the AUXREQ_RequestType. The meaning depends on the type of request.";
CM_ SG_ 144 AUXREQ_RequestParameter2 "Parameter to the AUXREQ_RequestType. The meaning depends on the type of request.";
CM_ SG_ 144 AUXREQ_RequestParameter3 "Parameter to the AUXREQ_RequestType. The meaning depends on the type of request.";
CM_ SG_ 144 AUXREQ_RequestParameter4 "Parameter to the AUXREQ_RequestType. The meaning depends on the type of request.";
CM_ SG_ 144 AUXREQ_RequestParameter5 "Parameter to the AUXREQ_RequestType. The meaning depends on the type of request.";
CM_ SG_ 144 AUXREQ_RequestParameter6 "Parameter to the AUXREQ_RequestType. The meaning depends on the type of request.";
CM_ SG_ 144 AUXREQ_RequestParameter7 "Parameter to the AUXREQ_RequestType. The meaning depends on the type of request.";
CM_ SG_ 144 AUXREQ_RequestParameter8 "Parameter to the AUXREQ_RequestType. The meaning depends on the type of request.";
CM_ SG_ 144 AUXREQ_RequestParameter9 "Parameter to the AUXREQ_RequestType. The meaning depends on the type of request.";
CM_ SG_ 144 AUXREQ_RequestParameter10 "Parameter to the AUXREQ_RequestType. The meaning depends on the type of request.";
CM_ SG_ 144 AUXREQ_RequestParameter11 "Parameter to the AUXREQ_RequestType. The meaning depends on the type of request.";
CM_ SG_ 144 AUXREQ_RequestParameter12 "Parameter to the AUXREQ_RequestType. The meaning depends on the type of request.";
CM_ SG_ 144 AUXREQ_RequestParameter13 "Parameter to the AUXREQ_RequestType. The meaning depends on the type of request.";
CM_ SG_ 144 AUXREQ_RequestParameter14 "Parameter to the AUXREQ_RequestType. The meaning depends on the type of request.";
CM_ SG_ 144 AUXREQ_RequestParameter15 "Parameter to the AUXREQ_RequestType. The meaning depends on the type of request.";
CM_ BO_ 1664 "Response to auxilary request. CAN ID range: 0x680-0x6FF where last 7 bits indicate node address";
CM_ SG_ 1664 AUXRESP_ResponseType "Request type that this message is in response to (see AUXREQ_RequestType)";
CM_ SG_ 1664 AUXRESP_ResponseID "Request id that this message is in response to (see AUXREQ_RequestID)";
CM_ SG_ 1664 AUXRESP_ResponseNParameters "The number of parameter to expect for this request.";
CM_ SG_ 1664 AUXRESP_ResponseErrorType "Return error type information. 0 = Good.";
CM_ SG_ 1664 AUXRESP_ResponseParameter0 "Parameter to the AUXRESP_ResponseType. The meaning depends on the type of response.";
CM_ SG_ 1664 AUXRESP_ResponseParameter1 "Parameter to the AUXRESP_ResponseType. The meaning depends on the type of response.";
CM_ SG_ 1664 AUXRESP_ResponseParameter2 "Parameter to the AUXRESP_ResponseType. The meaning depends on the type of response.";
CM_ SG_ 1664 AUXRESP_ResponseParameter3 "Parameter to the AUXRESP_ResponseType. The meaning depends on the type of response.";
CM_ SG_ 1664 AUXRESP_ResponseParameter4 "Parameter to the AUXRESP_ResponseType. The meaning depends on the type of response.";
CM_ SG_ 1664 AUXRESP_ResponseParameter5 "Parameter to the AUXRESP_ResponseType. The meaning depends on the type of response.";
CM_ SG_ 1664 AUXRESP_ResponseParameter6 "Parameter to the AUXRESP_ResponseType. The meaning depends on the type of response.";
CM_ SG_ 1664 AUXRESP_ResponseParameter7 "Parameter to the AUXRESP_ResponseType. The meaning depends on the type of response.";
CM_ SG_ 1664 AUXRESP_ResponseParameter8 "Parameter to the AUXRESP_ResponseType. The meaning depends on the type of response.";
CM_ SG_ 1664 AUXRESP_ResponseParameter9 "Parameter to the AUXRESP_ResponseType. The meaning depends on the type of response.";
CM_ SG_ 1664 AUXRESP_ResponseParameter10 "Parameter to the AUXRESP_ResponseType. The meaning depends on the type of response.";
CM_ SG_ 1664 AUXRESP_ResponseParameter11 "Parameter to the AUXRESP_ResponseType. The meaning depends on the type of response.";
CM_ SG_ 1664 AUXRESP_ResponseParameter12 "Parameter to the AUXRESP_ResponseType. The meaning depends on the type of response.";
CM_ SG_ 1664 AUXRESP_ResponseParameter13 "Parameter to the AUXRESP_ResponseType. The meaning depends on the type of response.";
CM_ SG_ 1664 AUXRESP_ResponseParameter14 "Parameter to the AUXRESP_ResponseType. The meaning depends on the type of response.";
CM_ SG_ 1664 AUXRESP_ResponseParameter15 "Parameter to the AUXRESP_ResponseType. The meaning depends on the type of response.";
CM_ BO_ 241 "Config settings forthe PWM duty of FAN, etc.";
CM_ SG_ 241 CFGCMD_RequestID "Rolling counter used to correlate responses with requests (see *_ResponseID)";
CM_ SG_ 241 CFGCMD_ReauestType "
FANPWM : set the percentage with the parameters max 100.

RUNTIMECALSET/RESET: asks battery module to perform run time calibration or cancel it. 

CLEARFAULT: clear all fault flags including fake faults for once, not affect subsequent conditions.

FORCEFAULT: Force battery module to raise the corresponding fault bit to the UPS system. The purpose is to verify the interaction between the UPS system and battery modules. This command could continue setting so there would be more than 2 fault bits existing at the same time. Note: the firmware for this portion does not allow to apply to the PVT firmware, only EVT or DVT.

PERAMETERS: for FANPWM duty, FORCEFAULT, WRITEVENDORCODE, IN_SERVICE_DATE, ATTACHED_UPS_SKU, and PROJECT_BM_CURRENT";
CM_ SG_ 241 CFGCMD_TargetNode "For 0xFF for all nodes else specifies a single node number.";
CM_ SG_ 241 CFGCMD_Parameters "For FANPWM, the max is 100
For FORCEFAULT, it depends on the number. No response if the number indicates wrongly.
For WRITEVENDORCODE, 16 bits width. Reading it takes from VER.
For RMA_SERIAL_NUMBER, 16 bits width. Reading it takes from VER.
For IN_SERVICE_DATE,  16 bits width.
For ATTACHED_UPS_SKU, 8 bits width.
For PROJECT_BM_CURRENT, 16 bits width. Each count means 10mA. Ex, 300(=3A) ";
CM_ SG_ 241 CFGCMD_SN_1ST2BYTES "SN:Byte 0~1 (2 bytes)
";
CM_ BO_ 242 "Read out the log in the serial flash.";
CM_ SG_ 242 EVENTLOG_RequestID "Rolling counter used to correlate responses with requests (see *_ResponseID)";
CM_ SG_ 242 EVENTLOG_RequestType "Specify which type of response message should be sent back";
CM_ SG_ 242 EVENTLOG_SinceLastTimeToReadOut "0xFFFFFFFF is a SPECIAL number to erase all logs dependent on the Erase type of RequestType. 0x7FFFFFFF is the maximum value for Recent seconds or Erase counts.

For example, 
258 means 258 seconds dependent on the type Recent of RequestType. Or
368 means to adjust the index to deduct 368 logs dependent on the type Erase of RequestType. This request can change the index instead of physical deletion. 

  
";
CM_ BO_ 1536 "Response to EVENTLOG request. CAN ID range: 0x600-0x67F where last 7 bits indicate node address. The read index will rewind to last + 1 after 10 seconds without communication(timeout).";
CM_ SG_ 224 CFGCMD2_RequestID "Rolling counter";
CM_ SG_ 224 CFGCMD2_RequestType "0x0: Manufacturing details
0x1 : Serial number
0x2: Part number
0x3: Key
0x4: RTC
0x5: Vendor code
0x6: Attached UPS SKU
0xFF: SW_Protection_Modification";
CM_ SG_ 224 CFGCMD2RequestNparameter "Number of Mux messages";
CM_ SG_ 224 CFGCMD2_Parameter1 "Parameter to CFGCMD2_RequestType";
CM_ SG_ 224 CFGCMD2_Parameter2 "Parameter to CFGCMD2_RequestType
";
CM_ SG_ 224 CFGCMD2_Parameter3 "Parameter to CFGCMD2_RequestType
";
CM_ SG_ 224 CFGCMD2_Parameter4 "Parameter to CFGCMD2_RequestType
";
CM_ SG_ 224 CFGCMD2_Parameter5 "Parameter to CFGCMD2_RequestType
";
CM_ SG_ 224 CFGCMD2_Parameter6 "Parameter to CFGCMD2_RequestType
";
CM_ SG_ 224 CFGCMD2_Parameter7 "Parameter to CFGCMD2_RequestType
";
CM_ SG_ 224 CFGCMD2_Parameter8 "Parameter to CFGCMD2_RequestType
";
CM_ SG_ 224 CFGCMD2_Parameter9 "Parameter to CFGCMD2_RequestType
";
CM_ SG_ 224 CFGCMD2_Parameter10 "Parameter to CFGCMD2_RequestType
";
CM_ SG_ 224 CFGCMD2_Parameter11 "Parameter to CFGCMD2_RequestType
";
CM_ SG_ 224 CFGCMD2_Parameter12 "Parameter to CFGCMD2_RequestType
";
CM_ SG_ 224 CFGCMD2_Parameter13 "Parameter to CFGCMD2_RequestType
";
CM_ SG_ 224 CFGCMD2_Parameter14 "Parameter to CFGCMD2_RequestType
";
CM_ SG_ 224 CFGCMD2_Parameter15 "Parameter to CFGCMD2_RequestType
";
CM_ BO_ 225 "Request used to get diagnostic values";
CM_ SG_ 225 DIAGREQ_RequestType "
";
CM_ BO_ 1280 "Diagnostics about status informations in battery pack";
CM_ SG_ 1280 DIAGSTS_ResponseID "Rolling counter";
CM_ SG_ 1280 DIAGSTS_ServiceDisconnect "Status diagnostics of service disconnect switch";
CM_ SG_ 1280 DIAGSTS_LPSON "Status diagnostics of LPS ON";
CM_ SG_ 1280 DIAGSTS_BM_PWR_RDY "Status diagnostics of BM power ready switch";
CM_ SG_ 1280 DIAGSTS_BM_LPS_ON_CMD "Status diagnostics of LPS ON command";
CM_ SG_ 1280 DIAGSTS_ChargeDisconnect "Status diagnostics of charge disconnect";
CM_ SG_ 1280 DIAGSTS_DischargeDisconnect "Status diagnostics of discharge disconnect";
CM_ SG_ 1280 DIAGSTS_TrickleDisconnect "Status diagnostics of trickle charge disconnect";
CM_ SG_ 1280 DIAGSTS_Led1 "Status diagnostics of LED 1";
CM_ SG_ 1280 DIAGSTS_Led2 "Status diagnostics of LED2";
CM_ SG_ 1280 DIAGSTS_ThermalSensorDisconnecte "Status diagnostics of thermal sensor disconnected";
CM_ SG_ 1280 DIAGSTS_Thermisteropf "Status diagnostics of thermister open permanent failure";
CM_ SG_ 1280 DIAGSTS_FaultIndicateThspf "Status diagnostics of thermister short permanent failure";
CM_ SG_ 1280 DIAGSTS_FaultIndicateCfetpf "Status diagnostics of fault indicate CFET  permanent failure";
CM_ SG_ 1280 DIAGSTS_FaultIndicateDfetpf "Status diagnostics of fault indicate DFET  permanent failure";
CM_ SG_ 1280 DIAGSTS_FanFault "Status diagnostics of fan fault";
CM_ SG_ 1280 DIAGSTS_HardwareFault "Status diagnostics of hardware failure";
CM_ SG_ 1280 DIAGSTS_VBus_Sense_Fault "Status diagnostics of bus voltage sense failure";
CM_ SG_ 1280 DIAGSTS_VBAT_Sense_Fault "Status diagnostics of battery voltage sense failure";
CM_ SG_ 1280 DIAGSTS_AFE_Fault "Status diagnostics of AFE failure";
CM_ SG_ 1280 DIAGSTS_FaultIndicateOtpf "Status diagnostics of  over temperature permanent failure indication
";
CM_ SG_ 1280 DIAGSTS_FaultIndicateFusepf "Status diagnostics of  fuse permanent failure indication";
CM_ SG_ 1280 DIAGSTS_TemProtectionMot "Status diagnostics of MOSFET over temperature protection";
CM_ SG_ 1280 DIAGSTS_DIAGSTS_SOH_Low "Status diagnostics of  SOH low";
CM_ SG_ 1280 DIAGSTS_VolProtectionOimbv "Status diagnostics of voltage protection over voltage imbalance";
CM_ SG_ 1280 DIAGSTS_FaultIndicateCimpf "Status diagnostics of charge imbalance permanent fault";
CM_ SG_ 1280 DIAGSTS_VolProtectionCov "Status diagnostics of voltage protection cell over voltage";
CM_ SG_ 1280 DIAGSTS_VolProtectionCuv "Status diagnostics of voltage protection cell under voltage";
CM_ SG_ 1280 DIAGSTS_VolProtectionPov "Status diagnostics of voltage protection pack over voltage";
CM_ SG_ 1280 DIAGSTS_VolProtectionPuv "Status diagnostics of voltage protection pack under voltage";
CM_ SG_ 1280 DIAGSTS_FaultIndicateUvpf "Status diagnostics of under voltage permanent fault indication ";
CM_ SG_ 1280 DIAGSTS_FaultIndicateOvpf "Status diagnostics of over voltage permanent fault indication";
CM_ SG_ 1280 DIAGSTS_HW_BatteryUV "Status diagnostics of hardware battery under voltage";
CM_ SG_ 1280 DIAGSTS_HW_BatteryOV "Status diagnostics of hardware battery over voltage ";
CM_ SG_ 1280 DIAGSTS_TemProtectionCot "Status diagnostics of charge over temperature protection";
CM_ SG_ 1280 DIAGSTS_TemProtectionCut "Status diagnostics of charge under temperature protection";
CM_ SG_ 1280 DIAGSTS_TemProtectionDot "Status diagnostics of discharge over temperature protection";
CM_ SG_ 1280 DIAGSTS_TemPotectionDut "Status diagnostics of charge under temperature protection";
CM_ SG_ 1280 DIAGSTS_CurProtectionOci "Status diagnostics of  over charge current protection indication ";
CM_ SG_ 1280 DIAGSTS_CurProtectionOdi_1 "Status diagnostics of over discharge current level 1 protection indication";
CM_ SG_ 1280 DIAGSTS_CurProtectionOdi_2 "Status diagnostics of over discharge current level 2 protection indication";
CM_ SG_ 1280 DIAGSTS_CurProtectionOdi_3 "Status diagnostics of over discharge current level 3 protection indication";
CM_ SG_ 1280 DIAGSTS_CurProtectionOdi_4 "Status diagnostics of over discharge current level 4 protection indication";
CM_ SG_ 1280 DIAGSTS_CurProtectionH_Odi "Status diagnostics of over discharge current hardware level protection indication";
CM_ SG_ 1280 DIAGSTS_CurProtectionH_Sci "Status diagnostics of short circuit hardware level protection indication";
CM_ SG_ 1280 DIAGSTS_DFET_EN "Status diagnostics of DFET enable";
CM_ SG_ 1280 DIAGSTS_C1FET_EN "Status diagnostics of C1FET enable";
CM_ SG_ 1280 DIAGSTS_C2FET_EN "Status diagnostics of C2FET enable";
CM_ SG_ 1280 DIAGSTS_C1FET "Status diagnostics of C1FET";
CM_ SG_ 1280 DIAGSTS_C2FET "Status diagnostics of C2FET";
CM_ SG_ 1280 DIAGSTS_DFET "Status diagnostics of  DFET";
CM_ SG_ 1280 DIAGSTS_TFET "Status diagnostics of TFET";
CM_ SG_ 1280 DIAGSTS_SoftStart "Status diagnostics of soft start";
CM_ SG_ 1280 DIAGSTS_TrickleCharge_ON "Status diagnostics of trickle charge on ";
CM_ BO_ 1288 "Response which provides temperature sensor values ";
CM_ SG_ 1288 DIAGAFE_ResponseID "Rolling Counter";
CM_ SG_ 1288 DIAGAFE1_AFE1_Stackvoltage "Stack voltage of AFE1.";
CM_ SG_ 1288 DIAGAFE_AFE1_CSM_Temperature0 "Temperature sensor 0 value of AFE1 in CSM board.";
CM_ SG_ 1288 DIAGAFE_AFE1_CSM_Temperature1 "Temperature sensor 1 value of AFE1 in CSM board";
CM_ SG_ 1288 DIAGAFE_AFE1_Cell_Temperature0 "Temperature sensor 0 value in AFE1.";
CM_ SG_ 1288 DIAGAFE_AFE1_Cell_Temperature1 "Temperature sensor 1 value in AFE1.";
CM_ SG_ 1288 DIAGAFE_AFE1_Cell_Temperature2 "Temperature sensor 2 value in AFE1.";
CM_ SG_ 1288 DIAGAFE_AFE1_Cell_Temperature3 "Temperature sensor 3 value in AFE1.";
CM_ SG_ 1288 DIAGAFE_AFE2_Stackvoltage "Stack voltage of AFE2.";
CM_ SG_ 1288 DIAGAFE_AFE2_CSM_Temperature0 "Temperature sensor 0 value of AFE2 in CSM board.";
CM_ SG_ 1288 DIAGAFE_AFE2_CSM_Temperature1 "Temperature sensor 1 value of AFE2 in CSM board.";
CM_ SG_ 1288 DIAGAFE_AFE2_Cell_Temperature0 "Temperature sensor 0 value in AFE2.";
CM_ SG_ 1288 DIAGAFE_AFE2_Cell_Temperature1 "Temperature sensor 1 value in AFE2.";
CM_ SG_ 1288 DIAGAFE_AFE2_Cell_Temperature2 "Temperature sensor 2 value in AFE2.";
CM_ SG_ 1288 DIAGAFE_AFE2_Cell_Temperature3 "Temperature sensor 3 value in AFE2.";
CM_ SG_ 1288 DIAGAFE_AFE3_Stackvoltage "Stack voltage of AFE3";
CM_ SG_ 1288 DIAGAFE_AFE3_CSM_Temperature0 "Temperature sensor 0 value of AFE3 in CSM board.";
CM_ SG_ 1288 DIAGAFE_AFE3_CSM_Temperature1 "Temperature sensor 1 value of AFE3 in CSM board.";
CM_ SG_ 1288 DIAGAFE_AFE3_Cell_Temperature0 "Temperature sensor 0 value in AFE3.";
CM_ SG_ 1288 DIAGAFE_AFE3_Cell_Temperature1 "Temperature sensor 1 value in AFE2.";
CM_ SG_ 1288 DIAGAFE_AFE3_Cell_Temperature2 "Temperature sensor 2 value in AFE3.";
CM_ SG_ 1288 DIAGAFE_AFE3_Cell_Temperature3 "Temperature sensor 3 value in AFE3.";
CM_ SG_ 1288 DIAGAFE_AFE4_Stackvoltage "Stack voltage of AFE4";
CM_ SG_ 1288 DIAGAFE_AFE4_CSM_Temperature0 "Temperature sensor 0 value of AFE4 in CSM board.";
CM_ SG_ 1288 DIAGAFE_AFE4_CSM_Temperature1 "Temperature sensor 1 value of AFE4 in CSM board.";
CM_ SG_ 1288 DIAGAFE_AFE4_Cell_Temperature0 "Temperature sensor 0 value in AFE4.";
CM_ SG_ 1288 DIAGAFE_AFE4_Cell_Temperature1 "Temperature sensor 1 value in AFE4.";
CM_ SG_ 1288 DIAGAFE_AFE4_Cell_Temperature2 "Temperature sensor 2 value in AFE4.";
CM_ SG_ 1288 DIAGAFE_AFE4_Cell_Temperature3 "Temperature sensor 3 value in AFE4.";
CM_ SG_ 1288 DIAGAFE_AFE1_Fault "AFE1 fault";
CM_ SG_ 1288 DIAGAFE_AFE2_Fault "AFE2 fault";
CM_ SG_ 1288 DIAGAFE_AFE3_Fault "AFE3 fault";
CM_ SG_ 1288 DIAGAFE_AFE4_Fault "AFE4 fault";
CM_ SG_ 1288 DIAGAFE_AFE1_Communication "Fault for AFE1 communication.";
CM_ SG_ 1288 DIAGAFE_AFE2_Communication "Fault for AFE2 communication.";
CM_ SG_ 1288 DIAGAFE_AFE3_Communication "Fault for AFE3 communication.";
CM_ SG_ 1288 DIAGAFE_AFE4_Communication "Fault for AFE4 communication.";
CM_ BO_ 1304 "Diagnostics to provide life time data";
CM_ SG_ 1304 DIAGRESP_ResponseID "Rolling Counter";
CM_ SG_ 1304 DIAGRESP_DischargeEnergy "Diagnostic related response to get battery discharge energy value in Ah watts";
CM_ SG_ 1304 DIAGRESP_ChargeEnergy "Diagnostic related response to get battery charge energy value in Ah watts";
CM_ SG_ 1304 DIAGRESP_RemainingCapacity "Diagnostic related response to get battery remaining capacity value in Whr.";
CM_ SG_ 1304 DIAGRESP_Full_Chargecapacity "Diagnostic related response to get full charge capacity value in Whr.";
CM_ SG_ 1304 DIAGRESP_CumulativeEnergy "Diagnostic related response to get cumulative energy value in Whr.";
CM_ SG_ 1304 DIAGRESP_Batterystatus "1:Enabled(close), 0:Disabled(open)";
CM_ SG_ 1304 DIAGRESP_SOC "Diagnostic related response to get SOC value in percentage.";
CM_ SG_ 1304 DIAGRESP_SOH "Diagnostic related response to get SOH value in percentage.";
CM_ SG_ 1304 DIAGRESP_DOD "Diagnostic related response to get DOD value in percentage.";
CM_ SG_ 1304 DIAGRESP_CycleCount "Diagnostic related response to get charging cycle count value in percentage.";
CM_ SG_ 1304 DIAGRESP_DCIR "The DCIR measurement for the module (sum of all the cell DCIR)";
CM_ SG_ 1304 DIAGRESP_DCIRDeltaInPercentage "The DCIR measurement for the module (sum of all the cell DCIR) in percentage.";
CM_ SG_ 1304 DIAGRESP_CellMaxVtg "Diagnostic related response for maximum cell voltage.";
CM_ SG_ 1304 DIAGRESP_CellMinVtg "Diagnostic related response for minimum cell voltage.";
CM_ SG_ 1304 DIAGRESP_CellAvgVtg "Diagnostic related response for average cell voltage.";
CM_ SG_ 1304 DIAGRESP_NCellUV "Diagnostic related response for total cells under voltage value.";
CM_ SG_ 1304 DIAGRESP_NCellOV "Diagnostic related response for over voltage value.";
CM_ SG_ 1304 DIAGRESP_BMSStatus "Battery Management System State of Battery Module.";
CM_ SG_ 1304 DIAGRESP_CellMax_T "Diagnostic response value for cell maximum temperature";
CM_ SG_ 1304 DIAGRESP_CellMin_T "Diagnostic response value for cell minimum temperature";
CM_ SG_ 1304 DIAGRESP_CellAvg_T "Diagnostic response value for cell average temperature";
CM_ SG_ 1304 DIAGRESP_CSMMax_T "Diagnostic response value for CSM maximum temperature";
CM_ SG_ 1304 DIAGRESP_CSMMin_T "Diagnostic response value for CSM minimum temperature";
CM_ SG_ 1304 DIAGRESP_CSMAvg_T "Diagnostic response value for CSM average temperature";
CM_ SG_ 1304 DIAGRESP_FanDutyCycle "Diagnostic response for FAN duty cycle";
CM_ SG_ 1304 DIAGRESP_ModuleVtg "Diagnostic response value for Module Voltage";
CM_ SG_ 1304 DIAGRESP_ModuleRedundentVtg "Diagnostic response value for Module Redundant Voltage";
CM_ SG_ 1304 DIAGRESP_BusVtg "Diagnostic response value for Bus voltage";
CM_ SG_ 1304 DIAGRESP_BusRedundentVtg "Diagnostic response value for Redundant Bus voltage";
CM_ SG_ 1304 DIAGRESP_ChargerVtg "Diagnostic response value for Charger Voltage";
CM_ SG_ 1304 DIAGRESP_NDischargeEvents "The number of discharges that last longer than 30 seconds.";
CM_ SG_ 1304 DIAGRESP_NDeepDischargeEvents "The number of discharges to 20% of SOC or below";
CM_ SG_ 1304 DIAGRESP_NFullChargeEvents "Diagnostic response value for full charge events";
CM_ SG_ 1304 DIAGRESP_FanProportionalTimeOnSe "
Increment the counter by 1 every  100%/FAN_SPEED% Second.
For example:
At 100% speed the copunter gets incremented every 1 second.
At 50% speed the copunter gets incremented every 2 seconds.
At 25% speed the copunter gets incremented every 4 seconds.
";
CM_ SG_ 1304 DIAGRESP_Current "The number of charge events to 100% of SOC ";
CM_ SG_ 1312 DIAGCSTS_Cell1 "B7 (Reserved); B6 (Reserved); B5 (Reserved); B4 (Cell Open);B3 (Over voltage) ; B2 (Under voltage); B1(EOL); B0(Cell balancing)";
CM_ SG_ 1312 DIAGCSTS_Cell2 "B7 (Reserved); B6 (Reserved); B5 (Reserved); B4 (Cell Open);B3 (Over voltage) ; B2 (Under voltage); B1(EOL); B0(Cell balancing)";
CM_ SG_ 1312 DIAGCSTS_Cell3 "B7 (Reserved); B6 (Reserved); B5 (Reserved); B4 (Cell Open);
B3 (Over voltage) ; B2 (Under voltage); B1(EOL); B0(Cell balancing)";
CM_ SG_ 1312 DIAGCSTS_Cell4 "B7 (Reserved); B6 (Reserved); B5 (Reserved); B4 (Cell Open);B3 (Over voltage) ; B2 (Under voltage); B1(EOL); B0(Cell balancing)";
CM_ SG_ 1312 DIAGCSTS_Cell5 "B7 (Reserved); B6 (Reserved); B5 (Reserved); B4 (Cell Open);B3 (Over voltage) ; B2 (Under voltage); B1(EOL); B0(Cell balancing)";
CM_ SG_ 1312 DIAGCSTS_Cell6 "B7 (Reserved); B6 (Reserved); B5 (Reserved); B4 (Cell Open);B3 (Over voltage) ; B2 (Under voltage); B1(EOL); B0(Cell balancing)";
CM_ SG_ 1312 DIAGCSTS_Cell7 "B7 (Reserved); B6 (Reserved); B5 (Reserved); B4 (Cell Open);B3 (Over voltage) ; B2 (Under voltage); B1(EOL); B0(Cell balancing)";
CM_ SG_ 1312 DIAGCSTS_Cell8 "B7 (Reserved); B6 (Reserved); B5 (Reserved); B4 (Cell Open);
B3 (Over voltage) ; B2 (Under voltage); B1(EOL); B0(Cell balancing)";
CM_ SG_ 1312 DIAGCSTS_Cell9 "B7 (Reserved); B6 (Reserved); B5 (Reserved); B4 (Cell Open);B3 (Over voltage) ; B2 (Under voltage); B1(EOL); B0(Cell balancing)";
CM_ SG_ 1312 DIAGCSTS_Cell10 "B7 (Reserved); B6 (Reserved); B5 (Reserved); B4 (Cell Open);B3 (Over voltage) ; B2 (Under voltage); B1(EOL); B0(Cell balancing)";
CM_ SG_ 1312 DIAGCSTS_Cell11 "B7 (Reserved); B6 (Reserved); B5 (Reserved); B4 (Cell Open);B3 (Over voltage) ; B2 (Under voltage); B1(EOL); B0(Cell balancing)";
CM_ SG_ 1312 DIAGCSTS_Cell12 "B7 (Reserved); B6 (Reserved); B5 (Reserved); B4 (Cell Open);
B3 (Over voltage) ; B2 (Under voltage); B1(EOL); B0(Cell balancing)";
CM_ SG_ 1312 DIAGCSTS_Cell13 "B7 (Reserved); B6 (Reserved); B5 (Reserved); B4 (Cell Open);B3 (Over voltage) ; B2 (Under voltage); B1(EOL); B0(Cell balancing)";
CM_ SG_ 1312 DIAGCSTS_Cell14 "B7 (Reserved); B6 (Reserved); B5 (Reserved); B4 (Cell Open);B3 (Over voltage) ; B2 (Under voltage); B1(EOL); B0(Cell balancing)";
CM_ SG_ 1312 DIAGCSTS_Cell15 "B7 (Reserved); B6 (Reserved); B5 (Reserved); B4 (Cell Open);B3 (Over voltage) ; B2 (Under voltage); B1(EOL); B0(Cell balancing)";
CM_ SG_ 1312 DIAGCSTS_Cell16 "B7 (Reserved); B6 (Reserved); B5 (Reserved); B4 (Cell Open);B3 (Over voltage) ; B2 (Under voltage); B1(EOL); B0(Cell balancing)";
CM_ SG_ 1312 DIAGCSTS_Cell17 "B7 (Reserved); B6 (Reserved); B5 (Reserved); B4 (Cell Open);B3 (Over voltage) ; B2 (Under voltage); B1(EOL); B0(Cell balancing)";
CM_ SG_ 1312 DIAGCSTS_Cell18 "B7 (Reserved); B6 (Reserved); B5 (Reserved); B4 (Cell Open);
B3 (Over voltage) ; B2 (Under voltage); B1(EOL); B0(Cell balancing)";
CM_ SG_ 1312 DIAGCSTS_Cell19 "B7 (Reserved); B6 (Reserved); B5 (Reserved); B4 (Cell Open);
B3 (Over voltage) ; B2 (Under voltage); B1(EOL); B0(Cell balancing)";
CM_ SG_ 1312 DIAGCSTS_Cell20 "B7 (Reserved); B6 (Reserved); B5 (Reserved); B4 (Cell Open);
B3 (Over voltage) ; B2 (Under voltage); B1(EOL); B0(Cell balancing)";
CM_ SG_ 1312 DIAGCSTS_Cell21 "B7 (Reserved); B6 (Reserved); B5 (Reserved); B4 (Cell Open);
B3 (Over voltage) ; B2 (Under voltage); B1(EOL); B0(Cell balancing)";
CM_ SG_ 1312 DIAGCSTS_Cell22 "B7 (Reserved); B6 (Reserved); B5 (Reserved); B4 (Cell Open);
B3 (Over voltage) ; B2 (Under voltage); B1(EOL); B0(Cell balancing)";
CM_ SG_ 1312 DIAGCSTS_Cell23 "B7 (Reserved); B6 (Reserved); B5 (Reserved); B4 (Cell Open);
B3 (Over voltage) ; B2 (Under voltage); B1(EOL); B0(Cell balancing)";
CM_ SG_ 1312 DIAGCSTS_Cell24 "B7 (Reserved); B6 (Reserved); B5 (Reserved); B4 (Cell Open);
B3 (Over voltage) ; B2 (Under voltage); B1(EOL); B0(Cell balancing)";
CM_ SG_ 1312 DIAGCSTS_Cell25 "B7 (Reserved); B6 (Reserved); B5 (Reserved); B4 (Cell Open);
B3 (Over voltage) ; B2 (Under voltage); B1(EOL); B0(Cell balancing)";
CM_ SG_ 1312 DIAGCSTS_Cell26 "B7 (Reserved); B6 (Reserved); B5 (Reserved); B4 (Cell Open);
B3 (Over voltage) ; B2 (Under voltage); B1(EOL); B0(Cell balancing)";
CM_ SG_ 1312 DIAGCSTS_Cell27 "B7 (Reserved); B6 (Reserved); B5 (Reserved); B4 (Cell Open);
B3 (Over voltage) ; B2 (Under voltage); B1(EOL); B0(Cell balancing)";
CM_ SG_ 1312 DIAGCSTS_Cell28 "B7 (Reserved); B6 (Reserved); B5 (Reserved); B4 (Cell Open);
B3 (Over voltage) ; B2 (Under voltage); B1(EOL); B0(Cell balancing)";
CM_ SG_ 1312 DIAGCSTS_Cell29 "B7 (Reserved); B6 (Reserved); B5 (Reserved); B4 (Cell Open);
B3 (Over voltage) ; B2 (Under voltage); B1(EOL); B0(Cell balancing)";
CM_ SG_ 1312 DIAGCSTS_Cell30 "B7 (Reserved); B6 (Reserved); B5 (Reserved); B4 (Cell Open);
B3 (Over voltage) ; B2 (Under voltage); B1(EOL); B0(Cell balancing)";
CM_ SG_ 1312 DIAGCSTS_Cell31 "B7 (Reserved); B6 (Reserved); B5 (Reserved); B4 (Cell Open);
B3 (Over voltage) ; B2 (Under voltage); B1(EOL); B0(Cell balancing)";
CM_ SG_ 1312 DIAGCSTS_Cell32 "B7 (Reserved); B6 (Reserved); B5 (Reserved); B4 (Cell Open);
B3 (Over voltage) ; B2 (Under voltage); B1(EOL); B0(Cell balancing)";
CM_ SG_ 1312 DIAGCSTS_Cell33 "B7 (Reserved); B6 (Reserved); B5 (Reserved); B4 (Cell Open);
B3 (Over voltage) ; B2 (Under voltage); B1(EOL); B0(Cell balancing)";
CM_ SG_ 1312 DIAGCSTS_Cell34 "B7 (Reserved); B6 (Reserved); B5 (Reserved); B4 (Cell Open);
B3 (Over voltage) ; B2 (Under voltage); B1(EOL); B0(Cell balancing)";
CM_ SG_ 1312 DIAGCSTS_Cell35 "B7 (Reserved); B6 (Reserved); B5 (Reserved); B4 (Cell Open);
B3 (Over voltage) ; B2 (Under voltage); B1(EOL); B0(Cell balancing)";
CM_ SG_ 1312 DIAGCSTS_Cell36 "B7 (Reserved); B6 (Reserved); B5 (Reserved); B4 (Cell Open);
B3 (Over voltage) ; B2 (Under voltage); B1(EOL); B0(Cell balancing)";
CM_ SG_ 1312 DIAGCSTS_Cell37 "B7 (Reserved); B6 (Reserved); B5 (Reserved); B4 (Cell Open);
B3 (Over voltage) ; B2 (Under voltage); B1(EOL); B0(Cell balancing)";
CM_ SG_ 1312 DIAGCSTS_Cell38 "B7 (Reserved); B6 (Reserved); B5 (Reserved); B4 (Cell Open);
B3 (Over voltage) ; B2 (Under voltage); B1(EOL); B0(Cell balancing)";
CM_ SG_ 1312 DIAGCSTS_Cell39 "B7 (Reserved); B6 (Reserved); B5 (Reserved); B4 (Cell Open);
B3 (Over voltage) ; B2 (Under voltage); B1(EOL); B0(Cell balancing)";
CM_ SG_ 1312 DIAGCSTS_Cell40 "B7 (Reserved); B6 (Reserved); B5 (Reserved); B4 (Cell Open);
B3 (Over voltage) ; B2 (Under voltage); B1(EOL); B0(Cell balancing)";
CM_ SG_ 1312 DIAGCSTS_Cell41 "B7 (Reserved); B6 (Reserved); B5 (Reserved); B4 (Cell Open);B3 (Over voltage) ; B2 (Under voltage); B1(EOL); B0(Cell balancing)";
CM_ SG_ 1312 DIAGCSTS_Cell42 "B7 (Reserved); B6 (Reserved); B5 (Reserved); B4 (Cell Open);
B3 (Over voltage) ; B2 (Under voltage); B1(EOL); B0(Cell balancing)";
CM_ SG_ 1312 DIAGCSTS_Cell43 "B7 (Reserved); B6 (Reserved); B5 (Reserved); B4 (Cell Open);
B3 (Over voltage) ; B2 (Under voltage); B1(EOL); B0(Cell balancing)";
CM_ SG_ 1312 DIAGCSTS_Cell44 "B7 (Reserved); B6 (Reserved); B5 (Reserved); B4 (Cell Open);
B3 (Over voltage) ; B2 (Under voltage); B1(EOL); B0(Cell balancing)";
CM_ SG_ 1312 DIAGCSTS_Cell45 "B7 (Reserved); B6 (Reserved); B5 (Reserved); B4 (Cell Open);
B3 (Over voltage) ; B2 (Under voltage); B1(EOL); B0(Cell balancing)";
CM_ SG_ 1312 DIAGCSTS_Cell46 "B7 (Reserved); B6 (Reserved); B5 (Reserved); B4 (Cell Open);
B3 (Over voltage) ; B2 (Under voltage); B1(EOL); B0(Cell balancing)";
CM_ SG_ 1312 DIAGCSTS_Cell47 "B7 (Reserved); B6 (Reserved); B5 (Reserved); B4 (Cell Open);
B3 (Over voltage) ; B2 (Under voltage); B1(EOL); B0(Cell balancing)";
CM_ SG_ 1312 DIAGCSTS_Cell48 "B7 (Reserved); B6 (Reserved); B5 (Reserved); B4 (Cell Open);
B3 (Over voltage) ; B2 (Under voltage); B1(EOL); B0(Cell balancing)";
CM_ SG_ 1312 DIAGCSTS_Cell49 "B7 (Reserved); B6 (Reserved); B5 (Reserved); B4 (Cell Open);
B3 (Over voltage) ; B2 (Under voltage); B1(EOL); B0(Cell balancing)";
CM_ SG_ 1312 DIAGCSTS_Cell50 "B7 (Reserved); B6 (Reserved); B5 (Reserved); B4 (Cell Open);
B3 (Over voltage) ; B2 (Under voltage); B1(EOL); B0(Cell balancing)";
CM_ BO_ 1320 "Diagnostics related to version information";
CM_ SG_ 1320 DIAGVERINFO_ProtocolVersion "Available Protocol version";
CM_ SG_ 1320 DIAGVERINFO_SoftwareVersionMajor "Availabe software/firmware major version in serial flash # (major.minor.build)";
CM_ SG_ 1320 DIAGVERINFO_SoftwareVersionMinor "Availabe software/firmware minor version in serial flash # (major.minor.build)";
CM_ SG_ 1320 DIAGVERINFO_SoftwareVersionBuild "Availabe software/firmware build version in serial flash # (major.minor.build)";
CM_ SG_ 1320 DIAGVERINFO_InServiceDate "starting from 2000/01/01";
CM_ SG_ 1320 DIAGVERINFO_AttachedUPSSKU "Available UPS SKU (Serial number) information";
CM_ SG_ 1320 DIAGVERINFO_ManufactureYear "Year of manufacturing : RTC time+ 2000";
CM_ SG_ 1320 DIAGVERINFO_ManufactureDay "Day of the year of manufacturing";
CM_ SG_ 1320 DIAGVERINFO_ManufactureSerial "Serial number allocated";
CM_ SG_ 1320 DIAGVERINFO_ManufactureDate "starting from 2000/01/01";
CM_ SG_ 1320 DIAGVERINFO_SerialNumber1 "Serial number 1 allocated";
CM_ SG_ 1320 DIAGVERINFO_SerialNumber2 "Serial number2 allocated";
CM_ SG_ 1320 DIAGVERINFO_SerialNumber3 "Serial number3 allocated";
CM_ SG_ 1320 DIAGVERINFO_PartNumber1 "Part number1 allocated";
CM_ SG_ 1320 DIAGVERINFO_PartNumber2 "Part number2 allocated";
CM_ SG_ 1320 DIAGVERINFO_PartNumber3 "Part number3 allocated";
CM_ SG_ 1320 DIAGVERINFO_SeriesConfiguration "56S2P = 56";
CM_ SG_ 1320 DIAGVERINFO_ParallelConfiguratio "50S2P = 2";
CM_ SG_ 1320 DIAGVERINFO_DesignCapacity "No value : 4095";
CM_ SG_ 1320 DIAGVERINFO_DesignVoltage "No value : 511";
CM_ SG_ 1320 DIAGVERINFO_DesignPower "No value : 65535";
CM_ SG_ 1320 DIAGVERINFO_SoftwareAvailableMaj "Availabe software/firmware major available version in serial flash # (major.minor.build)";
CM_ SG_ 1320 DIAGVERINFO_SoftwareAvailableMin "Availabe software/firmware available minor version in serial flash # (major.minor.build)";
CM_ SG_ 1320 DIAGVERINFO_SoftwareAvailableBui "Availabe software/firmware build available version in serial flash # (major.minor.build)";
CM_ SG_ 1320 DIAGVERINFO_BmFileTransferInIdle "Status of Battery management file transfer is Idle mode";
CM_ SG_ 1320 DIAGVERINFO_BmFileTransferInProg "Status of Battery management file transfer is Progress mode";
CM_ SG_ 1320 DIAGVERINFO_BmFileTransferInveri "Status of Battery management file transfer is Verify mode";
CM_ SG_ 1320 DIAGVERINFO_BmFileTraReadyInstal "Status of Battery management file transfer is Ready mode";
CM_ SG_ 1320 DIAGVERINFO_BLVersionMajor "Availabe bootloader major version in serial flash # (major.minor.build)";
CM_ SG_ 1320 DIAGVERINFO_BLVersionMinor "Availabe bootloader minor version in serial flash # (major.minor.build)";
CM_ SG_ 1320 DIAGVERINFO_BLVersionBuild "Availabe bootloader build version in serial flash # (major.minor.build)";
CM_ SG_ 227 SessionReq_Mux "Rolling counter used to correlate responses with requests (see *_ResponseID)";
CM_ SG_ 227 SessionReq_RequestID "Rolling counter used to correlate responses with requests (see *_ResponseID)";
CM_ SG_ 227 SessionReq_TargetNode "For 0xFF for all nodes else specifies a single node number";
CM_ SG_ 1336 SessionResp_ResponseErrorType "0x00 : Vendor verifed
0x01 : Vendor invalid
0x02 : Key verfied
0x03  : Key invalid
0x04 : Session started
0x05  Session in progress
0x06 : Session end 
0xff : Sesssion timeout";
CM_ SG_ 1336 SessionResp_ResponseParameter "1 : Provide seedkey
2 : Provide session ID";
CM_ BO_ 1296 "Cell level diagnostics value for AFE";
CM_ SG_ 1296 DIAGAFE_ResponseID "Rolling counter used to correlate responses with requests (see *_ResponseID)";
CM_ SG_ 1296 DIAGAFE_AFE1_Cell0 "AFE1 cell  0 voltage";
CM_ SG_ 1296 DIAGAFE_AFE1_Cell1 "AFE1 cell 1 voltage";
CM_ SG_ 1296 DIAGAFE_AFE1_Cell2 "AFE 1 cell 2 voltage";
CM_ SG_ 1296 DIAGAFE_AFE1_Cell3 "AFE 1 cell 3 voltage";
CM_ SG_ 1296 DIAGAFE_AFE1_Cell4 "AFE1 cell 4 voltage";
CM_ SG_ 1296 DIAGAFE_AFE1_Cell5 "AFE1 cell 5 voltage";
CM_ SG_ 1296 DIAGAFE_AFE1_Cell6 "AFE1 cell 6 voltage ";
CM_ SG_ 1296 DIAGAFE_AFE1_Cell7 "AFE1 cell 7 voltage";
CM_ SG_ 1296 DIAGAFE_AFE1_Cell8 "AFE1 cell 8 voltage";
CM_ SG_ 1296 DIAGAFE_AFE1_Cell9 "AFE1 cell 9 voltage";
CM_ SG_ 1296 DIAGAFE_AFE1_Cell10 "AFE1 cell 10 voltage";
CM_ SG_ 1296 DIAGAFE_AFE1_Cell11 "AFE1 cell 11 voltage";
CM_ SG_ 1296 DIAGAFE_AFE1_Cell12 "AFE1 cell 12 voltage";
CM_ SG_ 1296 DIAGAFE_AFE1_Cell13 "AFE1 cell 13 voltage";
CM_ SG_ 1296 DIAGAFE_AFE2_Cell0 "AFE2 cell 0 voltage";
CM_ SG_ 1296 DIAGAFE_AFE2_Cell1 "AFE2 cell 1 voltage ";
CM_ SG_ 1296 DIAGAFE_AFE2_Cell2 "AFE 2 cell 2 voltage";
CM_ SG_ 1296 DIAGAFE_AFE2_Cell3 "AFE2 cell 3 voltage";
CM_ SG_ 1296 DIAGAFE_AFE2_Cell4 "AFE 2 cell 4 voltage";
CM_ SG_ 1296 DIAGAFE_AFE2_Cell5 "AFE2 cell 5 voltage";
CM_ SG_ 1296 DIAGAFE_AFE2_Cell6 "AFE2 cell 6 voltage";
CM_ SG_ 1296 DIAGAFE_AFE2_Cell7 "AFE2 cell 7 voltage";
CM_ SG_ 1296 DIAGAFE_AFE2_Cell8 "AFE2 cell 8 voltage";
CM_ SG_ 1296 DIAGAFE_AFE2_Cell9 "AFE2 cell 9 voltage";
CM_ SG_ 1296 DIAGAFE_AFE2_Cell10 "AFE2 cell 10 voltage";
CM_ SG_ 1296 DIAGAFE_AFE2_Cell11 "AFE2 cell 11 voltage";
CM_ SG_ 1296 DIAGAFE_AFE2_Cell12 "AFE2 cell 12 voltage";
CM_ SG_ 1296 DIAGAFE_AFE2_Cell13 "AFE2 cell 13 voltage";
CM_ SG_ 1296 DIAGAFE_AFE3_Cell0 "AFE3 cell 0 voltage";
CM_ SG_ 1296 DIAGAFE_AFE3_Cell1 "AFE3 cell 1 voltage";
CM_ SG_ 1296 DIAGAFE_AFE3_Cell2 "AFE3 cell 2 voltage";
CM_ SG_ 1296 DIAGAFE_AFE3_Cell3 "AFE3 cell 3 voltage";
CM_ SG_ 1296 DIAGAFE_AFE3_Cell4 "AFE3 cell 4 voltage";
CM_ SG_ 1296 DIAGAFE_AFE3_Cell5 "AFE3 cell 5 voltage";
CM_ SG_ 1296 DIAGAFE_AFE3_Cell6 "AFE3 cell 6 voltage";
CM_ SG_ 1296 DIAGAFE_AFE3_Cell7 "AFE3 cell 7 voltage";
CM_ SG_ 1296 DIAGAFE_AFE3_Cell8 "AFE3 cell 8 voltage";
CM_ SG_ 1296 DIAGAFE_AFE3_Cell9 "AFE3 cell 9 voltage";
CM_ SG_ 1296 DIAGAFE_AFE3_Cell10 "AFE3 cell 10 voltage";
CM_ SG_ 1296 DIAGAFE_AFE3_Cell11 "AFE3 cell 11 voltage";
CM_ SG_ 1296 DIAGAFE_AFE3_Cell12 "AFE3 cell 12 voltage";
CM_ SG_ 1296 DIAGAFE_AFE3_Cell13 "AFE3 cell 13 voltage";
CM_ SG_ 1296 DIAGAFE_AFE4_Cell0 "AFE4 cell 0 voltage";
CM_ SG_ 1296 DIAGAFE_AFE4_Cell1 "AFE4 cell 1 voltage";
CM_ SG_ 1296 DIAGAFE_AFE4_Cell2 "AFE4 cell 2 voltage";
CM_ SG_ 1296 DIAGAFE_AFE4_Cell3 "AFE4 cell 3 voltage";
CM_ SG_ 1296 DIAGAFE_AFE4_Cell4 "AFE4 cell 4 voltage";
CM_ SG_ 1296 DIAGAFE_AFE4_Cell5 "AFE4 cell 5 voltage";
CM_ SG_ 1296 DIAGAFE_AFE4_Cell6 "AFE4 cell 6 voltage";
CM_ SG_ 1296 DIAGAFE_AFE4_Cell7 "AFE4 cell 7 voltage";
CM_ SG_ 1296 DIAGAFE_AFE4_Cell8 "AFE4 cell 8 voltage";
CM_ SG_ 1296 DIAGAFE_AFE4_Cell9 "AFE4 cell 9 voltage";
CM_ SG_ 1296 DIAGAFE_AFE4_Cell10 "AFE4 cell 10 voltage";
CM_ SG_ 1296 DIAGAFE_AFE4_Cell11 "AFE4 cell 11 voltage";
CM_ SG_ 1296 DIAGAFE_AFE4_Cell12 "AFE4 cell 12 voltage";
CM_ SG_ 1296 DIAGAFE_AFE4_Cell13 "AFE4 cell 13 voltage";
CM_ BO_ 226 "Read out the log in the serial flash for 64 byte data.";
CM_ SG_ 226 EvntLog_All_Rq_RequestID "Rolling counter used to correlate responses with requests (see *_ResponseID)";
CM_ SG_ 226 EvntLog_All_Rq_RequestType "Specify which type of response message should be sent back";
CM_ SG_ 226 EvntLog_All_SinceLastTimeToReadO "0xFFFFFFFF is a SPECIAL number to erase all logs dependent on the Erase type of RequestType. 0x7FFFFFFF is the maximum value for Recent seconds or Erase counts.

For example, 
258 means 258 seconds dependent on the type Recent of RequestType. Or
368 means to adjust the index to deduct 368 logs dependent on the type Erase of RequestType. This request can change the index instead of physical deletion. 
";
CM_ BO_ 1352 "Response to Battery all fault and status information request.                                                                 1: BattInf_StsInfo_Resp(0x548) ";
CM_ SG_ 1352 SVCDISC "Service disconnect switch  ; 0: Service disconnect switch open                                 1: Service disconnect switch close";
CM_ SG_ 1352 LPSONCMD "LPS ON Command                                                       ";
CM_ SG_ 1352 ONBUTPRS "On button press                                                          0: On button press open                                                1: On button press close";
CM_ SG_ 1352 PC1_MCU_Wakeup "AND of Mech Interlock, REMoff signal
1: AND both are ON
0: anyone is Off.";
CM_ SG_ 1352 MECHILSW "Mechanical interlock switch                                                  0: Mechanical interlock switch open                            1: Mechanical interlock switch close";
CM_ SG_ 1352 RTC_CONFIG_NOTDONE "RTC configuration fault                                          0: RTC configured                                                                1: RTC not configured";
CM_ SG_ 1352 NVM_WRRETRYF "NVM_Write Retry fault                                                     0: NVM Write Fault not present.                                                               1: NVM Write Fault not present";
CM_ SG_ 1352 Permanent_Failure_Present "Check for any permanent failure                                       0: No permanent failure                                                      1: Permanent failure";
CM_ SG_ 1352 SOFTSTART_STS "Soft start status                                                               0: No Soft start status                                                 1: Soft start status present";
CM_ SG_ 1352 GPIO_PF1_OCCFLT "GPIO Fault pin-1 for Over charge current                                                       0:  No Fault on GPIO Fault pin-1 for Over charge current                                                               1: Fault present on GPIO Fault pin-1 for Over charge current  ";
CM_ SG_ 1352 GPIO_PF0_ODCFLT "GPIO Fault pin-0 for Over discharge current                                                       0:  No Fault on GPIO Fault pin-0 for Over discharge current                                                              1: Fault present on GPIO Fault pin-0 for Over discharge current   ";
CM_ SG_ 1352 GPIO_PG0_CELLOTAFLT "GPIO Port G pin 0 for Cell over temperature alert failure                                                                                0: No fault present on GPIO Port G pin 0 for Cell over temperature alert failure                                          1: Fault present on GPIO Port G pin 0 for Cell over temperature alert failure";
CM_ SG_ 1352 VBAT_UV_ALERTFLT "Battery under voltage alert fault                                            0: No Battery under voltage alert fault                                            1: Battery under voltage alert fault";
CM_ SG_ 1352 VBAT_OV_ALERT "Battery over voltage alert fault                                                0: No Battery over voltage alert fault                              1: Battery over voltage alert fault present";
CM_ SG_ 1352 HTO_LN_STS "HTO line status                                                            0: No fault for HTO line status                                               1: Fault for HTO line status";
CM_ SG_ 1352 AFEFLTPIN_STS "AFE fault status on AFE fault pin                                         0: AFE Fault pin no fault present                                        1: AFE Fault pin Fault present";
CM_ SG_ 1352 AFE_DSALE_STS "AFE disable status info                                                            0: AFE enable                                                                  1: AFE enable";
CM_ SG_ 1352 CELL_OT_ALERT "Cell over temperature alert                                           0: No Cell over temperature alert                                      1: Cell over temperature alert";
CM_ SG_ 1352 SFlash_Integrity_STS "0:Integrity check failed
1:Integrity check passed";
CM_ BO_ 228 "Battery all fault and status information request.                                                                0: BattInf_Fault_Resp(0x540)                                                                                                    1: BattInf_StsInfo_Resp(0x548) ";
CM_ SG_ 228 BattInf_Rq_RequestType "Battery all fault and status information request.                                                                0: BattInf_Fault_Resp(0x540)                                                                                                    1: BattInf_StsInfo_Resp(0x548) ";
CM_ BO_ 1360 "Response values for Battery GetAddnlInfo values request.      ";
CM_ SG_ 1360 Batt_AddnlInfo_Resp_CFETTemp "Temperature sensor for measuring CFET temperature";
CM_ SG_ 1360 Batt_AddnlInfo_Resp_DFETTemp "Temperature sensor for measuring DFET temperature";
CM_ SG_ 1360 Batt_AddnlInfo_Resp_TFETTemp "Temperature sensor for measuring trickle charge FET temperature";
CM_ SG_ 1360 Batt_AddnlInfo_Resp_SHTTemp "Shunt temperature";
CM_ SG_ 1360 Batt_AddnlInfo_Rsp_RedCellTempMC "Temperature sensor for measuring redundant cell temperature";
CM_ SG_ 1360 Batt_AddnlInfo_Resp_CELLTemp_1 "Temperature sensor for measuring first cell NTC";
CM_ SG_ 1360 Batt_AddnlInfo_Resp_CELLTemp_2 "Temperature sensor for measuring second cell NTC.";
CM_ SG_ 1360 Batt_AddnlInfo_Resp_CELLTemp_3 "Temperature sensor for measuring third cell NTC.";
CM_ SG_ 1360 Batt_AddnlInfo_Resp_CELLTemp_4 "Temperature sensor for measuring fourth cell NTC.";
CM_ SG_ 1360 Batt_AddnlInfo_Resp_CELLTemp_5 "Temperature sensor for measuring fifth cell NTC.";
CM_ SG_ 1360 Batt_AddnlInfo_Resp_CELLTemp_6 "Temperature sensor for measuring sixth cell NTC.";
CM_ SG_ 1360 Batt_AddnlInfo_Resp_CELLTemp_7 "Temperature sensor for measuring seventh cell NTC.";
CM_ SG_ 1360 Batt_AddnlInfo_Resp_CELLTemp_8 "Temperature sensor for measuring eighth cell NTC.";
CM_ SG_ 1360 Batt_AddnlInfo_Resp_CELLTemp_9 "Temperature sensor for measuring nineth cell NTC.";
CM_ SG_ 1360 Batt_AddnlInfo_Resp_CELLTemp_10 "Temperature sensor for measuring tenth cell NTC.";
CM_ SG_ 1360 Batt_AddnlInfo_Resp_CELLTemp_11 "Temperature sensor for measuring eleventh cell NTC.";
CM_ SG_ 1360 Batt_AddnlInfo_Resp_CELLTemp_12 "Temperature sensor for measuring twelveth cell NTC.";
CM_ SG_ 1360 Batt_AddnlInfo_Resp_CELLTemp_13 "Temperature sensor for measuring thirteenth cell NTC.";
CM_ SG_ 1360 Batt_AddnlInfo_Resp_CELLTemp_14 "Temperature sensor for measuring fourteenth cell NTC.";
CM_ SG_ 1360 Batt_AddnlInfo_Resp_CELLTemp_15 "Temperature sensor for measuring fifteenth cell NTC.";
CM_ SG_ 1360 Batt_AddnlInfo_Resp_CELLTemp_16 "Temperature sensor for measuring sixteenth cell NTC.";
CM_ SG_ 1360 Batt_AddnlInfo_Resp_CELLTemp_17 "Temperature sensor for measuring seventeenth cell NTC.";
CM_ SG_ 1360 Batt_AddnlInfo_Resp_CELLTemp_18 "Temperature sensor for measuring eighteenth cell NTC.";
CM_ SG_ 1360 Batt_AddnlInfo_Resp_CSM_AFE1S1 "Temperature sensor for sensor 1 of AFE 1";
CM_ SG_ 1360 Batt_AddnlInfo_Resp_CSM_AFE1S2 "Temperature sensor for sensor 2 of AFE 1";
CM_ SG_ 1360 Batt_AddnlInfo_Resp_CSM_AFE2S1 "Temperature sensor for sensor 1 of AFE 2";
CM_ SG_ 1360 Batt_AddnlInfo_Resp_CSM_AFE2S2 "Temperature sensor for sensor 2 of AFE 2";
CM_ SG_ 1360 Batt_AddnlInfo_Resp_CSM_AFE3S1 "Temperature sensor for sensor 1 of AFE 3";
CM_ SG_ 1360 Batt_AddnlInfo_Resp_CSM_AFE3S2 "Temperature sensor for sensor 2 of AFE 3";
CM_ SG_ 1360 Batt_AddnlInfo_Resp_CSM_AFE4S1 "Temperature sensor for sensor 1 of AFE 4";
CM_ SG_ 1360 Batt_AddnlInfo_Resp_CSM_AFE4S2 "Temperature sensor for sensor 2 of AFE 4";
CM_ BO_ 1344 "Response to Battery all fault and status information request.                                                                0: BattInf_Fault_Resp(0x540)                                                                                                    ";
CM_ SG_ 1344 CELL_OV_L1 "Cell over voltage protection fault layer 1 monitoring";
CM_ SG_ 1344 CELL_OV_L2 "Cell over voltage protection fault layer 1 monitoring";
CM_ SG_ 1344 CELL_OV_L3 "Cell over voltage protection fault layer 2_safety software monitoring";
CM_ SG_ 1344 CELL_UV_L1 "Cell under voltage protection fault layer 1 monitoring";
CM_ SG_ 1344 CELL_UV_L2 "Cell under voltage protection fault layer 1_safety software monitoring";
CM_ SG_ 1344 CELL_UV_L3 "Cell over voltage protection fault layer 2_safety software monitoring";
CM_ SG_ 1344 PACK_OV_L1 "Pack over voltage fault  layer 1 monitoring";
CM_ SG_ 1344 PACK_OV_L2 "Pack over voltage protection fault layer 1_safety software monitoring";
CM_ SG_ 1344 PACK_OV_L4 "Pack over voltage protection fault layer 3_Hardware monitoring";
CM_ SG_ 1344 PACK_UV_L1 "Pack under voltage protection fault layer 1 monitoring";
CM_ SG_ 1344 PACK_UV_L2 "Pack under voltage protection fault layer 2_ safety software monitoring";
CM_ SG_ 1344 PACK_UV_L4 "Pack under voltage protection fault layer 4_Hardware monitoring";
CM_ SG_ 1344 ODCP_L1 "Battery pack Discharging Over load and Short circuit  protections layer 1 application software monitoring";
CM_ SG_ 1344 ODCP_L2 "Battery pack Discharging Over load and Short circuit  protections layer 2 safety software monitoring";
CM_ SG_ 1344 ODCP_L4 "Battery pack Discharging Over load and Short circuit  protections layer 4 hardware monitoring";
CM_ SG_ 1344 OCCP_L1 "Battery pack Charging Overcurrent protection layer 1_Application software monitoring";
CM_ SG_ 1344 OCCP_L2 "Battery pack Charging Overcurrent protection layer 2_Safety software monitoring";
CM_ SG_ 1344 OCCP_L4 "Battery pack Charging Overcurrent protection layer 4_hardware  monitoring";
CM_ SG_ 1344 CHG_OT_L1 "Cell Over temperature protection during 
charging layer 1_application software monitoring";
CM_ SG_ 1344 CHG_OT_L2 "Cell Over temperature protection during 
charging layer 2_safety software monitoring";
CM_ SG_ 1344 CHG_OT_L3 "Cell Over temperature protection during 
charging layer 2_safety software monitoring";
CM_ SG_ 1344 CHG_OT_L4 "Cell Over temperature protection during 
charging layer 4_hardware monitoring";
CM_ SG_ 1344 CHG_OT_TC_L1 "Cell Over temperature protection during 
trickle charging layer 1_application software monitoring";
CM_ SG_ 1344 DCHG_OT_L1 "Cell Over temperature protection during discharging layer 1_application software monitoring";
CM_ SG_ 1344 DCHG_OT_L2 "Cell Over temperature protection during discharging layer 2_safety software monitoring";
CM_ SG_ 1344 DCHG_OT_L3 "Cell Over temperature protection during discharging layer 3 permanent fault monitoring";
CM_ SG_ 1344 DCHG_OT_L4 "Cell Over temperature protection during discharging layer 4  hardware monitoring";
CM_ SG_ 1344 CHG_UT_L1 "Cell Under temperature protection during charging layer 1_application software monitoring";
CM_ SG_ 1344 CHG_UT_L2 "Cell Under temperature protection during charging layer 2_safety software monitoring";
CM_ SG_ 1344 DCHG_UT_L2 "Cell Under temperature protection during discharging layer 2_safety software monitoring";
CM_ SG_ 1344 CHG_UT_TC_L1 "Cell Under temperature protection during trickle charging layer 1_application software monitoing";
CM_ SG_ 1344 CHG_UT_L3 "Cell Under temperature protection during charging layer 3_permanent fault monitoring";
CM_ SG_ 1344 DCHG_UT_L3 "Cell Under temperature protection during discharging layer 3_permanent fault monitoring";
CM_ SG_ 1344 MOSFET_OT_L1 "MOSFET Over temperature protection ( Charge & Discharge) layer 1_application software monitoring";
CM_ SG_ 1344 MOSFET_OT_L2 "MOSFET Over temperature protection ( Charge & Discharge) layer 2_safety software monitoring";
CM_ SG_ 1344 SHUNT_OT_L1 "Shunt resistor Over temperature protection during charging / discharging layer 1_application software monitoring";
CM_ SG_ 1344 SHUNT_OT_L2 "Shunt resistor Over temperature protection during charging / discharging layer 2_safety software monitoring";
CM_ SG_ 1344 CSM_OT_L1 "CSM PCB / AFE Over temperature protection during charging / discharging/ cell balancing layer 1_application software monitoring";
CM_ SG_ 1344 CSM_OT_L2 "CSM PCB / AFE Over temperature protection during charging / discharging/ cell balancing layer 2_safety software monitoring";
CM_ SG_ 1344 CSM_OT_L3 "CSM PCB / AFE Over temperature protection during charging / discharging/ cell balancing layer 3_permanent fault monitoring";
CM_ SG_ 1344 TC_OT_L1 "Trickle charger temperature fault layer 1_application software monitoring";
CM_ SG_ 1344 DCHG_UT_L1 "Cell Under temperature protection during discharging layer 1_application software monitoring";
CM_ SG_ 1344 CELL_UNBAL_L1 "Cell imbalance  fault layer 1_application software monitoring";
CM_ SG_ 1344 CELL_UNBAL_L2 "Cell imbalance  fault layer 2_safety  software monitoring";
CM_ SG_ 1344 SFTYAPP_FLT_L2 "Safety Application failure layer 2_safety software monitoring";
CM_ SG_ 1344 SM_MCU_INIT_FAIL_L2 "Safety MCU (Start up) failure layer 2_safety software monitoring";
CM_ SG_ 1344 SM_MCU_RUN_FAIL_L2 "Safety MCU (Run Time) failure layer 2_safety software monitoring";
CM_ SG_ 1344 SM_AFE_INIT_FAIL_L2 "Safety AFE (Start Up) failure layer 2_safety software monitoring ";
CM_ SG_ 1344 SM_AFE_RUN_FAIL_L2 "Safety AFE (Run Time) failure layer 2_safety software monitoring";
CM_ SG_ 1344 NTC_OPEN_FLT_L1 "Thermistor open permanent failure layer 1_application software monitoring";
CM_ SG_ 1344 NTC_SHORT_FLT_L1 "Thermistor short permanent failure layer 1_application software monitoring";
CM_ SG_ 1344 FUSE_OPEN_FLT_L1 "Fuse open permanent failure layer 1_application software monitoring";
CM_ SG_ 1344 CFET_SHORT_FLT_L1 "CFET permanent failure layer 1_application software monitoring";
CM_ SG_ 1344 MCU_INIT_FAIL_L1 "MCU initialization failure layer 1_application software monitoring";
CM_ SG_ 1344 DFET_SHORT_FLT_L1 "DFET permanent failure layer 1_application software monitoring";
CM_ SG_ 1344 OCCP_TC_FLT_L1 "Trickle charge over current permanent failure layer 1_application software monitoring";
CM_ SG_ 1344 CAN_COMM_LOSS_L1 "CAN communication failure layer 1_application software monitoring";
CM_ SG_ 1344 FAN_FLT_L1 "Fan failure layer 1_application software monitoring";
CM_ SG_ 1344 CELL_DD_L1 "Cell deep discharge protection Level 1";
CM_ SG_ 1344 PACK_EOC_L1 "Pack End of Charge Level 1";
CM_ SG_ 1344 ENERGY_CHG_L1 "Energy Charge Cutoff";
CM_ SG_ 1344 ENERGY_DCHG_L1 "Energy Discharge Cutoff";
CM_ BO_ 1328 "Response to EventLog_All_Rq request by reading out the log in the serial flash for 64 byte data.";
CM_ SG_ 1328 EvntLog_ID "Event Fault/Release ID";
CM_ SG_ 1328 EvntLog_Before_state "The state of BMS at the time of event logging
BattStm_BattOpState_INIT\t  
BattStm_BattOpState_STANDBY\t
BattStm_OpState_DISCHARGE_READY
BattStm_OpState_DISCH_TC_ON\t
BattStm_OpState_CHARGE_READY    
BattStm_OpState_CHARGE_DISHCARGE
BattStm_OpState_ONBOARD_CHARGE
BattStm_OpState_AUTOCHARGE\t  
BattStm_OpState_REDUCED_CHARGE  
BattStm_BattOpState_FAULT\t
BattStm_BattOpState_SLEEP     ";
CM_ SG_ 1328 EvntLog_After_state "The state of BMS after event logging
BattStm_BattOpState_INIT\t  
BattStm_BattOpState_STANDBY\t
BattStm_OpState_DISCHARGE_READY
BattStm_OpState_DISCH_TC_ON\t
BattStm_OpState_CHARGE_READY    
BattStm_OpState_CHARGE_DISHCARGE
BattStm_OpState_ONBOARD_CHARGE
BattStm_OpState_AUTOCHARGE\t  
BattStm_OpState_REDUCED_CHARGE  
BattStm_BattOpState_FAULT\t
BattStm_BattOpState_SLEEP     ";
CM_ SG_ 1328 EvntLog_FET_state_Reserved "CFET, DFET, Trickle Charge FET
Reserved\tbit 7
Trickle\tbit 6
CFET\tbit 5
DFET\tbit 4
";
CM_ SG_ 1328 EvntLog_Vbat "Battery voltage: Measured before the FET.";
CM_ SG_ 1328 EvntLog_Vbus "Bus voltage:  Measured after the FET.";
CM_ SG_ 1328 EvntLog_Vmax_cell "Max cell voltage";
CM_ SG_ 1328 EvntLog_Vavg_cell "Average cell voltage";
CM_ SG_ 1328 EvntLog_Vmin_cell "Minimum cell voltage";
CM_ SG_ 1328 EvntLog_Ibatt_Before "
Battery current at the time of event logging
";
CM_ SG_ 1328 EvntLog_SOH "
Battery state of health

";
CM_ SG_ 1328 EvntLog_RSOC "
Battery state of capacity

";
CM_ SG_ 1328 EvntLog_Full_Charge_Capacity "
battery capcacity at full charge
";
CM_ SG_ 1328 EvntLog_Avg_Temp "
Average Cell Temperature: Offset -40
";
CM_ SG_ 1328 EvntLog_FET_Temp "
FET Temperature: DFET Temperature: Offset -40
";
CM_ SG_ 1328 EvntLog_Cell_Max_Temp "
Max Cell Temperature: Offset -40

";
CM_ SG_ 1328 EvntLog_Cell_Min_Temp "
Min Cell Temperature: Offset -40
";
CM_ SG_ 1328 EvntLog_Max_Cell_Temp_Index "
The Cell Index where max temp is recorded at the time of Event logging: Index should be first occurred index(incase of multiple)
";
CM_ SG_ 1328 EvntLog_Min_Cell_Temp_Index "
The Cell Index where min temp is recorded at the time of Event logging: Index should be first occurred index(incase of multiple)

";
CM_ SG_ 1328 EvntLog_Max_Cell_Volt_Index "
The Cell Index where max voltage is recorded at the time of Event logging: Index should be first occurred index(incase of multiple)

";
CM_ SG_ 1328 EvntLog_Min_Cell_Volt_Index "
The Cell Index where min voltage is recorded at the time of Event logging: Index should be first occurred index(incase of multiple)
";
CM_ SG_ 1328 EvntLog_BMS_Opmode "
BP is in following modes
bit7 & bit6: 01 Production/EOL mode(This bit set when A2A1A0 are 000)
bit7 & bit6:11 Autocharge mode(This bit set when A2A1A0 are 111)
bit7 & bit6: 10 UPS Application mode(This bit set when A2A1A0 are 001 to 110):
bit7 & bit6: 00 Reserved for future use.
";
CM_ SG_ 1328 EvntLog_Energy "
Total Energy, used for energy based cut off function
";
CM_ SG_ 1328 EvntLog_BMS_Fan_Sts "0: Not Active, 1:Active";
CM_ SG_ 1328 EvntLog_BMS_PermFault_Sts "BMS permanent fault status

0: Not Active, 1:Active";
CM_ SG_ 1328 EvntLog_GPIO_OCCFaultSts "IO Status: 0: Low/Open & 1: High/Closed";
CM_ SG_ 1328 EvntLog_GPIO_ODCFaultSts "IO Status: 0: Low/Open & 1: High/Closed";
CM_ SG_ 1328 EvntLog_GPIO_UVFaultSts "IO Status: 0: Low/Open & 1: High/Closed";
CM_ SG_ 1328 EvntLog_GPIO_OVFaultSts "IO Status: 0: Low/Open & 1: High/Closed";
CM_ SG_ 1328 EvntLog_GPIO_OTFaultSts "IO Status: 0: Low/Open & 1: High/Closed";
CM_ SG_ 1328 EnvntLog_GPIO_TCOCP_Sts "IO Status: 0: Low/Open & 1: High/Closed";
CM_ SG_ 1328 EvntLog_SequenceNumber "
Sequence number for each NVM event logging starting from 1
";
CM_ SG_ 1328 EvntLog_FaultCounter "
Counter for each fault occurence/event which are getting logged
For Ex: If Cell UV is getting logged for 3rd time, this value should be 03.
Once counter reaches to 65535, keep the counter value at 65535 and keep logging. Do not reset to 0.
";
CM_ SG_ 1328 EvntLog_ResetReason_PWR_POR_RST "Power ON reset";
CM_ SG_ 1328 EvntLog_ResetReason_NRST "Pin Reset";
CM_ SG_ 1328 EvntLog_ResetReason_PWR_BOR_RST "Brownout reset";
CM_ SG_ 1328 EvntLog_Reset_Counter "
Counter is incremented by 1 for each reset

";
CM_ SG_ 1328 EvntLog_STS_EI_MCU_LPSONCMD "
status of external inputs to MCU-LPS ON Command


1: High/Closed; 0: Low/Open";
CM_ SG_ 1328 EvntLog_STS_EI_MCU_MechInterlock "
status of external inputs to MCU-Mechanical interlock


1: High/Closed; 0: Low/Open";
CM_ SG_ 1328 EvntLog_STS_EI_MCU_SRV_Dis "status of external inputs to MCU-Service disconnect switch

1: High/Closed; 0: Low/Open";
CM_ SG_ 1328 EvntLog_STS_EI_MCU_ON_BUTTONPRS "status of external inputs to MCU-On button press

1: High/Closed; 0: Low/Open";
CM_ SG_ 1328 EvntLog_ResetReason_SFTRESET "System reset generated by CPU";
CM_ SG_ 1328 EvntLog_ResetReason_CPURST "CPU Reset";
CM_ SG_ 1328 EvntLog_ResetReason_WWDG1_OutRST "WWDG1 reset";
CM_ SG_ 1328 EvntLog_ResetReason_IWDG1_OutRST "IWDG1 reset";
CM_ SG_ 1328 EvntLog_ResetReason_D1_Exit "Reset due to D1 exits DStandby mode";
CM_ SG_ 1328 EvntLog_ResetReason_D2_Exit "Reset due to D2 exits DStandby mode";
CM_ SG_ 1328 EvntLog_ResetReason_CSTOPMODE "D1 erroneously enters Dstandby mode or CPU erroneously enters Cstop mode";
CM_ SG_ 1328 Evntlog_CRC "16 bit CRC calculated on Byte1 to Byte62";
CM_ SG_ 1368 DIAGRESP_Op_ErrorCode "0x01 – Success,
0x02 – Conditions are not correct (Charge/discharge/autocharge are in progress and hence cannot execute)
0x03- Soc < 30%,
0x04 - Flash is busy – repeat the request
0x00 and 0x05 to 0xFF: reserved)";
CM_ BO_ 640 "UPS Data to XRCC for VRLA Management";
CM_ SG_ 640 VRLACFG_ResponseID "Request ID that this message is in reponse to (see SYSREQ_RequestID)";
CM_ BO_ 1152 "XRCC VRLA performance to UPS";
BA_DEF_  "BusType" STRING ;
BA_DEF_ SG_  "SystemSignalLongSymbol" STRING ;
BA_DEF_DEF_  "BusType" "";
BA_DEF_DEF_  "SystemSignalLongSymbol" "";
BA_ "BusType" "CAN";
BA_ "SystemSignalLongSymbol" SG_ 160 FWSend_FileStart_DestinationNode "FWSend_FileStart_DestinationNodeAddress";
BA_ "SystemSignalLongSymbol" SG_ 1280 DIAGSTS_ThermalSensorDisconnecte "DIAGSTS_ThermalSensorDisconnected";
BA_ "SystemSignalLongSymbol" SG_ 1304 DIAGRESP_FanProportionalTimeOnSe "DIAGRESP_FanProportionalTimeOnSec";
BA_ "SystemSignalLongSymbol" SG_ 1320 DIAGVERINFO_ParallelConfiguratio "DIAGVERINFO_ParallelConfiguration";
BA_ "SystemSignalLongSymbol" SG_ 1320 DIAGVERINFO_SoftwareAvailableMaj "DIAGVERINFO_SoftwareAvailableMajor";
BA_ "SystemSignalLongSymbol" SG_ 1320 DIAGVERINFO_SoftwareAvailableMin "DIAGVERINFO_SoftwareAvailableMinor";
BA_ "SystemSignalLongSymbol" SG_ 1320 DIAGVERINFO_SoftwareAvailableBui "DIAGVERINFO_SoftwareAvailableBuild";
BA_ "SystemSignalLongSymbol" SG_ 1320 DIAGVERINFO_BmFileTransferInProg "DIAGVERINFO_BmFileTransferInProgress";
BA_ "SystemSignalLongSymbol" SG_ 1320 DIAGVERINFO_BmFileTransferInveri "DIAGVERINFO_BmFileTransferInverify";
BA_ "SystemSignalLongSymbol" SG_ 1320 DIAGVERINFO_BmFileTraReadyInstal "DIAGVERINFO_BmFileTraReadyInstall";
BA_ "SystemSignalLongSymbol" SG_ 226 EvntLog_All_SinceLastTimeToReadO "EvntLog_All_SinceLastTimeToReadOut";
BA_ "SystemSignalLongSymbol" SG_ 1360 Batt_AddnlInfo_Rsp_RedCellTempMC "Batt_AddnlInfo_Rsp_RedCellTempMCUADC";
VAL_ 128 SYSREQ_RequestType 0 "Standard (MDAT)" 1 "Extended (MDAT, CDAT0 and CDAT1)" 2 "Detailed (MDAT, CDAT0-2)" 3 "Life (MDAT, LDAT)" 6 "Version info (VER only)" 7 "Vendor Private Only (VDAT only)" 4 "Detailed-C0 (CDAT0-1)" 5 "Detailed-C2 (CDAT2)" ;
VAL_ 256 VER_ProtocolVersion 1 "v20190306" 2 "v20191205" 3 "v20200117" 4 "v20200321" 5 "v20200414" 6 "v20200505" 7 "v20200506" 8 "v20200908" 9 "v20201007" 10 "v20210129" 15 "v20210305" 16 "v20210325" 17 "v20210407" 18 "v20210420" 19 "v20210530" 20 "v20210606" 21 "v20210613" 22 "v20210621" 23 "v20210630" 24 "v20210812" ;
VAL_ 256 VER_DesignCapacity 4095 "NO_VALUE" ;
VAL_ 256 VER_DesignVoltage 511 "NO_VALUE" ;
VAL_ 256 VER_DesignPower 65535 "NO_VALUE" ;
VAL_ 512 MDAT_VCellMax 0 "BELOW 500mv" 4000 "ABOVE 4500mv" 4094 "NO_VALUE" 4095 "ERROR" ;
VAL_ 512 MDAT_VCellMin 0 "BELOW 500mv" 4000 "ABOVE 4500mv" 4094 "NO_VALUE" 4095 "ERROR" ;
VAL_ 512 MDAT_VCellAvg 0 "BELOW 500mv" 4000 "ABOVE 4500mv" 4094 "NO_VALUE" 4095 "ERROR" ;
VAL_ 512 MDAT_ChargeVoltageRequest 4095 "NO_VALUE" ;
VAL_ 512 MDAT_ChargeCurrentMax 65535 "NO_VALUE" ;
VAL_ 768 CDAT0_Temperature_01 0 "BELOW -40C" 250 "ABOVE +210C" 253 "NO_VALUE" 254 "OPEN_CIRCUIT" 255 "SHORT_CIRCUIT" ;
VAL_ 768 CDAT0_Temperature_02 0 "BELOW -40C" 250 "ABOVE +210C" 253 "NO_VALUE" 254 "OPEN_CIRCUIT" 255 "SHORT_CIRCUIT" ;
VAL_ 768 CDAT0_Temperature_03 0 "BELOW -40C" 250 "ABOVE +210C" 253 "NO_VALUE" 254 "OPEN_CIRCUIT" 255 "SHORT_CIRCUIT" ;
VAL_ 768 CDAT0_Temperature_04 0 "BELOW -40C" 250 "ABOVE +210C" 253 "NO_VALUE" 254 "OPEN_CIRCUIT" 255 "SHORT_CIRCUIT" ;
VAL_ 768 CDAT0_Temperature_05 0 "BELOW -40C" 250 "ABOVE +210C" 253 "NO_VALUE" 254 "OPEN_CIRCUIT" 255 "SHORT_CIRCUIT" ;
VAL_ 768 CDAT0_Temperature_06 0 "BELOW -40C" 250 "ABOVE +210C" 253 "NO_VALUE" 254 "OPEN_CIRCUIT" 255 "SHORT_CIRCUIT" ;
VAL_ 768 CDAT0_Temperature_07 0 "BELOW -40C" 250 "ABOVE +210C" 253 "NO_VALUE" 254 "OPEN_CIRCUIT" 255 "SHORT_CIRCUIT" ;
VAL_ 768 CDAT0_Temperature_08 0 "BELOW -40C" 250 "ABOVE +210C" 253 "NO_VALUE" 254 "OPEN_CIRCUIT" 255 "SHORT_CIRCUIT" ;
VAL_ 768 CDAT0_Temperature_09 0 "BELOW -40C" 250 "ABOVE +210C" 253 "NO_VALUE" 254 "OPEN_CIRCUIT" 255 "SHORT_CIRCUIT" ;
VAL_ 1024 CDAT2_VCell_1 0 "BELOW 500mv" 4000 "ABOVE 4500mv" 4094 "NO_VALUE" 4095 "ERROR" ;
VAL_ 1024 CDAT2_VCell_2 0 "BELOW 500mv" 4000 "ABOVE 4500mv" 4094 "NO_VALUE" 4095 "ERROR" ;
VAL_ 1024 CDAT2_VCell_3 0 "BELOW 500mv" 4000 "ABOVE 4500mv" 4094 "NO_VALUE" 4095 "ERROR" ;
VAL_ 1024 CDAT2_VCell_4 0 "BELOW 500mv" 4000 "ABOVE 4500mv" 4094 "NO_VALUE" 4095 "ERROR" ;
VAL_ 1024 CDAT2_VCell_5 0 "BELOW 500mv" 4000 "ABOVE 4500mv" 4094 "NO_VALUE" 4095 "ERROR" ;
VAL_ 1024 CDAT2_VCell_6 0 "BELOW 500mv" 4000 "ABOVE 4500mv" 4094 "NO_VALUE" 4095 "ERROR" ;
VAL_ 1024 CDAT2_VCell_7 0 "BELOW 500mv" 4000 "ABOVE 4500mv" 4094 "NO_VALUE" 4095 "ERROR" ;
VAL_ 1024 CDAT2_VCell_8 0 "BELOW 500mv" 4000 "ABOVE 4500mv" 4094 "NO_VALUE" 4095 "ERROR" ;
VAL_ 1024 CDAT2_VCell_9 0 "BELOW 500mv" 4000 "ABOVE 4500mv" 4094 "NO_VALUE" 4095 "ERROR" ;
VAL_ 1024 CDAT2_VCell_10 0 "BELOW 500mv" 4000 "ABOVE 4500mv" 4094 "NO_VALUE" 4095 "ERROR" ;
VAL_ 1024 CDAT2_VCell_11 0 "BELOW 500mv" 4000 "ABOVE 4500mv" 4094 "NO_VALUE" 4095 "ERROR" ;
VAL_ 1024 CDAT2_VCell_12 0 "BELOW 500mv" 4000 "ABOVE 4500mv" 4094 "NO_VALUE" 4095 "ERROR" ;
VAL_ 1024 CDAT2_VCell_13 0 "BELOW 500mv" 4000 "ABOVE 4500mv" 4094 "NO_VALUE" 4095 "ERROR" ;
VAL_ 1024 CDAT2_VCell_14 0 "BELOW 500mv" 4000 "ABOVE 4500mv" 4094 "NO_VALUE" 4095 "ERROR" ;
VAL_ 1024 CDAT2_VCell_15 0 "BELOW 500mv" 4000 "ABOVE 4500mv" 4094 "NO_VALUE" 4095 "ERROR" ;
VAL_ 1024 CDAT2_VCell_16 0 "BELOW 500mv" 4000 "ABOVE 4500mv" 4094 "NO_VALUE" 4095 "ERROR" ;
VAL_ 1024 CDAT2_VCell_17 0 "BELOW 500mv" 4000 "ABOVE 4500mv" 4094 "NO_VALUE" 4095 "ERROR" ;
VAL_ 1024 CDAT2_VCell_18 0 "BELOW 500mv" 4000 "ABOVE 4500mv" 4094 "NO_VALUE" 4095 "ERROR" ;
VAL_ 1024 CDAT2_VCell_19 0 "BELOW 500mv" 4000 "ABOVE 4500mv" 4094 "NO_VALUE" 4095 "ERROR" ;
VAL_ 1024 CDAT2_VCell_20 0 "BELOW 500mv" 4000 "ABOVE 4500mv" 4094 "NO_VALUE" 4095 "ERROR" ;
VAL_ 1024 CDAT2_VCell_21 0 "BELOW 500mv" 4000 "ABOVE 4500mv" 4094 "NO_VALUE" 4095 "ERROR" ;
VAL_ 1024 CDAT2_VCell_22 0 "BELOW 500mv" 4000 "ABOVE 4500mv" 4094 "NO_VALUE" 4095 "ERROR" ;
VAL_ 1024 CDAT2_VCell_23 0 "BELOW 500mv" 4000 "ABOVE 4500mv" 4094 "NO_VALUE" 4095 "ERROR" ;
VAL_ 1024 CDAT2_VCell_24 0 "BELOW 500mv" 4000 "ABOVE 4500mv" 4094 "NO_VALUE" 4095 "ERROR" ;
VAL_ 1024 CDAT2_VCell_25 0 "BELOW 500mv" 4000 "ABOVE 4500mv" 4094 "NO_VALUE" 4095 "ERROR" ;
VAL_ 1024 CDAT2_VCell_26 0 "BELOW 500mv" 4000 "ABOVE 4500mv" 4094 "NO_VALUE" 4095 "ERROR" ;
VAL_ 1024 CDAT2_VCell_27 0 "BELOW 500mv" 4000 "ABOVE 4500mv" 4094 "NO_VALUE" 4095 "ERROR" ;
VAL_ 1024 CDAT2_VCell_28 0 "BELOW 500mv" 4000 "ABOVE 4500mv" 4094 "NO_VALUE" 4095 "ERROR" ;
VAL_ 1024 CDAT2_VCell_29 0 "BELOW 500mv" 4000 "ABOVE 4500mv" 4094 "NO_VALUE" 4095 "ERROR" ;
VAL_ 1024 CDAT2_VCell_30 0 "BELOW 500mv" 4000 "ABOVE 4500mv" 4094 "NO_VALUE" 4095 "ERROR" ;
VAL_ 1024 CDAT2_VCell_31 0 "BELOW 500mv" 4000 "ABOVE 4500mv" 4094 "NO_VALUE" 4095 "ERROR" ;
VAL_ 1024 CDAT2_VCell_32 0 "BELOW 500mv" 4000 "ABOVE 4500mv" 4094 "NO_VALUE" 4095 "ERROR" ;
VAL_ 1024 CDAT2_VCell_33 0 "BELOW 500mv" 4000 "ABOVE 4500mv" 4094 "NO_VALUE" 4095 "ERROR" ;
VAL_ 1024 CDAT2_VCell_34 0 "BELOW 500mv" 4000 "ABOVE 4500mv" 4094 "NO_VALUE" 4095 "ERROR" ;
VAL_ 1024 CDAT2_VCell_35 0 "BELOW 500mv" 4000 "ABOVE 4500mv" 4094 "NO_VALUE" 4095 "ERROR" ;
VAL_ 1024 CDAT2_VCell_36 0 "BELOW 500mv" 4000 "ABOVE 4500mv" 4094 "NO_VALUE" 4095 "ERROR" ;
VAL_ 1024 CDAT2_VCell_37 0 "BELOW 500mv" 4000 "ABOVE 4500mv" 4094 "NO_VALUE" 4095 "ERROR" ;
VAL_ 1024 CDAT2_VCell_38 0 "BELOW 500mv" 4000 "ABOVE 4500mv" 4094 "NO_VALUE" 4095 "ERROR" ;
VAL_ 1024 CDAT2_VCell_39 0 "BELOW 500mv" 4000 "ABOVE 4500mv" 4094 "NO_VALUE" 4095 "ERROR" ;
VAL_ 1024 CDAT2_VCell_40 0 "BELOW 500mv" 4000 "ABOVE 4500mv" 4094 "NO_VALUE" 4095 "ERROR" ;
VAL_ 1024 CDAT2_VCell_41 0 "BELOW 500mv" 4000 "ABOVE 4500mv" 4094 "NO_VALUE" 4095 "ERROR" ;
VAL_ 1024 CDAT2_VCell_42 0 "BELOW 500mv" 4000 "ABOVE 4500mv" 4094 "NO_VALUE" 4095 "ERROR" ;
VAL_ 1024 CDAT2_VCell_43 0 "BELOW 500mv" 4000 "ABOVE 4500mv" 4094 "NO_VALUE" 4095 "ERROR" ;
VAL_ 1024 CDAT2_VCell_44 0 "BELOW 500mv" 4000 "ABOVE 4500mv" 4094 "NO_VALUE" 4095 "ERROR" ;
VAL_ 1024 CDAT2_VCell_45 0 "BELOW 500mv" 4000 "ABOVE 4500mv" 4094 "NO_VALUE" 4095 "ERROR" ;
VAL_ 1024 CDAT2_VCell_46 0 "BELOW 500mv" 4000 "ABOVE 4500mv" 4094 "NO_VALUE" 4095 "ERROR" ;
VAL_ 1024 CDAT2_VCell_47 0 "BELOW 500mv" 4000 "ABOVE 4500mv" 4094 "NO_VALUE" 4095 "ERROR" ;
VAL_ 1024 CDAT2_VCell_48 0 "BELOW 500mv" 4000 "ABOVE 4500mv" 4094 "NO_VALUE" 4095 "ERROR" ;
VAL_ 1024 CDAT2_VCell_49 0 "BELOW 500mv" 4000 "ABOVE 4500mv" 4094 "NO_VALUE" 4095 "ERROR" ;
VAL_ 1024 CDAT2_VCell_50 0 "BELOW 500mv" 4000 "ABOVE 4500mv" 4094 "NO_VALUE" 4095 "ERROR" ;
VAL_ 1920 VDAT_EOC 0 "EOC not reached" 1 "EOC reached" ;
VAL_ 1792 LDAT_CellVoltage_Min 0 "BELOW 500mv" 4000 "ABOVE 4500mv" 4094 "NO_VALUE" 4095 "ERROR" ;
VAL_ 1792 LDAT_CellVoltage_Max 0 "BELOW 500mv" 4000 "ABOVE 4500mv" 4094 "NO_VALUE" 4095 "ERROR" ;
VAL_ 1792 LDAT_Temperature_Max 0 "BELOW -40C" 250 "ABOVE +210C" 253 "NO_VALUE" 254 "OPEN_CIRCUIT" 255 "SHORT_CIRCUIT" ;
VAL_ 1792 LDAT_Temperature_Min 0 "BELOW -40C" 250 "ABOVE +210C" 253 "NO_VALUE" 254 "OPEN_CIRCUIT" 255 "SHORT_CIRCUIT" ;
VAL_ 1792 LDAT_ChargePower_Max 65535 "NO_VALUE" ;
VAL_ 1792 LDAT_Temperature_Avg 0 "BELOW -40C" 250 "ABOVE +210C" 253 "NO_VALUE" 254 "OPEN_CIRCUIT" 255 "SHORT_CIRCUIT" ;
VAL_ 1792 LDAT_DischargePower_Max 65535 "NO_VALUE" ;
VAL_ 176 NodeAddress 255 "Broadcast Address" ;
VAL_ 144 AUXREQ_RequestType 1 "SendChallenge" 2 "GetCertPart1" 3 "GetCertPart2" 4 "GetUID" 5 "GetChallengeResponse" 10 "SetTimeOut" ;
VAL_ 144 AUXREQ_RequestNParameters 0 "No parameter" 1 "Parameter0_Valid" 2 "Parameter0_1_Valid" 3 "Parameter0_1_2_Valid" 4 "Parameter0_1_2_3_Valid" 5 "Parameter0_1_2_3_4_Valid" 6 "Parameter0to5_Valid" 7 "Parameter0to6_Valid" 8 "Parameter0to7_Valid" 9 "Parameter0to8_Valid" 10 "Parameter0to9_Valid" 11 "Parameter0to10_Valid" 12 "Parameter0to11_Valid" 13 "Parameter0to12_Valid" 14 "Parameter0to13_Valid" 15 "Parameter0to4_Valid" 16 "Parameter0to15_Valid" ;
VAL_ 144 AUXREQ_RequestTargetNodeAddress 255 "Everyone" ;
VAL_ 1664 AUXRESP_ResponseNParameters 0 "No parameter" 1 "Parameter0_Valid" 2 "Parameter0_1_Valid" 3 "Parameter0_1_2_Valid" 4 "Parameter0_1_2_3_Valid" 5 "Parameter0_1_2_3_4_Valid" 6 "Parameter0to5_Valid" 7 "Parameter0to6_Valid" 8 "Parameter0to7_Valid" 9 "Parameter0to8_Valid" 10 "Parameter0to9_Valid" 11 "Parameter0to10_Valid" 12 "Parameter0to11_Valid" 13 "Parameter0to12_Valid" 14 "Parameter0to13_Valid" 15 "Parameter0to14_Valid" 16 "Parameter0to15_Valid" ;
VAL_ 1664 AUXRESP_ResponseErrorType 1 "Incompleted challenge code" 2 "Failed to write to A1006" 3 "Failed to read from A1006" 4 "Challenge code time out" ;
VAL_ 241 CFGCMD_ReauestType 1 "FANPWM" 2 "RUNTIMECALSET" 3 "RUNTIMECALRESET" 4 "CLEARFAULT" 5 "FORCEFAULT" 6 "WRITEVENDORCODE" 7 "IN_SERVICE_DATE" 8 "ATTACHED_UPS_SKU" 9 "RMA_SN_1ST2BYTES" 10 "RMA_SN_3TO7BYTES" 11 "RMA_SN_8TO12BYTES" 12 "RMA_SN_LST4BYTES" 13 "PROJECT_BM_CURRENT" ;
VAL_ 242 EVENTLOG_RequestType 1 "Last 1" 2 "Last 10" 4 "Last 100" 8 "Rewind" 16 "Recent (Seconds)" 64 "All" 128 "Abort" 254 "Erase" ;
VAL_ 224 CFGCMD2_RequestType 0 "Manufacturing details" 1 "Serial number" 2 " Part number" 3 "Key" 4 "RTC" 5 "Vendor code" 6 "Attached UPS SKU" 255 "SW_Protection_Modification" ;
VAL_ 225 DIAGREQ_RequestType 0 "DIAGSTS" 1 "DIAGAFE" 2 "DIAGAFECELL" 3 "DIAGRESP" 4 "DIAGCSTS" 5 "VERINFO" ;
VAL_ 1304 DIAGRESP_Batterystatus 1 "Enabled(close)" 0 "Disabled(Close)" ;
VAL_ 1320 DIAGVERINFO_ProtocolVersion 1 "v20190306" 2 "v20191205" 3 "v20200117" 4 "v20200321" 5 "v20200414" 6 "v20200505" 7 "v20200506" 8 "v20200908" 9 "v20201007" 10 "v20210129" 15 "v20210305" 16 "v20210325" 17 "v20210407" 18 "v20210420" 19 "v20210530" 20 "v20210606" 21 "v20210613" 22 "v20210621" 23 "v20210630" 24 "v20210812" ;
VAL_ 227 SessionReq_RequestType 0 "Vendor verification" 1 "Provide seed" 2 "Key verification" 3 "Start session" 4 "End session" 5 "Session status" ;
VAL_ 1336 SessionResp_ResponseErrorType 0 "vendor verified" 1 "vendor invalid" 2 "key verified" 3 "key invalid" 4 "session started" 5 "session in progress" 6 "session end" 255 "session timeout" ;
VAL_ 1336 SessionResp_ResponseParameter 1 " Provide seedkey" 2 "Provide session ID" ;
VAL_ 226 EvntLog_All_Rq_RequestType 1 "Last 1" 2 "Last 10" 4 "Last 100" 8 "Rewind" 16 "Recent (Seconds)" 64 "All" 128 "Abort" 254 "Erase" ;
VAL_ 1352 SFlash_Integrity_STS 0 "Integrity check failed" 1 "Integrity check passed" ;
VAL_ 228 BattInf_Rq_RequestType 0 "BattInf_Fault_Rq" 1 "BattInf_StsInfo_Rq" 2 "Batt_AddnlInfo_Rq" ;
VAL_ 229 DIAGREQ_Op_RequestType 1 "MCU RESET" 2 "BMS Sleep" 3 "ClrPermFStatus" ;
VAL_ 1328 EvntLog_EraseResp 0 "Reserved" 1 "EraseSuccess" 2 "Erase failed" 3 "Busy-RepeatReq" ;
VAL_ 1328 EvntLog_BMS_AFE1Fault_Sts 0 "No AFE1 Fault" 1 "AFE1 Fault" ;
VAL_ 1328 EvntLog_BMS_AFE2Fault_Sts 0 "No AFE2 Fault" 1 "AFE2 Fault" ;
VAL_ 1328 EvntLog_BMS_AFE3Fault_Sts 0 "No AFE3 Fault" 1 "No AFE3 Fault" ;
VAL_ 1328 EvntLog_BMS_AFE4Fault_Sts 0 "No AFE4 Fault" 1 "AFE4 Fault" ;
VAL_ 1368 DIAGRESP_Op_ResponseType 1 "MCUReset" 2 "BMS Sleep" 3 "ClrPermFStatus" ;
VAL_ 1368 DIAGRESP_Op_ErrorCode 1 "Success" 2 "ConditionsIncorrect" 3 "SoC<30%" 4 "FlashBusy-RepeatReq" 0 "Reserved" ;
